VERSION ""

NS_ :

BS_:

BU_: TestTool_HS BCP_HS ECM_HS TCM_HS CGM_HS BCM_HS EBCM_OBD_HS ACCM_HS EBCM_HS TCCM_HS SAS_HS ICCM_OBD_HS ICCM_HS EPS_HS EPB_HS HMIM_HS ONSTAR_HS

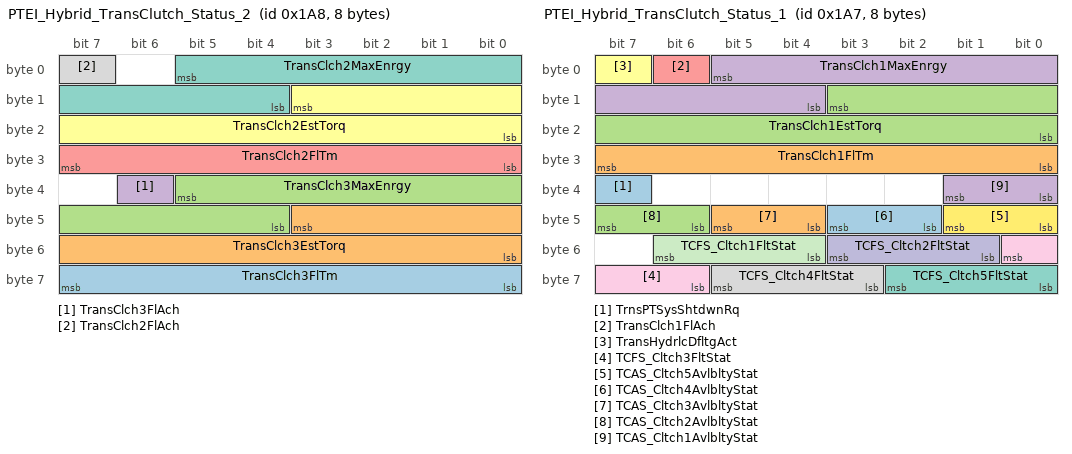
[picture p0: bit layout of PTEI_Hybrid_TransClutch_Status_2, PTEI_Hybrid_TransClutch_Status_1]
BO_ 424 PTEI_Hybrid_TransClutch_Status_2: 8 TCM_HS
 SG_ TransClch3FlTm : 63|8@0+ (0.0125,0) [0|3.1875] "s" Vector__XXX
 SG_ TransClch3EstTorq : 43|12@0+ (0.5,-5) [-5|2042.5] "Nm" Vector__XXX
 SG_ TransClch3MaxEnrgy : 37|10@0+ (50,0) [0|51150] "J" Vector__XXX
 SG_ TransClch3FlAch : 38|1@0+ (1,0) [0|1] "" Vector__XXX
 SG_ TransClch2FlTm : 31|8@0+ (0.0125,0) [0|3.1875] "s" Vector__XXX
 SG_ TransClch2EstTorq : 11|12@0+ (0.5,-5) [-5|2042.5] "Nm" Vector__XXX
 SG_ TransClch2MaxEnrgy : 5|10@0+ (50,0) [0|51150] "J" Vector__XXX
 SG_ TransClch2FlAch : 7|1@0+ (1,0) [0|1] "" Vector__XXX

BO_ 423 PTEI_Hybrid_TransClutch_Status_1: 8 TCM_HS
 SG_ TrnsPTSysShtdwnRq : 39|1@0+ (1,0) [0|1] "" Vector__XXX
 SG_ TransClch1FlTm : 31|8@0+ (0.0125,0) [0|3.1875] "s" Vector__XXX
 SG_ TransClch1EstTorq : 11|12@0+ (0.5,-5) [-5|2042.5] "Nm" Vector__XXX
 SG_ TransClch1MaxEnrgy : 5|10@0+ (50,0) [0|51150] "J" Vector__XXX
 SG_ TransClch1FlAch : 6|1@0+ (1,0) [0|1] "" Vector__XXX
 SG_ TransHydrlcDfltgAct : 7|1@0+ (1,0) [0|1] "" Vector__XXX
 SG_ TCFS_Cltch5FltStat : 58|3@0+ (1,0) [0|7] "" Vector__XXX
 SG_ TCFS_Cltch4FltStat : 61|3@0+ (1,0) [0|7] "" Vector__XXX
 SG_ TCFS_Cltch3FltStat : 48|3@0+ (1,0) [0|7] "" Vector__XXX
 SG_ TCFS_Cltch2FltStat : 51|3@0+ (1,0) [0|7] "" Vector__XXX
 SG_ TCFS_Cltch1FltStat : 54|3@0+ (1,0) [0|7] "" Vector__XXX
 SG_ TCAS_Cltch5AvlbltyStat : 41|2@0+ (1,0) [0|3] "" Vector__XXX
 SG_ TCAS_Cltch4AvlbltyStat : 43|2@0+ (1,0) [0|3] "" Vector__XXX
 SG_ TCAS_Cltch3AvlbltyStat : 45|2@0+ (1,0) [0|3] "" Vector__XXX
 SG_ TCAS_Cltch2AvlbltyStat : 47|2@0+ (1,0) [0|3] "" Vector__XXX
 SG_ TCAS_Cltch1AvlbltyStat : 33|2@0+ (1,0) [0|3] "" Vector__XXX

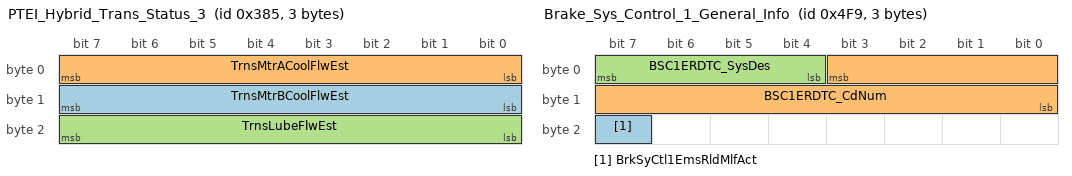
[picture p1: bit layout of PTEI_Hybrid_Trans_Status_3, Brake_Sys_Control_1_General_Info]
BO_ 901 PTEI_Hybrid_Trans_Status_3: 3 TCM_HS
 SG_ TrnsMtrBCoolFlwEst : 15|8@0+ (0.05,0) [0|12.75] "l/min" Vector__XXX
 SG_ TrnsMtrACoolFlwEst : 7|8@0+ (0.05,0) [0|12.75] "l/min" Vector__XXX
 SG_ TrnsLubeFlwEst : 23|8@0+ (0.0625,0) [0|15.9375] "l/min" Vector__XXX

BO_ 1919 DTC_Triggered_77F: 7 TCM_HS
 SG_ DTCI_DTCFaultType_77F : 55|8@0+ (1,0) [0|255] ""  CGM_HS,HMIM_HS,ONSTAR_HS
 SG_ DTCI_CodeSupported_77F : 40|1@0+ (1,0) [0|1] ""  CGM_HS,HMIM_HS,ONSTAR_HS
 SG_ DTCI_CurrentStatus_77F : 41|1@0+ (1,0) [0|1] ""  CGM_HS,HMIM_HS,ONSTAR_HS
 SG_ DTCI_TstNPsdCdClrdSt_77F : 42|1@0+ (1,0) [0|1] ""  CGM_HS,HMIM_HS,ONSTAR_HS
 SG_ DTCI_TstFldCdClrdStat_77F : 43|1@0+ (1,0) [0|1] ""  CGM_HS,HMIM_HS,ONSTAR_HS
 SG_ DTCI_HistStat_77F : 44|1@0+ (1,0) [0|1] ""  CGM_HS,HMIM_HS,ONSTAR_HS
 SG_ DTCI_TstNPsdPwrUpSt_77F : 45|1@0+ (1,0) [0|1] ""  CGM_HS,HMIM_HS,ONSTAR_HS
 SG_ DTCI_TstFldPwrUpSt_77F : 46|1@0+ (1,0) [0|1] ""  CGM_HS,HMIM_HS,ONSTAR_HS
 SG_ DTCI_WrnIndRqdSt_77F : 47|1@0+ (1,0) [0|1] ""  CGM_HS,HMIM_HS,ONSTAR_HS
 SG_ DTCI_DTCFailType_77F : 39|8@0+ (1,0) [0|255] ""  CGM_HS,HMIM_HS,ONSTAR_HS
 SG_ DTCI_DTCNumber_77F : 23|16@0+ (1,0) [0|65535] ""  CGM_HS,HMIM_HS,ONSTAR_HS
 SG_ DTCI_DTCSource_77F : 15|8@0+ (1,0) [0|255] ""  CGM_HS,HMIM_HS,ONSTAR_HS
 SG_ DTCI_DTCTriggered_77F : 0|1@0+ (1,0) [0|1] ""  CGM_HS,HMIM_HS,ONSTAR_HS
 SG_ DTCIUnused7_77F : 1|1@0+ (1,0) [0|1] ""  CGM_HS,HMIM_HS,ONSTAR_HS
 SG_ DTCIUnused6_77F : 2|1@0+ (1,0) [0|1] ""  CGM_HS,HMIM_HS,ONSTAR_HS
 SG_ DTCIUnused5_77F : 3|1@0+ (1,0) [0|1] ""  CGM_HS,HMIM_HS,ONSTAR_HS
 SG_ DTCIUnused4_77F : 4|1@0+ (1,0) [0|1] ""  CGM_HS,HMIM_HS,ONSTAR_HS
 SG_ DTCIUnused3_77F : 5|1@0+ (1,0) [0|1] ""  CGM_HS,HMIM_HS,ONSTAR_HS
 SG_ DTCIUnused2_77F : 6|1@0+ (1,0) [0|1] ""  CGM_HS,HMIM_HS,ONSTAR_HS
 SG_ DTCIUnused1_77F : 7|1@0+ (1,0) [0|1] ""  CGM_HS,HMIM_HS,ONSTAR_HS

BO_ 2026 USDT_Resp_From_TCM_MTA_MTIO_HS: 8 TCM_HS
 SG_ DgnInf : 7|64@0+ (1,0) [0|1.84467440737096E+019] ""  CGM_HS,TestTool_HS,ONSTAR_HS

BO_ 1514 UUDT_Resp_From_TCM_MTA_MTIO_HS: 8 TCM_HS
 SG_ DgnInf : 7|64@0+ (1,0) [0|1.84467440737096E+019] ""  CGM_HS,TestTool_HS,ONSTAR_HS

BO_ 1273 Brake_Sys_Control_1_General_Info: 3 EBCM_HS
 SG_ BrkSyCtl1EmsRldMlfAct : 23|1@0+ (1,0) [0|1] ""  ECM_HS
 SG_ BSC1ERDTC_CdNum : 3|12@0+ (1,0) [0|4095] ""  ECM_HS
 SG_ BSC1ERDTC_SysDes : 7|4@0+ (1,0) [0|15] ""  ECM_HS

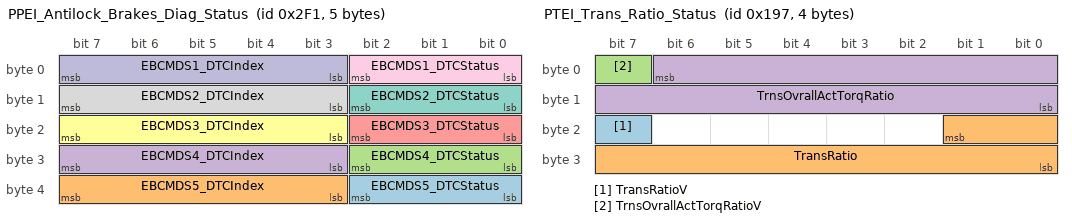
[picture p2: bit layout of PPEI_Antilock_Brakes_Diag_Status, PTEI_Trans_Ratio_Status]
BO_ 753 PPEI_Antilock_Brakes_Diag_Status: 5 EBCM_HS
 SG_ EBCMDS5_DTCStatus : 34|3@0+ (1,0) [0|7] ""  ECM_HS
 SG_ EBCMDS5_DTCIndex : 39|5@0+ (1,0) [0|31] ""  ECM_HS
 SG_ EBCMDS4_DTCStatus : 26|3@0+ (1,0) [0|7] ""  ECM_HS
 SG_ EBCMDS4_DTCIndex : 31|5@0+ (1,0) [0|31] ""  ECM_HS
 SG_ EBCMDS3_DTCStatus : 18|3@0+ (1,0) [0|7] ""  ECM_HS
 SG_ EBCMDS3_DTCIndex : 23|5@0+ (1,0) [0|31] ""  ECM_HS
 SG_ EBCMDS2_DTCStatus : 10|3@0+ (1,0) [0|7] ""  ECM_HS
 SG_ EBCMDS2_DTCIndex : 15|5@0+ (1,0) [0|31] ""  ECM_HS
 SG_ EBCMDS1_DTCStatus : 2|3@0+ (1,0) [0|7] ""  ECM_HS
 SG_ EBCMDS1_DTCIndex : 7|5@0+ (1,0) [0|31] ""  ECM_HS

BO_ 407 PTEI_Trans_Ratio_Status: 4 TCM_HS
 SG_ TransRatioV : 23|1@0+ (1,0) [0|1] ""  ECM_HS
 SG_ TransRatio : 17|10@0+ (0.03125,0) [0|31.96875] ""  ECM_HS
 SG_ TrnsOvrallActTorqRatioV : 7|1@0+ (1,0) [0|1] ""  ECM_HS
 SG_ TrnsOvrallActTorqRatio : 6|15@0- (0.00390625,0) [-64|63.99609375] ""  ECM_HS

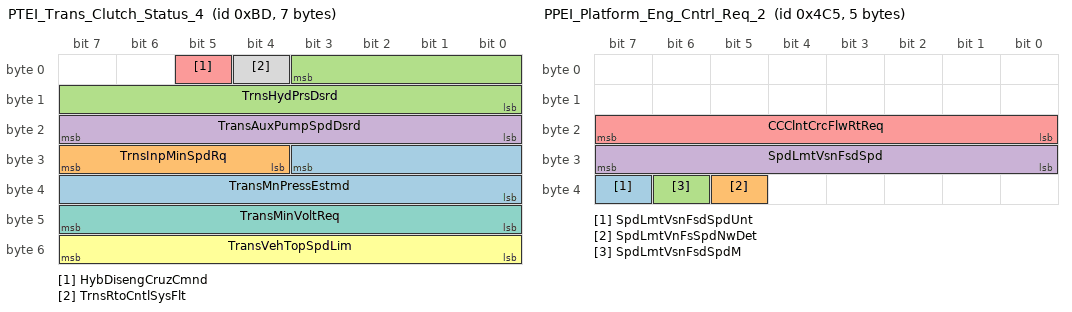
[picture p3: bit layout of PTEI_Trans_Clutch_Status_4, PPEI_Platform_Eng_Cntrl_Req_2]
BO_ 189 PTEI_Trans_Clutch_Status_4: 7 TCM_HS
 SG_ TransMnPressEstmd : 27|12@0+ (0.5,0) [0|2047.5] "kPa"  CGM_HS
 SG_ TrnsInpMinSpdRq : 31|4@0+ (1,0) [0|15] ""  CGM_HS
 SG_ TrnsHydPrsDsrd : 3|12@0+ (0.5,0) [0|2047.5] "kPa"  CGM_HS
 SG_ TransAuxPumpSpdDsrd : 23|8@0+ (0.392157,0) [0|100.000035] "%"  CGM_HS
 SG_ HybDisengCruzCmnd : 5|1@0+ (1,0) [0|1] ""  CGM_HS,ECM_HS
 SG_ TransVehTopSpdLim : 55|8@0+ (2,0) [0|510] "km / h"  CGM_HS,ECM_HS
 SG_ TransMinVoltReq : 47|8@0+ (0.07843,0) [0|19.99965] "volts"  CGM_HS,ECM_HS
 SG_ TrnsRtoCntlSysFlt : 4|1@0+ (1,0) [0|1] ""  CGM_HS,ECM_HS

BO_ 1221 PPEI_Platform_Eng_Cntrl_Req_2: 5 BCM_HS
 SG_ SpdLmtVsnFsdSpdUnt : 39|1@0+ (1,0) [0|1] ""  CGM_HS,ECM_HS
 SG_ SpdLmtVnFsSpdNwDet : 37|1@0+ (1,0) [0|1] ""  CGM_HS,ECM_HS
 SG_ SpdLmtVsnFsdSpdM : 38|1@0+ (1,0) [0|1] ""  CGM_HS,ECM_HS
 SG_ SpdLmtVsnFsdSpd : 31|8@0+ (1,0) [0|255] ""  CGM_HS,ECM_HS
 SG_ CCClntCrcFlwRtReq : 23|8@0+ (0.392157,0) [0|100.000035] "%"  CGM_HS,ECM_HS

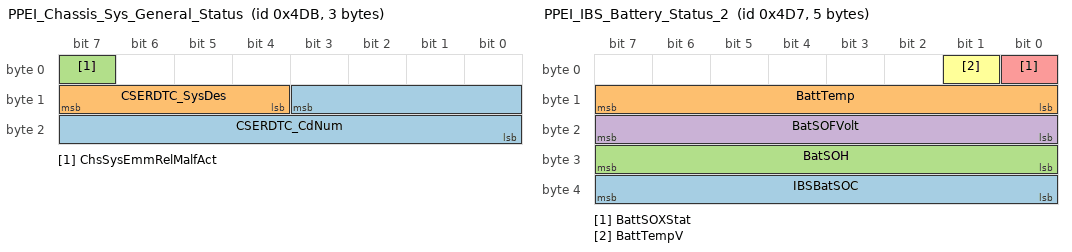
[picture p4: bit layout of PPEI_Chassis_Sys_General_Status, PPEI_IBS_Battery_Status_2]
BO_ 1243 PPEI_Chassis_Sys_General_Status: 3 ICCM_HS
 SG_ CSERDTC_CdNum : 11|12@0+ (1,0) [0|4095] ""  ECM_HS
 SG_ CSERDTC_SysDes : 15|4@0+ (1,0) [0|15] ""  ECM_HS
 SG_ ChsSysEmmRelMalfAct : 7|1@0+ (1,0) [0|1] ""  ECM_HS

BO_ 1239 PPEI_IBS_Battery_Status_2: 5 BCM_HS
 SG_ IBSBatSOC : 39|8@0+ (0.392157,0) [0|100.000035] "%"  ECM_HS
 SG_ BattTemp : 15|8@0+ (1,-40) [-40|215] "deg C"  ECM_HS
 SG_ BatSOH : 31|8@0+ (0.392157,0) [0|100.000035] "%"  ECM_HS
 SG_ BatSOFVolt : 23|8@0+ (0.05,0) [0|12.75] "volts"  ECM_HS
 SG_ BattSOXStat : 0|1@0+ (1,0) [0|1] ""  ECM_HS
 SG_ BattTempV : 1|1@0+ (1,0) [0|1] ""  ECM_HS

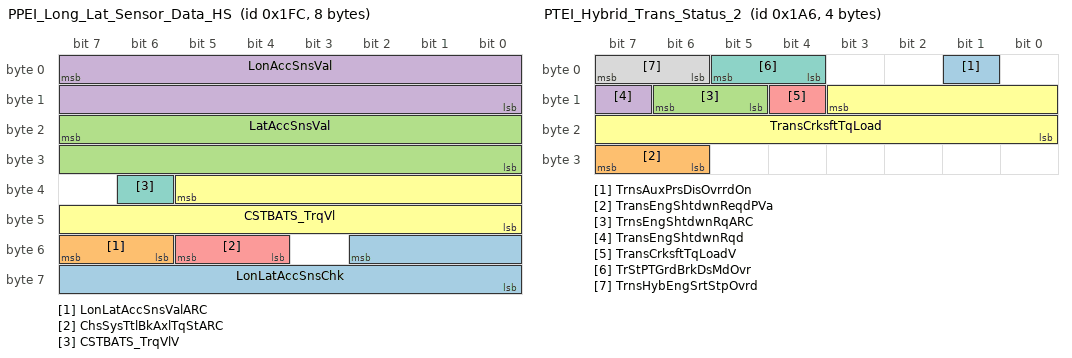
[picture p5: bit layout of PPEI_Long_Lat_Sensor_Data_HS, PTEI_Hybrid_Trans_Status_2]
BO_ 508 PPEI_Long_Lat_Sensor_Data_HS: 8 EBCM_HS
 SG_ LonLatAccSnsChk : 50|11@0+ (1,0) [0|2047] ""  ICCM_OBD_HS,ICCM_HS,TCM_HS,ECM_HS
 SG_ LonLatAccSnsValARC : 55|2@0+ (1,0) [0|3] ""  ICCM_OBD_HS,ICCM_HS,TCM_HS,ECM_HS
 SG_ LatAccSnsVal : 23|16@0- (0.00012207,0) [-3.99998976|3.99986769] "g's"  ICCM_OBD_HS,ICCM_HS,TCM_HS,ECM_HS
 SG_ LonAccSnsVal : 7|16@0- (0.00012207,0) [-3.99998976|3.99986769] "g's"  ICCM_OBD_HS,ICCM_HS,TCM_HS,ECM_HS
 SG_ ChsSysTtlBkAxlTqStARC : 53|2@0+ (1,0) [0|3] ""  ECM_HS
 SG_ CSTBATS_TrqVl : 37|14@0+ (2,0) [0|32766] "Nm"  ICCM_OBD_HS,ICCM_HS,TCM_HS,ECM_HS
 SG_ CSTBATS_TrqVlV : 38|1@0+ (1,0) [0|1] ""  ICCM_OBD_HS,ICCM_HS,TCM_HS,ECM_HS

BO_ 422 PTEI_Hybrid_Trans_Status_2: 4 TCM_HS
 SG_ TrnsAuxPrsDisOvrrdOn : 1|1@0+ (1,0) [0|1] ""  ECM_HS
 SG_ TransEngShtdwnReqdPVa : 31|2@0+ (1,0) [0|3] ""  ECM_HS
 SG_ TrnsEngShtdwnRqARC : 14|2@0+ (1,0) [0|3] ""  ECM_HS
 SG_ TransEngShtdwnRqd : 15|1@0+ (1,0) [0|1] ""  ECM_HS
 SG_ TransCrksftTqLoadV : 12|1@0+ (1,0) [0|1] ""  ECM_HS
 SG_ TransCrksftTqLoad : 11|12@0+ (0.5,-848) [-848|1199.5] "Nm"  ECM_HS
 SG_ TrStPTGrdBrkDsMdOvr : 5|2@0+ (1,0) [0|3] ""  ECM_HS
 SG_ TrnsHybEngSrtStpOvrd : 7|2@0+ (1,0) [0|3] ""  BCP_HS,ECM_HS

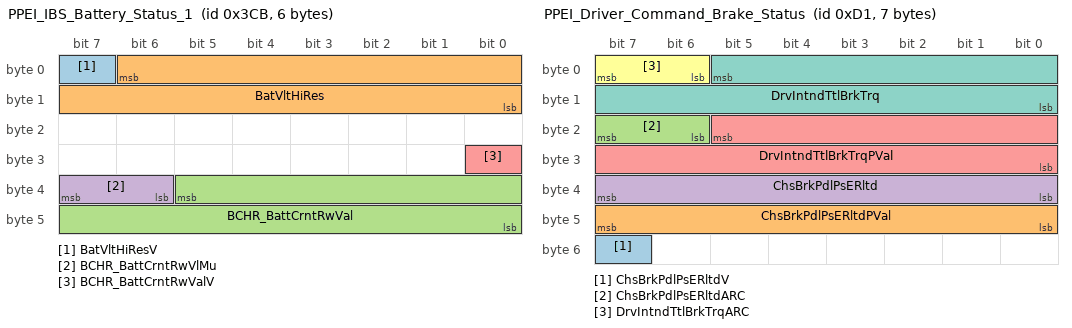
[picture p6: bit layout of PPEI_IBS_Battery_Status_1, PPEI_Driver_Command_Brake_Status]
BO_ 971 PPEI_IBS_Battery_Status_1: 6 BCM_HS
 SG_ BatVltHiResV : 7|1@0+ (1,0) [0|1] ""  ECM_HS
 SG_ BatVltHiRes : 6|15@0+ (0.001,0) [0|32.767] "volts"  ECM_HS
 SG_ BCHR_BattCrntRwVal : 37|14@0+ (0.001,-8.192) [-8.192|8.191] ""  ECM_HS
 SG_ BCHR_BattCrntRwVlMu : 39|2@0+ (1,0) [0|3] ""  ECM_HS
 SG_ BCHR_BattCrntRwValV : 24|1@0+ (1,0) [0|1] ""  ECM_HS

BO_ 209 PPEI_Driver_Command_Brake_Status: 7 EBCM_HS
 SG_ ChsBrkPdlPsERltdV : 55|1@0+ (1,0) [0|1] ""  ECM_HS
 SG_ ChsBrkPdlPsERltdPVal : 47|8@0+ (1,0) [0|255] ""  ECM_HS
 SG_ ChsBrkPdlPsERltdARC : 23|2@0+ (1,0) [0|3] ""  ECM_HS
 SG_ ChsBrkPdlPsERltd : 39|8@0+ (0.392157,0) [0|100.000035] "%"  ECM_HS
 SG_ DrvIntndTtlBrkTrqPVal : 21|14@0+ (1,0) [0|16383] ""  ECM_HS
 SG_ DrvIntndTtlBrkTrqARC : 7|2@0+ (1,0) [0|3] ""  ECM_HS
 SG_ DrvIntndTtlBrkTrq : 5|14@0+ (2,0) [0|32766] "Nm"  ECM_HS

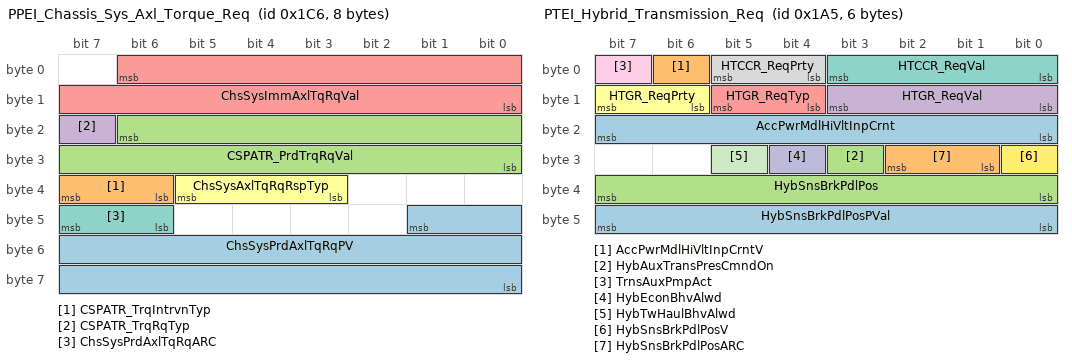
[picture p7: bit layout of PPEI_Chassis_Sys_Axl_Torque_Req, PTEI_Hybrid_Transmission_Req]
BO_ 454 PPEI_Chassis_Sys_Axl_Torque_Req: 8 EBCM_HS
 SG_ ChsSysPrdAxlTqRqPV : 41|18@0+ (1,0) [0|262143] ""  ECM_HS
 SG_ CSPATR_TrqIntrvnTyp : 39|2@0+ (1,0) [0|3] ""  ECM_HS
 SG_ CSPATR_PrdTrqRqVal : 22|15@0+ (2,-22534) [-22534|43000] "Nm"  ECM_HS
 SG_ CSPATR_TrqRqTyp : 23|1@0+ (1,0) [0|1] ""  ECM_HS
 SG_ ChsSysImmAxlTqRqVal : 6|15@0+ (2,-22534) [-22534|43000] "Nm"  ECM_HS
 SG_ ChsSysAxlTqRqRspTyp : 37|3@0+ (1,0) [0|7] ""  ECM_HS
 SG_ ChsSysPrdAxlTqRqARC : 47|2@0+ (1,0) [0|3] ""  ECM_HS

BO_ 1189 PTEI_Trans_General_Status_3_HS: 1 TCM_HS
 SG_ TAFR_AirFlwReqTyp : 1|2@0+ (1,0) [0|3] ""  ECM_HS
 SG_ TAFR_AirFlwReqPrcnt : 7|6@0+ (1.5873,0) [0|99.9999] "%"  ECM_HS

BO_ 421 PTEI_Hybrid_Transmission_Req: 6 BCP_HS
 SG_ AccPwrMdlHiVltInpCrnt : 23|8@0+ (0.125,-5) [-5|26.875] "A" Vector__XXX
 SG_ AccPwrMdlHiVltInpCrntV : 6|1@0+ (1,0) [0|1] "" Vector__XXX
 SG_ HybAuxTransPresCmndOn : 27|1@0+ (1,0) [0|1] ""  TCM_HS
 SG_ HTGR_ReqVal : 11|4@0+ (1,0) [0|15] ""  TCM_HS
 SG_ HTGR_ReqTyp : 13|2@0+ (1,0) [0|3] ""  TCM_HS
 SG_ HTGR_ReqPrty : 15|2@0+ (1,0) [0|3] ""  TCM_HS
 SG_ HTCCR_ReqVal : 3|4@0+ (1,0) [0|15] ""  TCM_HS
 SG_ HTCCR_ReqPrty : 5|2@0+ (1,0) [0|3] ""  TCM_HS
 SG_ TrnsAuxPmpAct : 7|1@0+ (1,0) [0|1] ""  TCM_HS
 SG_ HybEconBhvAlwd : 28|1@0+ (1,0) [0|1] ""  TCM_HS
 SG_ HybTwHaulBhvAlwd : 29|1@0+ (1,0) [0|1] ""  TCM_HS
 SG_ HybSnsBrkPdlPosV : 24|1@0+ (1,0) [0|1] ""  ICCM_OBD_HS,ICCM_HS,TCM_HS,ECM_HS
 SG_ HybSnsBrkPdlPosPVal : 47|8@0+ (1,0) [0|255] ""  ICCM_OBD_HS,ICCM_HS,TCM_HS,ECM_HS
 SG_ HybSnsBrkPdlPosARC : 26|2@0+ (1,0) [0|3] ""  ICCM_OBD_HS,ICCM_HS,TCM_HS,ECM_HS
 SG_ HybSnsBrkPdlPos : 39|8@0+ (0.392157,0) [0|100.000035] "%"  ICCM_OBD_HS,ICCM_HS,TCM_HS,ECM_HS

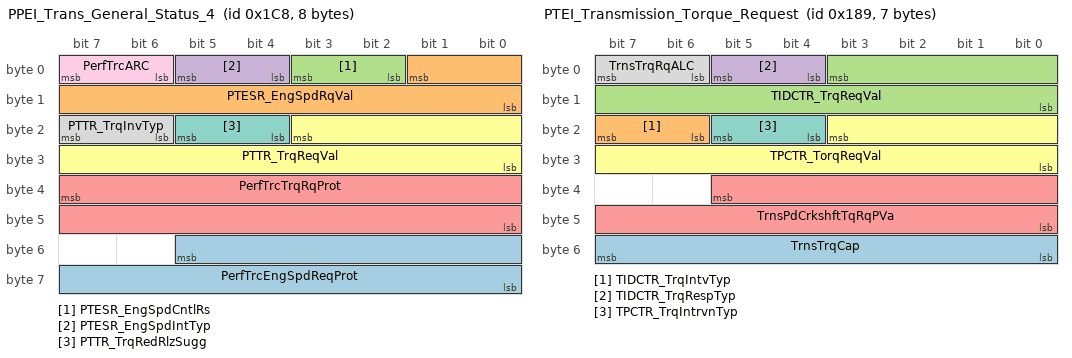
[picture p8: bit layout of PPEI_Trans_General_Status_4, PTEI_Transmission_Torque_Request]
BO_ 456 PPEI_Trans_General_Status_4: 8 EBCM_HS
 SG_ PerfTrcEngSpdReqProt : 53|14@0+ (1,0) [0|16383] ""  CGM_HS,ECM_HS
 SG_ PTESR_EngSpdRqVal : 1|10@0+ (8,0) [0|8184] "rpm"  CGM_HS,ECM_HS
 SG_ PTESR_EngSpdCntlRs : 3|2@0+ (1,0) [0|3] ""  CGM_HS,ECM_HS
 SG_ PTESR_EngSpdIntTyp : 5|2@0+ (1,0) [0|3] ""  CGM_HS,ECM_HS
 SG_ PerfTrcTrqRqProt : 39|16@0+ (1,0) [0|65535] ""  CGM_HS,ECM_HS
 SG_ PTTR_TrqReqVal : 19|12@0+ (0.5,-848) [-848|1199.5] "Nm"  CGM_HS,ICCM_OBD_HS,ICCM_HS,ECM_HS
 SG_ PTTR_TrqRedRlzSugg : 21|2@0+ (1,0) [0|3] ""  CGM_HS,ICCM_OBD_HS,ICCM_HS,ECM_HS
 SG_ PTTR_TrqInvTyp : 23|2@0+ (1,0) [0|3] ""  CGM_HS,ICCM_OBD_HS,ICCM_HS,ECM_HS
 SG_ PerfTrcARC : 7|2@0+ (1,0) [0|3] ""  CGM_HS,ECM_HS

BO_ 393 PTEI_Transmission_Torque_Request: 7 TCM_HS
 SG_ TrnsTrqCap : 55|8@0+ (4,0) [0|1020] "Nm"  ECM_HS
 SG_ TIDCTR_TrqIntvTyp : 23|2@0+ (1,0) [0|3] ""  ECM_HS
 SG_ TIDCTR_TrqReqVal : 3|12@0+ (0.5,-848) [-848|1199.5] "Nm"  ECM_HS
 SG_ TIDCTR_TrqRespTyp : 5|2@0+ (1,0) [0|3] ""  ECM_HS
 SG_ TrnsPdCrkshftTqRqPVa : 37|14@0+ (1,0) [0|16383] ""  ECM_HS
 SG_ TPCTR_TorqReqVal : 19|12@0+ (0.5,-848) [-848|1199.5] "Nm"  ECM_HS
 SG_ TPCTR_TrqIntrvnTyp : 21|2@0+ (1,0) [0|3] ""  ECM_HS
 SG_ TrnsTrqRqALC : 7|2@0+ (1,0) [0|3] ""  ECM_HS

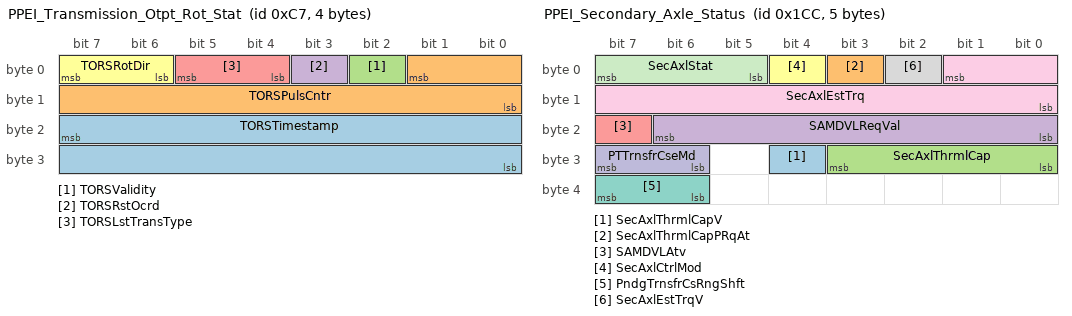
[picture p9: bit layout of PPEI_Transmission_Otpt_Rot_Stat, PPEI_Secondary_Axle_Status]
BO_ 199 PPEI_Transmission_Otpt_Rot_Stat: 4 TCM_HS
 SG_ TORSTimestamp : 23|16@0+ (1,0) [0|65535] "counts"  ICCM_OBD_HS,EBCM_OBD_HS,BCP_HS,ICCM_HS,TCCM_HS,EBCM_HS,ECM_HS
 SG_ TORSPulsCntr : 1|10@0+ (1,0) [0|1023] "counts"  ICCM_OBD_HS,EBCM_OBD_HS,BCP_HS,ICCM_HS,TCCM_HS,EBCM_HS,ECM_HS
 SG_ TORSValidity : 2|1@0+ (1,0) [0|1] ""  ICCM_OBD_HS,EBCM_OBD_HS,BCP_HS,ICCM_HS,TCCM_HS,EBCM_HS,ECM_HS
 SG_ TORSRstOcrd : 3|1@0+ (1,0) [0|1] ""  ICCM_OBD_HS,EBCM_OBD_HS,BCP_HS,ICCM_HS,TCCM_HS,EBCM_HS,ECM_HS
 SG_ TORSLstTransType : 5|2@0+ (1,0) [0|3] ""  ICCM_OBD_HS,EBCM_OBD_HS,BCP_HS,ICCM_HS,TCCM_HS,EBCM_HS,ECM_HS
 SG_ TORSRotDir : 7|2@0+ (1,0) [0|3] ""  ICCM_OBD_HS,EBCM_OBD_HS,BCP_HS,ICCM_HS,TCCM_HS,EBCM_HS,ECM_HS

BO_ 390 PTEI_Hybrid_Status_1: 7 BCP_HS
 SG_ RdHVInvRatVltV : 7|1@0+ (1,0) [0|1] "" Vector__XXX
 SG_ RdHVInvRatVlt : 40|9@0+ (1,0) [0|511] "volts" Vector__XXX
 SG_ RdPTHVCntrReq : 3|2@0+ (1,0) [0|3] "" Vector__XXX
 SG_ TransFldPmpMtrDrtd : 26|1@0+ (1,0) [0|1] ""  TCM_HS
 SG_ EstMtrPwrLossV : 30|1@0+ (1,0) [0|1] ""  TCM_HS
 SG_ EstMtrPwrLoss : 39|8@0+ (0.25,0) [0|63.75] "kW"  TCM_HS
 SG_ HybGrdBrkgAct : 25|1@0+ (1,0) [0|1] ""  TCM_HS
 SG_ HybCrpCstCrvRq : 43|3@0+ (1,0) [0|7] ""  ECM_HS
 SG_ EngActDmpgDsblReq : 27|1@0+ (1,0) [0|1] ""  ECM_HS
 SG_ HybRdcdTrqCapMd1Cmnd : 5|1@0+ (1,0) [0|1] ""  ECM_HS
 SG_ HybExtndDcFuelCORq : 31|1@0+ (1,0) [0|1] ""  ECM_HS
 SG_ HybCmmFailRdPwrCmd : 4|1@0+ (1,0) [0|1] ""  ECM_HS
 SG_ HybCmmdEngTrqLmtd : 23|8@0+ (0.75,-90) [-90|101.25] "Nm"  ECM_HS
 SG_ HybACCompRq : 29|2@0+ (1,0) [0|3] ""  ECM_HS
 SG_ HESSI_EngStrtTyp : 11|4@0+ (1,0) [0|15] ""  ECM_HS
 SG_ HESSI_EngStrtStpMd : 15|4@0+ (1,0) [0|15] ""  ECM_HS
 SG_ HybCrnkAbrtd : 0|1@0+ (1,0) [0|1] ""  ECM_HS
 SG_ CnvntlEngStrtEnbld : 1|1@0+ (1,0) [0|1] ""  ECM_HS
 SG_ HybDFCOReq : 6|1@0+ (1,0) [0|1] ""  ECM_HS

BO_ 460 PPEI_Secondary_Axle_Status: 5 TCCM_HS
 SG_ SecAxlThrmlCapV : 28|1@0+ (1,0) [0|1] ""  CGM_HS,EBCM_OBD_HS,EBCM_HS
 SG_ SecAxlThrmlCapPRqAt : 3|1@0+ (1,0) [0|1] ""  CGM_HS,EBCM_OBD_HS,EBCM_HS
 SG_ SecAxlThrmlCap : 27|4@0+ (6.7,0) [0|100.5] "%"  CGM_HS,EBCM_OBD_HS,EBCM_HS
 SG_ SAMDVLReqVal : 22|7@0+ (2,0) [0|254] ""  CGM_HS,EBCM_OBD_HS,EBCM_HS
 SG_ SAMDVLAtv : 23|1@0+ (1,0) [0|1] ""  CGM_HS,EBCM_OBD_HS,EBCM_HS
 SG_ SecAxlCtrlMod : 4|1@0+ (1,0) [0|1] ""  CGM_HS,EBCM_OBD_HS,EBCM_HS
 SG_ PndgTrnsfrCsRngShft : 39|2@0+ (1,0) [0|3] ""  CGM_HS,ECM_HS
 SG_ SecAxlEstTrqV : 2|1@0+ (1,0) [0|1] ""  CGM_HS,EBCM_OBD_HS,EBCM_HS,ECM_HS
 SG_ SecAxlEstTrq : 1|10@0+ (10,0) [0|10230] "Nm"  CGM_HS,EBCM_OBD_HS,EBCM_HS,ECM_HS
 SG_ PTTrnsfrCseMd : 31|2@0+ (1,0) [0|3] ""  CGM_HS,TCM_HS,ECM_HS
 SG_ SecAxlStat : 7|3@0+ (1,0) [0|7] ""  CGM_HS,EBCM_OBD_HS,EBCM_HS

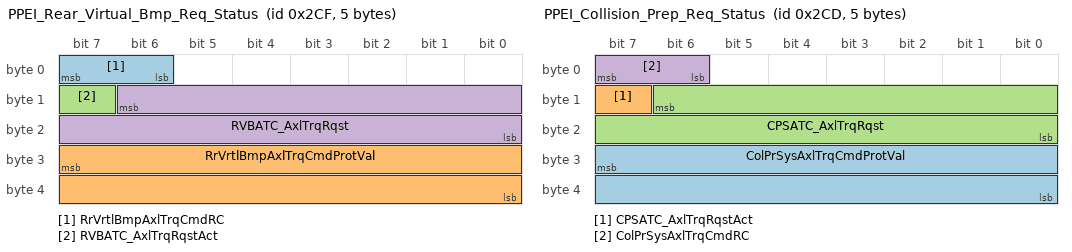
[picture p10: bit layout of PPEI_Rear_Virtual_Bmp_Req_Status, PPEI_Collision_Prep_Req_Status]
BO_ 719 PPEI_Rear_Virtual_Bmp_Req_Status: 5 CGM_HS
 SG_ RrVrtlBmpAxlTrqCmdRC : 7|2@0+ (1,0) [0|3] ""  ECM_HS
 SG_ RrVrtlBmpAxlTrqCmdProtVal : 31|16@0+ (1,0) [0|65535] ""  ECM_HS
 SG_ RVBATC_AxlTrqRqstAct : 15|1@0+ (1,0) [0|1] ""  ECM_HS
 SG_ RVBATC_AxlTrqRqst : 14|15@0+ (2,-22534) [-22534|43000] "NM"  ECM_HS

BO_ 717 PPEI_Collision_Prep_Req_Status: 5 CGM_HS
 SG_ ColPrSysAxlTrqCmdProtVal : 31|16@0+ (1,0) [0|65535] ""  ECM_HS
 SG_ CPSATC_AxlTrqRqstAct : 15|1@0+ (1,0) [0|1] ""  ECM_HS
 SG_ CPSATC_AxlTrqRqst : 14|15@0+ (2,-22534) [-22534|43000] "NM"  ECM_HS
 SG_ ColPrSysAxlTrqCmdRC : 7|2@0+ (1,0) [0|3] ""  ECM_HS

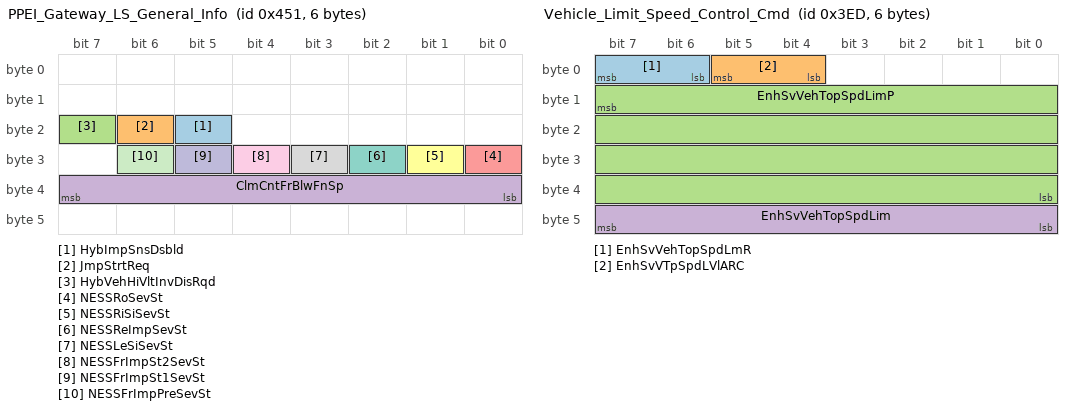
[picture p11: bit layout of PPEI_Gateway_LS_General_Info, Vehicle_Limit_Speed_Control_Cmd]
BO_ 1105 PPEI_Gateway_LS_General_Info: 6 BCM_HS
 SG_ HybImpSnsDsbld : 21|1@0+ (1,0) [0|1] ""  BCP_HS
 SG_ JmpStrtReq : 22|1@0+ (1,0) [0|1] ""  BCP_HS
 SG_ HybVehHiVltInvDisRqd : 23|1@0+ (1,0) [0|1] ""  BCP_HS
 SG_ ClmCntFrBlwFnSp : 39|8@0+ (0.392157,0) [0|100.000035] "%"  EBCM_OBD_HS,BCP_HS,EBCM_HS
 SG_ NESSRoSevSt : 24|1@0+ (1,0) [0|1] ""  BCP_HS,ECM_HS
 SG_ NESSRiSiSevSt : 25|1@0+ (1,0) [0|1] ""  BCP_HS,ECM_HS
 SG_ NESSReImpSevSt : 26|1@0+ (1,0) [0|1] ""  BCP_HS,ECM_HS
 SG_ NESSLeSiSevSt : 27|1@0+ (1,0) [0|1] ""  BCP_HS,ECM_HS
 SG_ NESSFrImpSt2SevSt : 28|1@0+ (1,0) [0|1] ""  BCP_HS,ECM_HS
 SG_ NESSFrImpSt1SevSt : 29|1@0+ (1,0) [0|1] ""  BCP_HS,ECM_HS
 SG_ NESSFrImpPreSevSt : 30|1@0+ (1,0) [0|1] ""  BCP_HS,ECM_HS

BO_ 1005 Vehicle_Limit_Speed_Control_Cmd: 6 ONSTAR_HS
 SG_ EnhSvVehTopSpdLmR : 7|2@0+ (1,0) [0|3] ""  ECM_HS
 SG_ EnhSvVTpSpdLVlARC : 5|2@0+ (1,0) [0|3] ""  ECM_HS
 SG_ EnhSvVehTopSpdLimP : 15|32@0+ (1,0) [0|4294967295] ""  ECM_HS
 SG_ EnhSvVehTopSpdLim : 47|8@0+ (2,0) [0|510] "km / h"  ECM_HS

BO_ 688 Starter_Generator_Status_3: 5 BCP_HS
 SG_ StrtrGenSpdV : 39|1@0+ (1,0) [0|1] ""  EBCM_OBD_HS,EBCM_HS,ECM_HS
 SG_ StrtrGenSpd : 21|14@0+ (1,0) [0|16383] "rpm"  EBCM_OBD_HS,EBCM_HS,ECM_HS

BO_ 431 PTEI_Trans_General_Status_2: 8 TCM_HS
 SG_ TrnsInpCltchStatV : 39|1@0+ (1,0) [0|1] ""  ECM_HS
 SG_ TransCrnkPermsnStatV : 23|1@0+ (1,0) [0|1] ""  ECM_HS
 SG_ TransVehTopSpdLim : 63|8@0+ (2,0) [0|510] "km / h"  ECM_HS
 SG_ TransMinVoltReq : 55|8@0+ (0.07843,0) [0|19.99965] "volts"  ECM_HS
 SG_ TDslPrtFltrIdlRgtnMdAtv : 6|1@0+ (1,0) [0|1] ""  ECM_HS
 SG_ DrvlneTrqStabStat : 38|3@0+ (1,0) [0|7] ""  ECM_HS
 SG_ TrnsTrqCnvCltCmdMdF : 19|1@0+ (1,0) [0|1] ""  ECM_HS
 SG_ AutoTransGrSftDirectFl : 16|1@0+ (1,0) [0|1] ""  ECM_HS
 SG_ AutoTransGrSftDirect : 18|2@0+ (1,0) [0|3] ""  ECM_HS
 SG_ TrnsTrqCnvCltCmndMd : 22|3@0+ (1,0) [0|7] ""  ECM_HS
 SG_ TrnsTrqCnvCltDsrSlp : 35|12@0- (1,0) [-2048|2047] "rpm"  ECM_HS
 SG_ TrnsStWntrMdOvrd : 25|2@0+ (1,0) [0|3] ""  ECM_HS
 SG_ TrnsStTwHaulMdOvrd : 27|2@0+ (1,0) [0|3] ""  ECM_HS
 SG_ TrnsStSprtMdOvrd : 29|2@0+ (1,0) [0|3] ""  ECM_HS
 SG_ TrnsStEconMdOvrd : 31|2@0+ (1,0) [0|3] ""  ECM_HS
 SG_ TrnsInpCltchStat : 2|3@0+ (1,0) [0|7] ""  ECM_HS
 SG_ TrnsAntcptdCrpTrqRRnV : 7|1@0+ (1,0) [0|1] ""  ECM_HS
 SG_ TrnsAntcptdCrpTrqRRn : 15|8@0+ (0.5,0) [0|127.5] "Nm"  ECM_HS
 SG_ TrnCltAdpAtv : 3|1@0+ (1,0) [0|1] ""  ECM_HS
 SG_ TransCrnkPermsnStat : 5|1@0+ (1,0) [0|1] ""  ECM_HS
 SG_ WrmUpShftPtrn : 4|1@0+ (1,0) [0|1] ""  ECM_HS

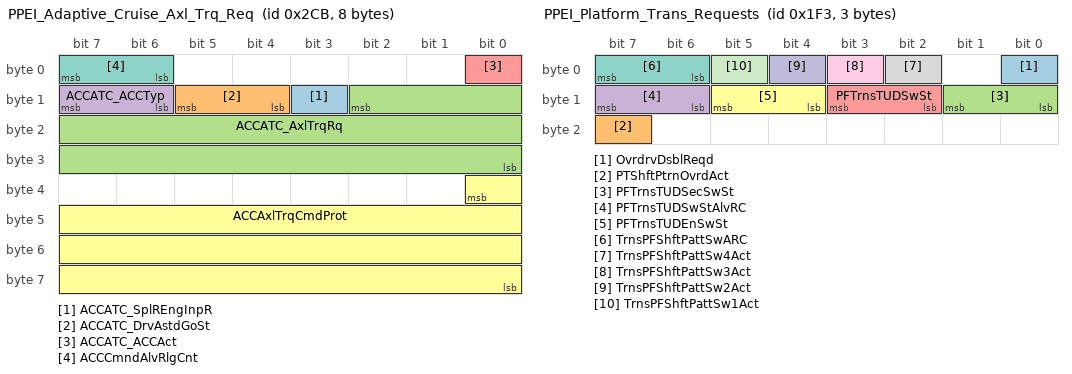
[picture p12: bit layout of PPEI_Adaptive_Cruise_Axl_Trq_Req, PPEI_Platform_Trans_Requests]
BO_ 715 PPEI_Adaptive_Cruise_Axl_Trq_Req: 8 CGM_HS
 SG_ ACCATC_SplREngInpR : 11|1@0+ (1,0) [0|1] ""  ECM_HS
 SG_ ACCATC_DrvAstdGoSt : 13|2@0+ (1,0) [0|3] ""  ECM_HS
 SG_ ACCATC_AxlTrqRq : 10|19@0+ (0.125,-22534) [-22534|43001.875] "Nm"  ECM_HS
 SG_ ACCATC_ACCTyp : 15|2@0+ (1,0) [0|3] ""  ECM_HS
 SG_ ACCATC_ACCAct : 0|1@0+ (1,0) [0|1] ""  ECM_HS
 SG_ ACCAxlTrqCmdProt : 32|25@0+ (1,0) [0|33554431] ""  ECM_HS
 SG_ ACCCmndAlvRlgCnt : 7|2@0+ (1,0) [0|3] ""  ECM_HS

BO_ 320 Exterior_Lighting_HS: 3 BCM_HS
 SG_ Ky_IdDevPrgmAuthReq : 14|1@0+ (1,0) [0|1] ""  CGM_HS,EPS_HS
 SG_ ClmnLckStatV : 15|1@0+ (1,0) [0|1] ""  CGM_HS,EPS_HS
 SG_ ClmnLckStat : 21|2@0+ (1,0) [0|3] ""  CGM_HS,EPS_HS
 SG_ AutoBmSlctAllwd : 13|1@0+ (1,0) [0|1] ""  CGM_HS
 SG_ BrkLtsAtv : 6|1@0+ (1,0) [0|1] ""  CGM_HS
 SG_ RrFogLmpsAct : 8|1@0+ (1,0) [0|1] ""  CGM_HS
 SG_ OtsdAmbtLtLvlStatV : 2|1@0+ (1,0) [0|1] ""  CGM_HS
 SG_ OtsdAmbtLtLvlStat : 17|2@0+ (1,0) [0|3] ""  CGM_HS
 SG_ MainLghtSw : 12|2@0+ (1,0) [0|3] "N/A"  CGM_HS
 SG_ LowBmAct : 1|1@0+ (1,0) [0|1] ""  CGM_HS
 SG_ HighBmAct : 7|1@0+ (1,0) [0|1] ""  CGM_HS
 SG_ HdlmpBmSelectStat : 10|2@0+ (1,0) [0|3] ""  CGM_HS
 SG_ FlToPsSwAtv : 5|1@0+ (1,0) [0|1] ""  CGM_HS
 SG_ AdvFrntLghtSysEnbld : 3|1@0+ (1,0) [0|1] ""  CGM_HS
 SG_ FrFogLmpsAct : 0|1@0+ (1,0) [0|1] ""  CGM_HS
 SG_ AutLghtCtrl : 4|1@0+ (1,0) [0|1] "N/A"  CGM_HS
 SG_ TrnSwAct : 19|2@0+ (1,0) [0|3] ""  CGM_HS,EBCM_OBD_HS,EBCM_HS,ECM_HS

BO_ 499 PPEI_Platform_Trans_Requests: 3 BCM_HS
 SG_ OvrdrvDsblReqd : 0|1@0+ (1,0) [0|1] "" Vector__XXX
 SG_ PTShftPtrnOvrdAct : 23|1@0+ (1,0) [0|1] ""  TCM_HS
 SG_ PFTrnsTUDSecSwSt : 9|2@0+ (1,0) [0|3] ""  TCM_HS
 SG_ PFTrnsTUDSwStAlvRC : 15|2@0+ (1,0) [0|3] ""  TCM_HS
 SG_ PFTrnsTUDSwSt : 11|2@0+ (1,0) [0|3] ""  TCM_HS
 SG_ PFTrnsTUDEnSwSt : 13|2@0+ (1,0) [0|3] ""  TCM_HS
 SG_ TrnsPFShftPattSwARC : 7|2@0+ (1,0) [0|3] ""  TCM_HS,ECM_HS
 SG_ TrnsPFShftPattSw4Act : 2|1@0+ (1,0) [0|1] ""  TCM_HS,ECM_HS
 SG_ TrnsPFShftPattSw3Act : 3|1@0+ (1,0) [0|1] ""  TCM_HS,ECM_HS
 SG_ TrnsPFShftPattSw2Act : 4|1@0+ (1,0) [0|1] ""  TCM_HS,ECM_HS
 SG_ TrnsPFShftPattSw1Act : 5|1@0+ (1,0) [0|1] ""  TCM_HS,ECM_HS

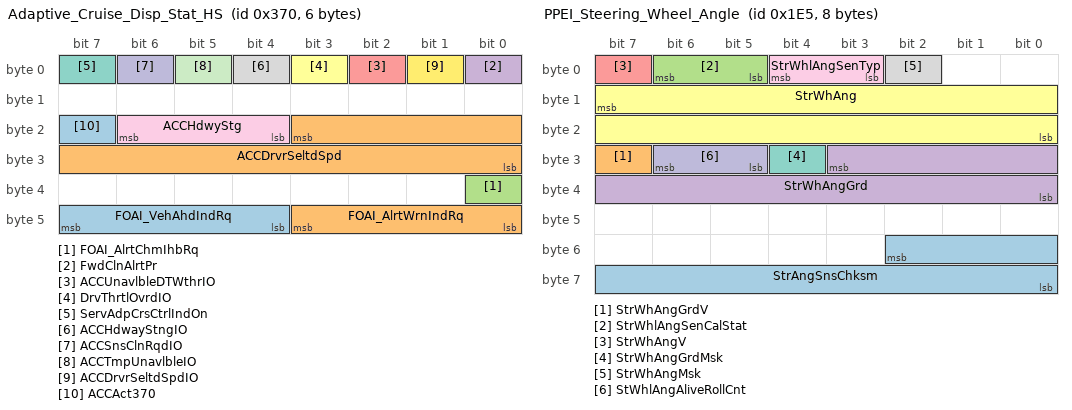
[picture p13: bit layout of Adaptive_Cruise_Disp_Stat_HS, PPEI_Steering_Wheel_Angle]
BO_ 880 Adaptive_Cruise_Disp_Stat_HS: 6 CGM_HS
 SG_ FOAI_VehAhdIndRq : 47|4@0+ (1,0) [0|15] ""  BCM_HS
 SG_ FOAI_AlrtWrnIndRq : 43|4@0+ (1,0) [0|15] ""  BCM_HS
 SG_ FOAI_AlrtChmIhbRq : 32|1@0+ (1,0) [0|1] ""  BCM_HS
 SG_ FwdClnAlrtPr : 0|1@0+ (1,0) [0|1] ""  BCM_HS
 SG_ ACCUnavlbleDTWthrIO : 2|1@0+ (1,0) [0|1] ""  BCM_HS
 SG_ DrvThrtlOvrdIO : 3|1@0+ (1,0) [0|1] ""  BCM_HS
 SG_ ServAdpCrsCtrlIndOn : 7|1@0+ (1,0) [0|1] ""  BCM_HS
 SG_ ACCHdwayStngIO : 4|1@0+ (1,0) [0|1] ""  BCM_HS
 SG_ ACCHdwyStg : 22|3@0+ (1,0) [0|7] ""  BCM_HS
 SG_ ACCSnsClnRqdIO : 6|1@0+ (1,0) [0|1] ""  BCM_HS
 SG_ ACCTmpUnavlbleIO : 5|1@0+ (1,0) [0|1] ""  BCM_HS
 SG_ ACCDrvrSeltdSpdIO : 1|1@0+ (1,0) [0|1] ""  BCM_HS
 SG_ ACCAct370 : 23|1@0+ (1,0) [0|1] ""  EBCM_OBD_HS,EBCM_HS,BCM_HS,TCM_HS
 SG_ ACCDrvrSeltdSpd : 19|12@0+ (0.0625,0) [0|255.9375] "km / h"  BCM_HS,ECM_HS

BO_ 298 Body_Information_HS: 8 BCM_HS
 SG_ ChmAct : 55|1@0+ (1,0) [0|1] ""  CGM_HS
 SG_ Ky_IdDevPr : 56|1@0+ (1,0) [0|1] ""  CGM_HS,EBCM_OBD_HS,EPB_HS,EBCM_HS
 SG_ CrshAlrtDrvrSlctdType : 5|1@0+ (1,0) [0|1] ""  CGM_HS,EBCM_OBD_HS,EBCM_HS
 SG_ PsSbltAtcV : 54|1@0+ (1,0) [0|1] ""  CGM_HS,EBCM_OBD_HS,EBCM_HS
 SG_ PsSbltAtc : 53|1@0+ (1,0) [0|1] ""  CGM_HS,EBCM_OBD_HS,EBCM_HS
 SG_ TrlrBrkDsplyAct : 51|1@0+ (1,0) [0|1] ""  CGM_HS,ICCM_OBD_HS,ICCM_HS
 SG_ RdSpdCatType : 45|2@0+ (1,0) [0|3] ""  CGM_HS
 SG_ LnCat : 47|2@0+ (1,0) [0|3] ""  CGM_HS
 SG_ FncRdClass : 50|3@0+ (1,0) [0|7] ""  CGM_HS
 SG_ SprtLnRd : 43|1@0+ (1,0) [0|1] ""  CGM_HS
 SG_ CntrldAccRd : 39|1@0+ (1,0) [0|1] ""  CGM_HS
 SG_ BldUpArDet : 11|1@0+ (1,0) [0|1] ""  CGM_HS
 SG_ MpDataAvlbl : 3|1@0+ (1,0) [0|1] ""  CGM_HS
 SG_ SusCustStngReq : 42|3@0+ (1,0) [0|7] ""  CGM_HS,EBCM_OBD_HS,EBCM_HS
 SG_ StrCustStngReq : 38|3@0+ (1,0) [0|7] ""  CGM_HS,EBCM_OBD_HS,EBCM_HS
 SG_ RstrCustFctrDef : 35|1@0+ (1,0) [0|1] ""  CGM_HS,EBCM_OBD_HS,EBCM_HS
 SG_ DrvlnCustStngReq : 34|3@0+ (1,0) [0|7] ""  CGM_HS,EBCM_OBD_HS,EBCM_HS
 SG_ ChmMstrVDA : 22|1@0+ (1,0) [0|1] ""  CGM_HS
 SG_ IPCVDA : 21|1@0+ (1,0) [0|1] ""  CGM_HS,EBCM_OBD_HS,EBCM_HS
 SG_ HeadUpDispVDA : 20|1@0+ (1,0) [0|1] ""  CGM_HS
 SG_ HapticSeatVDA : 52|1@0+ (1,0) [0|1] ""  CGM_HS
 SG_ RRDoorAjarSwAct : 23|1@0+ (1,0) [0|1] ""  CGM_HS,ICCM_OBD_HS,ICCM_HS,EPB_HS
 SG_ PDAjrSwAtv : 10|1@0+ (1,0) [0|1] ""  CGM_HS,ICCM_OBD_HS,ICCM_HS,EPB_HS
 SG_ TrlrHWIntrfcVDA : 4|1@0+ (1,0) [0|1] ""  CGM_HS,EBCM_OBD_HS,EBCM_HS
 SG_ DrId : 15|3@0+ (1,0) [0|7] ""  CGM_HS,EBCM_OBD_HS,EBCM_HS
 SG_ EnrgMgtLdShdRq : 19|4@0+ (1,0) [0|15] ""  CGM_HS,ICCM_OBD_HS,ICCM_HS
 SG_ TreInfMonSysRstReq : 7|1@0+ (1,0) [0|1] ""  CGM_HS,EBCM_OBD_HS,EBCM_HS
 SG_ HUDActv : 6|1@0+ (1,0) [0|1] ""  CGM_HS
 SG_ RLDoorAjarSwAct : 8|1@0+ (1,0) [0|1] ""  CGM_HS,ICCM_OBD_HS,ICCM_HS,EPB_HS
 SG_ AutoMdSpdLmtCnfrmd : 57|1@0+ (1,0) [0|1] ""  CGM_HS,ECM_HS
 SG_ TCSysDisSwAtvARC : 61|2@0+ (1,0) [0|3] ""  CGM_HS,EBCM_OBD_HS,EBCM_HS,ECM_HS
 SG_ TCSysDisSwAtv_12A : 62|1@0+ (1,0) [0|1] ""  CGM_HS,ECM_HS
 SG_ DDAjrSwAtvM : 63|1@0+ (1,0) [0|1] ""  CGM_HS,EBCM_OBD_HS,EBCM_HS,ECM_HS
 SG_ DDAjrSwAtv : 9|1@0+ (1,0) [0|1] ""  CGM_HS,ICCM_OBD_HS,EBCM_OBD_HS,ICCM_HS,EPB_HS,EBCM_HS,ECM_HS
 SG_ DrSbltAtcV : 2|1@0+ (1,0) [0|1] ""  CGM_HS,EBCM_OBD_HS,EPB_HS,EBCM_HS,ECM_HS
 SG_ TrlrHtchSwAtv : 0|1@0+ (1,0) [0|1] ""  CGM_HS,EBCM_OBD_HS,EBCM_HS,ECM_HS
 SG_ BatVltV : 1|1@0+ (1,0) [0|1] ""  CGM_HS,ICCM_OBD_HS,ICCM_HS,BCP_HS,EPB_HS,TCM_HS,ECM_HS
 SG_ BatVlt : 31|8@0+ (0.1,3) [3|28.5] "volts"  CGM_HS,ICCM_OBD_HS,ICCM_HS,BCP_HS,EPB_HS,TCM_HS,ECM_HS
 SG_ DrSbltAtc : 12|1@0+ (1,0) [0|1] ""  CGM_HS,EBCM_OBD_HS,EPB_HS,EBCM_HS,ECM_HS

BO_ 485 PPEI_Steering_Wheel_Angle: 8 EBCM_HS
 SG_ StrAngSnsChksm : 50|11@0+ (1,0) [0|2047] ""  CGM_HS,EBCM_OBD_HS,HMIM_HS,EPS_HS,EPB_HS,EBCM_HS
 SG_ StrWhAngGrdV : 31|1@0+ (1,0) [0|1] ""  CGM_HS,ICCM_OBD_HS,EBCM_OBD_HS,ICCM_HS,HMIM_HS,EPS_HS,ONSTAR_HS,EPB_HS,TCCM_HS,EBCM_HS,ECM_HS
 SG_ StrWhlAngSenCalStat : 6|2@0+ (1,0) [0|3] ""  CGM_HS,ICCM_OBD_HS,EBCM_OBD_HS,ICCM_HS,HMIM_HS,EPS_HS,EPB_HS,TCCM_HS,EBCM_HS,BCM_HS,ECM_HS
 SG_ StrWhAngGrd : 27|12@0- (1,0) [-2048|2047] "deg/sec"  CGM_HS,ICCM_OBD_HS,EBCM_OBD_HS,ICCM_HS,HMIM_HS,EPS_HS,ONSTAR_HS,EPB_HS,TCCM_HS,EBCM_HS,ECM_HS
 SG_ StrWhAngV : 7|1@0+ (1,0) [0|1] ""  CGM_HS,ICCM_OBD_HS,EBCM_OBD_HS,ICCM_HS,HMIM_HS,EPS_HS,ONSTAR_HS,EPB_HS,TCCM_HS,EBCM_HS,BCM_HS,ECM_HS
 SG_ StrWhAng : 15|16@0- (0.0625,0) [-2048|2047.9375] "deg"  CGM_HS,ICCM_OBD_HS,EBCM_OBD_HS,ICCM_HS,HMIM_HS,EPS_HS,ONSTAR_HS,EPB_HS,TCCM_HS,EBCM_HS,BCM_HS,ECM_HS
 SG_ StrWhAngGrdMsk : 28|1@0+ (1,0) [0|1] ""  CGM_HS,EBCM_OBD_HS,HMIM_HS,EPS_HS,EPB_HS,EBCM_HS
 SG_ StrWhAngMsk : 2|1@0+ (1,0) [0|1] ""  CGM_HS,ICCM_OBD_HS,EBCM_OBD_HS,ICCM_HS,HMIM_HS,EPS_HS,EPB_HS,EBCM_HS
 SG_ StrWhlAngSenTyp : 4|2@0+ (1,0) [0|3] ""  CGM_HS,EBCM_OBD_HS,HMIM_HS,EPS_HS,EPB_HS,EBCM_HS
 SG_ StWhlAngAliveRollCnt : 30|2@0+ (1,0) [0|3] ""  CGM_HS,ICCM_OBD_HS,EBCM_OBD_HS,ICCM_HS,HMIM_HS,EPS_HS,EPB_HS,EBCM_HS

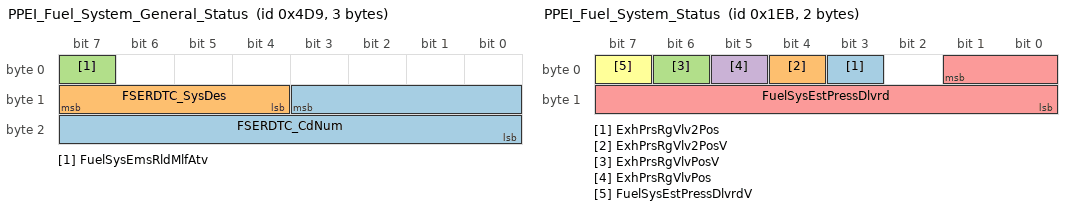
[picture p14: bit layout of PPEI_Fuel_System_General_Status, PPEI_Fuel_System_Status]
BO_ 1241 PPEI_Fuel_System_General_Status: 3 ICCM_HS
 SG_ FSERDTC_CdNum : 11|12@0+ (1,0) [0|4095] ""  ECM_HS
 SG_ FSERDTC_SysDes : 15|4@0+ (1,0) [0|15] ""  ECM_HS
 SG_ FuelSysEmsRldMlfAtv : 7|1@0+ (1,0) [0|1] ""  ECM_HS

BO_ 491 PPEI_Fuel_System_Status: 2 ICCM_HS
 SG_ ExhPrsRgVlv2Pos : 3|1@0+ (1,0) [0|1] ""  ECM_HS
 SG_ ExhPrsRgVlv2PosV : 4|1@0+ (1,0) [0|1] ""  ECM_HS
 SG_ ExhPrsRgVlvPosV : 6|1@0+ (1,0) [0|1] ""  ECM_HS
 SG_ ExhPrsRgVlvPos : 5|1@0+ (1,0) [0|1] ""  ECM_HS
 SG_ FuelSysEstPressDlvrd : 1|10@0+ (1,0) [0|1023] "kPa"  ECM_HS
 SG_ FuelSysEstPressDlvrdV : 7|1@0+ (1,0) [0|1] ""  ECM_HS

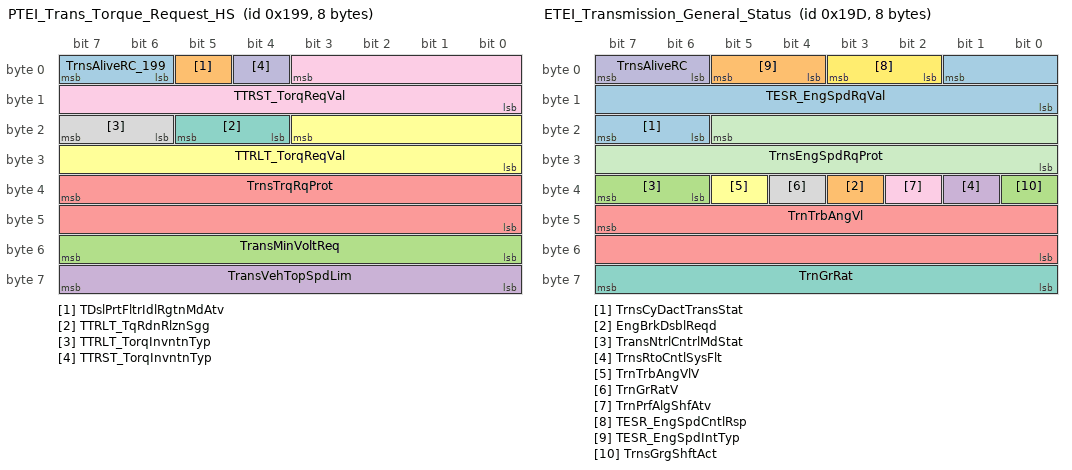
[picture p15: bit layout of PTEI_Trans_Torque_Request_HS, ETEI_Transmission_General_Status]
BO_ 409 PTEI_Trans_Torque_Request_HS: 8 TCM_HS
 SG_ TrnsAliveRC_199 : 7|2@0+ (1,0) [0|3] ""  ECM_HS
 SG_ TDslPrtFltrIdlRgtnMdAtv : 5|1@0+ (1,0) [0|1] ""  ECM_HS
 SG_ TransMinVoltReq : 55|8@0+ (0.07843,0) [0|19.99965] "volts"  ECM_HS
 SG_ TransVehTopSpdLim : 63|8@0+ (2,0) [0|510] "km / h"  ECM_HS
 SG_ TrnsTrqRqProt : 39|16@0+ (1,0) [0|65535] ""  ECM_HS
 SG_ TTRLT_TorqReqVal : 19|12@0+ (0.5,-848) [-848|1199.5] "Nm"  ECM_HS
 SG_ TTRLT_TqRdnRlznSgg : 21|2@0+ (1,0) [0|3] ""  ECM_HS
 SG_ TTRLT_TorqInvntnTyp : 23|2@0+ (1,0) [0|3] ""  ECM_HS
 SG_ TTRST_TorqReqVal : 3|12@0+ (0.5,-848) [-848|1199.5] "Nm"  ECM_HS
 SG_ TTRST_TorqInvntnTyp : 4|1@0+ (1,0) [0|1] ""  ECM_HS

BO_ 413 ETEI_Transmission_General_Status: 8 TCM_HS
 SG_ TrnsCyDactTransStat : 23|2@0+ (1,0) [0|3] ""  CGM_HS,ECM_HS
 SG_ EngBrkDsblReqd : 35|1@0+ (1,0) [0|1] ""  CGM_HS,ECM_HS
 SG_ TransNtrlCntrlMdStat : 39|2@0+ (1,0) [0|3] ""  CGM_HS,EBCM_OBD_HS,BCM_HS,EBCM_HS,ECM_HS
 SG_ TrnsRtoCntlSysFlt : 33|1@0+ (1,0) [0|1] ""  CGM_HS,ECM_HS
 SG_ TrnTrbAngVl : 47|16@0+ (0.25,0) [0|16383.75] "rpm"  CGM_HS,BCP_HS,ECM_HS
 SG_ TrnTrbAngVlV : 37|1@0+ (1,0) [0|1] ""  CGM_HS,BCP_HS,ECM_HS
 SG_ TrnGrRat : 63|8@0+ (0.03125,0) [0|7.96875] ""  CGM_HS,BCP_HS,ECM_HS
 SG_ TrnGrRatV : 36|1@0+ (1,0) [0|1] ""  CGM_HS,BCP_HS,ECM_HS
 SG_ TrnPrfAlgShfAtv : 34|1@0+ (1,0) [0|1] ""  CGM_HS,ECM_HS
 SG_ TrnsAliveRC : 7|2@0+ (1,0) [0|3] ""  CGM_HS,ECM_HS
 SG_ TrnsEngSpdRqProt : 21|14@0+ (1,0) [0|16383] ""  CGM_HS,ECM_HS
 SG_ TESR_EngSpdCntlRsp : 3|2@0+ (1,0) [0|3] ""  CGM_HS,ECM_HS
 SG_ TESR_EngSpdRqVal : 1|10@0+ (8,0) [0|8184] "rpm"  CGM_HS,ECM_HS
 SG_ TESR_EngSpdIntTyp : 5|2@0+ (1,0) [0|3] ""  CGM_HS,ECM_HS
 SG_ TrnsGrgShftAct : 32|1@0+ (1,0) [0|1] ""  CGM_HS,ECM_HS

BO_ 257 USDT_Req_to_All_HS_ECUs: 8 TestTool_HS
 SG_ DgnInf : 7|64@0+ (1,0) [0|1.84467440737096E+019] ""  CGM_HS,ICCM_OBD_HS,SAS_HS,ACCM_HS,ICCM_HS,HMIM_HS,EPS_HS,BCP_HS,EBCM_OBD_HS,ONSTAR_HS,EPB_HS,TCCM_HS,BCM_HS,TCM_HS,EBCM_HS,ECM_HS

BO_ 2015 USDT_OBD_Functional_Request: 8 TestTool_HS
 SG_ DgnInf : 7|64@0+ (1,0) [0|1.84467440737096E+019] ""  ICCM_OBD_HS,ICCM_HS,BCP_HS,EBCM_OBD_HS,TCM_HS,ECM_HS

BO_ 2016 USDT_Req_to_ECM_HS: 8 TestTool_HS
 SG_ DgnInf : 7|64@0+ (1,0) [0|1.84467440737096E+019] ""  ECM_HS

BO_TX_BU_ 1273 : EBCM_OBD_HS,EBCM_HS;
BO_TX_BU_ 753 : EBCM_OBD_HS,EBCM_HS;
BO_TX_BU_ 1243 : ICCM_OBD_HS,ICCM_HS;
BO_TX_BU_ 508 : EBCM_OBD_HS,EBCM_HS;
BO_TX_BU_ 209 : EBCM_OBD_HS,EBCM_HS;
BO_TX_BU_ 454 : EBCM_OBD_HS,EBCM_HS;
BO_TX_BU_ 456 : EBCM_OBD_HS,EBCM_HS;
BO_TX_BU_ 1005 : CGM_HS,ONSTAR_HS;
BO_TX_BU_ 485 : SAS_HS,EBCM_OBD_HS,EPS_HS,EBCM_HS;
BO_TX_BU_ 1241 : ICCM_OBD_HS,ICCM_HS;
BO_TX_BU_ 491 : ICCM_OBD_HS,ICCM_HS;
BO_TX_BU_ 257 : CGM_HS,ONSTAR_HS,TestTool_HS;
BO_TX_BU_ 2015 : CGM_HS,ONSTAR_HS,TestTool_HS;
BO_TX_BU_ 2016 : CGM_HS,ONSTAR_HS,TestTool_HS;
CM_ SG_ 1919 DTCI_DTCFaultType_77F "Based on Powertrain definition.  Not expected to be supported by all devices.";
CM_ SG_ 1919 DTCI_DTCFailType_77F "Assigned per GMW3110, Appendix E";
CM_ SG_ 1919 DTCI_DTCSource_77F "This shall be equal to the Diagnostic Address of the transmittting device.";
CM_ SG_ 1239 BatSOH "State of Health = the aging state of the Battery";
CM_ SG_ 390 HybDFCOReq "DFCO = Deceleration Fuel Cut Off";
CM_ BO_ 719 "Application Is Tx ing this frame at the rate of 40 ms";
CM_ BO_ 717 "Note that the ACC algorithm will transmit this message at a 50 ms periodic rate and the ECU033 algorithm will transmit this message at a 40 ms periodic rate";
CM_ SG_ 1005 EnhSvVehTopSpdLimP "4 ASCII characters";
CM_ BO_ 715 "Note that the ACC algorithm will transmit this message at a 50 ms periodic rate and the ECU033 algorithm will transmit this message at a 40 ms periodic rate";
CM_ SG_ 320 MainLghtSw "Operator selection for the main lighting switch";
CM_ SG_ 320 AutLghtCtrl "This signal represents if Automatic Lights Control feature is active/inactive";
CM_ SG_ 499 PFTrnsTUDSecSwSt "Added 2006 Nov 10 according to CR1112";
CM_ BO_ 880 "Note that the ACC and EBCM algorithm will transmit this message at a 50 ms periodic rate and the ECU033 algorithm will transmit this message at a 40 ms periodic rate";
CM_ SG_ 880 ACCHdwyStg "Headway is the  time which results from dividing the following distance (or gap) between vehicles by the vehicle speed.  This setting allows the driver to choose a Headway Setting without actually knowing the value of this time.";
CM_ SG_ 298 DrId "Driver 8 changed to Unknown on 3/30/99";
CM_ BO_ 485 "6443-Power Steering Indication On in this frame not used by GlobalA /JD";
CM_ BO_ 491 "Changed for PPEI 3.6 - Should be gated from FSCM
";
BA_DEF_ SG_  "VNSigSLHSSharedDiagnostic" ENUM  "No","Yes";
BA_DEF_ SG_  "VNSigSLHS_VNReq" ENUM  "No","Yes";
BA_DEF_ SG_  "GenSigSendOnInit" ENUM  "Not Initialized","Application","Handler";
BA_DEF_ SG_  "GenSigSendType" ENUM  "not used","not used","not used","not used","not used","not used","not used","NoSigSendType","not used","not used","OnAnyChange","OnChangeIfActive","OnDelta";
BA_DEF_ SG_  "GenSigDeltaValue" INT 0 0;
BA_DEF_ SG_  "VNSigAllNodes" ENUM  "No","Yes";
BA_DEF_ SG_  "SignalType" STRING ;
BA_DEF_ SG_  "PacketOrder" INT 0 65535;
BA_DEF_ SG_  "SignalLongName" STRING ;
BA_DEF_ SG_  "GenSigStartValue" INT 0 65535;
BA_DEF_ SG_  "TxSignalSendOnInit" ENUM  "Not Initialized","Application","Handler";
BA_DEF_ BO_  "GenMsgILSupport" ENUM  "No","Yes";
BA_DEF_ BO_  "AppGenMsgCycleTime" INT 0 0;
BA_DEF_ BO_  "TpApplType" STRING ;
BA_DEF_ BO_  "Prio" INT 0 7;
BA_DEF_ BO_  "MessageSubnet" ENUM  "LS","MS","HS","CE","PE","HV","FO","S1","HE","LE","HE2","vector_leerstring";
BA_DEF_ BO_  "DiagState" ENUM  "No","Yes";
BA_DEF_ BO_  "GenMsgIlSupport" ENUM  "No","Yes";
BA_DEF_ BO_  "GenMsgStartDelayTime" INT 0 100000;
BA_DEF_ BO_  "GenMsgDelayTime" INT 0 100000;
BA_DEF_ BO_  "GenMsgCycleTime" INT 0 100000;
BA_DEF_ BO_  "GenMsgSendType" ENUM  "cyclicX","spontanX","cyclicIfActiveX","spontanWithDelay","cyclicAndSpontanX","cyclicAndSpontanWithDelay","spontanWithRepitition","cyclicIfActiveAndSpontanWD";
BA_DEF_ BO_  "DiagResponse" ENUM  "No","Yes";
BA_DEF_ BO_  "DiagRequest" ENUM  "No","Yes";
BA_DEF_ BO_  "NmMessage" ENUM  "No","Yes";
BA_DEF_REL_ BU_SG_REL_  "GenSigSuprvResp" ENUM  "None","Notify App","Substitute Default";
BA_DEF_REL_ BU_SG_REL_  "GenSigSuprvRespSubValue" INT 0 65535;
BA_DEF_REL_ BU_SG_REL_  "GenSigRxStartValue" STRING ;
BA_DEF_REL_ BU_SG_REL_  "GenSigVDAFailResp" ENUM  "No","Yes";
BA_DEF_REL_ BU_SG_REL_  "GenSigVDAFailComment" STRING ;
BA_DEF_REL_ BU_SG_REL_  "GenSigVBitRespComment" STRING ;
BA_DEF_REL_ BU_SG_REL_  "GenSigVBitResp" ENUM  "No","Yes";
BA_DEF_REL_ BU_SG_REL_  "GenSigSuprvRespComment" STRING ;
BA_DEF_REL_ BU_SG_REL_  "GenSigTimeoutMsg" HEX 0 268435455;
BA_DEF_REL_ BU_SG_REL_  "GenSigTimeoutTime" INT 0 5000;
BA_DEF_DEF_  "VNSigSLHSSharedDiagnostic" "No";
BA_DEF_DEF_  "VNSigSLHS_VNReq" "No";
BA_DEF_DEF_  "GenSigSendOnInit" "Not Initialized";
BA_DEF_DEF_  "GenSigSendType" "NoSigSendType";
BA_DEF_DEF_  "GenSigDeltaValue" 0;
BA_DEF_DEF_  "VNSigAllNodes" "No";
BA_DEF_DEF_  "SignalType" "";
BA_DEF_DEF_  "PacketOrder" 0;
BA_DEF_DEF_  "SignalLongName" "";
BA_DEF_DEF_  "GenSigStartValue" 0;
BA_DEF_DEF_  "TxSignalSendOnInit" "Not Initialized";
BA_DEF_DEF_  "GenMsgILSupport" "Yes";
BA_DEF_DEF_  "AppGenMsgCycleTime" 0;
BA_DEF_DEF_  "TpApplType" "";
BA_DEF_DEF_  "Prio" 0;
BA_DEF_DEF_  "MessageSubnet" "LS";
BA_DEF_DEF_  "DiagState" "No";
BA_DEF_DEF_  "GenMsgIlSupport" "Yes";
BA_DEF_DEF_  "GenMsgStartDelayTime" 0;
BA_DEF_DEF_  "GenMsgDelayTime" 0;
BA_DEF_DEF_  "GenMsgCycleTime" 0;
BA_DEF_DEF_  "GenMsgSendType" "spontanX";
BA_DEF_DEF_  "DiagResponse" "No";
BA_DEF_DEF_  "DiagRequest" "No";
BA_DEF_DEF_  "NmMessage" "No";
BA_DEF_DEF_REL_ "GenSigSuprvResp" "None";
BA_DEF_DEF_REL_ "GenSigSuprvRespSubValue" 0;
BA_DEF_DEF_REL_ "GenSigRxStartValue" "";
BA_DEF_DEF_REL_ "GenSigVDAFailResp" "No";
BA_DEF_DEF_REL_ "GenSigVDAFailComment" "";
BA_DEF_DEF_REL_ "GenSigVBitRespComment" "";
BA_DEF_DEF_REL_ "GenSigVBitResp" "No";
BA_DEF_DEF_REL_ "GenSigSuprvRespComment" "";
BA_DEF_DEF_REL_ "GenSigTimeoutMsg" 0;
BA_DEF_DEF_REL_ "GenSigTimeoutTime" 0;
BA_ "GenMsgSendType" BO_ 424 0;
BA_ "GenMsgCycleTime" BO_ 424 25;
BA_ "MessageSubnet" BO_ 424 2;
BA_ "GenMsgSendType" BO_ 423 0;
BA_ "GenMsgCycleTime" BO_ 423 25;
BA_ "MessageSubnet" BO_ 423 2;
BA_ "GenMsgSendType" BO_ 901 0;
BA_ "GenMsgCycleTime" BO_ 901 100;
BA_ "MessageSubnet" BO_ 901 2;
BA_ "GenMsgSendType" BO_ 1919 0;
BA_ "GenMsgCycleTime" BO_ 1919 1000;
BA_ "MessageSubnet" BO_ 1919 2;
BA_ "Prio" BO_ 1919 6;
BA_ "DiagResponse" BO_ 2026 1;
BA_ "MessageSubnet" BO_ 2026 2;
BA_ "MessageSubnet" BO_ 1514 2;
BA_ "TpApplType" BO_ 1514 "DiagUUDTResponse";
BA_ "GenMsgILSupport" BO_ 1514 0;
BA_ "GenMsgSendType" BO_ 1273 0;
BA_ "GenMsgCycleTime" BO_ 1273 500;
BA_ "MessageSubnet" BO_ 1273 2;
BA_ "GenMsgSendType" BO_ 753 0;
BA_ "GenMsgCycleTime" BO_ 753 100;
BA_ "MessageSubnet" BO_ 753 2;
BA_ "GenMsgSendType" BO_ 407 0;
BA_ "GenMsgCycleTime" BO_ 407 25;
BA_ "MessageSubnet" BO_ 407 2;
BA_ "GenMsgSendType" BO_ 189 0;
BA_ "GenMsgCycleTime" BO_ 189 25;
BA_ "MessageSubnet" BO_ 189 2;
BA_ "GenMsgSendType" BO_ 1221 0;
BA_ "GenMsgCycleTime" BO_ 1221 500;
BA_ "GenMsgStartDelayTime" BO_ 1221 10;
BA_ "MessageSubnet" BO_ 1221 2;
BA_ "GenMsgSendType" BO_ 1243 0;
BA_ "GenMsgCycleTime" BO_ 1243 500;
BA_ "MessageSubnet" BO_ 1243 2;
BA_ "GenMsgSendType" BO_ 1239 0;
BA_ "GenMsgCycleTime" BO_ 1239 500;
BA_ "GenMsgStartDelayTime" BO_ 1239 20;
BA_ "MessageSubnet" BO_ 1239 2;
BA_ "GenMsgSendType" BO_ 508 0;
BA_ "GenMsgCycleTime" BO_ 508 50;
BA_ "MessageSubnet" BO_ 508 2;
BA_ "GenMsgSendType" BO_ 422 0;
BA_ "GenMsgCycleTime" BO_ 422 25;
BA_ "MessageSubnet" BO_ 422 2;
BA_ "GenMsgSendType" BO_ 971 0;
BA_ "GenMsgCycleTime" BO_ 971 100;
BA_ "GenMsgStartDelayTime" BO_ 971 90;
BA_ "MessageSubnet" BO_ 971 2;
BA_ "GenMsgSendType" BO_ 209 0;
BA_ "GenMsgCycleTime" BO_ 209 10;
BA_ "MessageSubnet" BO_ 209 2;
BA_ "GenMsgSendType" BO_ 454 0;
BA_ "GenMsgCycleTime" BO_ 454 25;
BA_ "MessageSubnet" BO_ 454 2;
BA_ "GenMsgSendType" BO_ 1189 0;
BA_ "GenMsgCycleTime" BO_ 1189 500;
BA_ "MessageSubnet" BO_ 1189 2;
BA_ "GenMsgSendType" BO_ 421 0;
BA_ "GenMsgCycleTime" BO_ 421 25;
BA_ "MessageSubnet" BO_ 421 2;
BA_ "GenMsgSendType" BO_ 456 0;
BA_ "GenMsgCycleTime" BO_ 456 10;
BA_ "MessageSubnet" BO_ 456 2;
BA_ "GenMsgSendType" BO_ 393 0;
BA_ "GenMsgCycleTime" BO_ 393 25;
BA_ "MessageSubnet" BO_ 393 2;
BA_ "GenMsgSendType" BO_ 199 0;
BA_ "GenMsgCycleTime" BO_ 199 12;
BA_ "MessageSubnet" BO_ 199 2;
BA_ "GenMsgSendType" BO_ 390 0;
BA_ "GenMsgCycleTime" BO_ 390 12;
BA_ "MessageSubnet" BO_ 390 2;
BA_ "GenMsgSendType" BO_ 460 0;
BA_ "GenMsgCycleTime" BO_ 460 20;
BA_ "MessageSubnet" BO_ 460 2;
BA_ "MessageSubnet" BO_ 719 2;
BA_ "AppGenMsgCycleTime" BO_ 719 40;
BA_ "MessageSubnet" BO_ 717 2;
BA_ "AppGenMsgCycleTime" BO_ 717 40;
BA_ "GenMsgSendType" BO_ 1105 0;
BA_ "GenMsgCycleTime" BO_ 1105 100;
BA_ "GenMsgStartDelayTime" BO_ 1105 10;
BA_ "MessageSubnet" BO_ 1105 2;
BA_ "GenMsgSendType" BO_ 1005 0;
BA_ "GenMsgCycleTime" BO_ 1005 250;
BA_ "MessageSubnet" BO_ 1005 2;
BA_ "GenMsgSendType" BO_ 688 0;
BA_ "GenMsgCycleTime" BO_ 688 20;
BA_ "MessageSubnet" BO_ 688 2;
BA_ "GenMsgSendType" BO_ 431 0;
BA_ "GenMsgCycleTime" BO_ 431 25;
BA_ "MessageSubnet" BO_ 431 2;
BA_ "MessageSubnet" BO_ 715 2;
BA_ "AppGenMsgCycleTime" BO_ 715 40;
BA_ "GenMsgSendType" BO_ 320 0;
BA_ "GenMsgCycleTime" BO_ 320 1000;
BA_ "GenMsgDelayTime" BO_ 320 10;
BA_ "GenMsgStartDelayTime" BO_ 320 30;
BA_ "MessageSubnet" BO_ 320 2;
BA_ "GenMsgSendType" BO_ 499 0;
BA_ "GenMsgCycleTime" BO_ 499 30;
BA_ "GenMsgStartDelayTime" BO_ 499 20;
BA_ "MessageSubnet" BO_ 499 2;
BA_ "MessageSubnet" BO_ 880 2;
BA_ "AppGenMsgCycleTime" BO_ 880 40;
BA_ "GenMsgSendType" BO_ 298 0;
BA_ "GenMsgCycleTime" BO_ 298 100;
BA_ "GenMsgStartDelayTime" BO_ 298 40;
BA_ "MessageSubnet" BO_ 298 2;
BA_ "GenMsgSendType" BO_ 485 0;
BA_ "GenMsgCycleTime" BO_ 485 10;
BA_ "MessageSubnet" BO_ 485 2;
BA_ "GenMsgSendType" BO_ 1241 0;
BA_ "GenMsgCycleTime" BO_ 1241 500;
BA_ "MessageSubnet" BO_ 1241 2;
BA_ "GenMsgSendType" BO_ 491 0;
BA_ "GenMsgCycleTime" BO_ 491 12;
BA_ "MessageSubnet" BO_ 491 2;
BA_ "GenMsgSendType" BO_ 409 0;
BA_ "GenMsgCycleTime" BO_ 409 25;
BA_ "MessageSubnet" BO_ 409 2;
BA_ "GenMsgSendType" BO_ 413 0;
BA_ "GenMsgCycleTime" BO_ 413 25;
BA_ "MessageSubnet" BO_ 413 2;
BA_ "DiagState" BO_ 257 1;
BA_ "MessageSubnet" BO_ 257 2;
BA_ "GenMsgILSupport" BO_ 257 0;
BA_ "MessageSubnet" BO_ 2015 2;
BA_ "GenMsgILSupport" BO_ 2015 0;
BA_ "DiagRequest" BO_ 2016 1;
BA_ "MessageSubnet" BO_ 2016 2;
BA_ "SignalLongName" SG_ 424 TransClch3FlTm "Transmission Clutch 3 Fill Time";
BA_ "SignalType" SG_ 424 TransClch3FlTm "UNM";
BA_ "VNSigAllNodes" SG_ 424 TransClch3FlTm 1;
BA_ "SignalLongName" SG_ 424 TransClch3EstTorq "Transmission Clutch 3 Estimated Torque";
BA_ "SignalType" SG_ 424 TransClch3EstTorq "UNM";
BA_ "VNSigAllNodes" SG_ 424 TransClch3EstTorq 1;
BA_ "SignalLongName" SG_ 424 TransClch3MaxEnrgy "Transmission Clutch 3 Maximum Energy";
BA_ "SignalType" SG_ 424 TransClch3MaxEnrgy "UNM";
BA_ "VNSigAllNodes" SG_ 424 TransClch3MaxEnrgy 1;
BA_ "SignalLongName" SG_ 424 TransClch3FlAch "Transmission Clutch 3 Fill Achieved";
BA_ "SignalType" SG_ 424 TransClch3FlAch "BLN";
BA_ "VNSigAllNodes" SG_ 424 TransClch3FlAch 1;
BA_ "SignalLongName" SG_ 424 TransClch2FlTm "Transmission Clutch 2 Fill Time";
BA_ "SignalType" SG_ 424 TransClch2FlTm "UNM";
BA_ "VNSigAllNodes" SG_ 424 TransClch2FlTm 1;
BA_ "SignalLongName" SG_ 424 TransClch2EstTorq "Transmission Clutch 2 Estimated Torque";
BA_ "SignalType" SG_ 424 TransClch2EstTorq "UNM";
BA_ "VNSigAllNodes" SG_ 424 TransClch2EstTorq 1;
BA_ "SignalLongName" SG_ 424 TransClch2MaxEnrgy "Transmission Clutch 2 Maximum Energy";
BA_ "SignalType" SG_ 424 TransClch2MaxEnrgy "UNM";
BA_ "VNSigAllNodes" SG_ 424 TransClch2MaxEnrgy 1;
BA_ "SignalLongName" SG_ 424 TransClch2FlAch "Transmission Clutch 2 Fill Achieved";
BA_ "SignalType" SG_ 424 TransClch2FlAch "BLN";
BA_ "VNSigAllNodes" SG_ 424 TransClch2FlAch 1;
BA_ "SignalLongName" SG_ 423 TrnsPTSysShtdwnRq "Transmission Powertrain System Shutdown Requested";
BA_ "SignalType" SG_ 423 TrnsPTSysShtdwnRq "BLN";
BA_ "VNSigAllNodes" SG_ 423 TrnsPTSysShtdwnRq 1;
BA_ "SignalLongName" SG_ 423 TransClch1FlTm "Transmission Clutch 1 Fill Time";
BA_ "SignalType" SG_ 423 TransClch1FlTm "UNM";
BA_ "VNSigAllNodes" SG_ 423 TransClch1FlTm 1;
BA_ "SignalLongName" SG_ 423 TransClch1EstTorq "Transmission Clutch 1 Estimated Torque";
BA_ "SignalType" SG_ 423 TransClch1EstTorq "UNM";
BA_ "VNSigAllNodes" SG_ 423 TransClch1EstTorq 1;
BA_ "SignalLongName" SG_ 423 TransClch1MaxEnrgy "Transmission Clutch 1 Maximum Energy";
BA_ "SignalType" SG_ 423 TransClch1MaxEnrgy "UNM";
BA_ "VNSigAllNodes" SG_ 423 TransClch1MaxEnrgy 1;
BA_ "SignalLongName" SG_ 423 TransClch1FlAch "Transmission Clutch 1 Fill Achieved";
BA_ "SignalType" SG_ 423 TransClch1FlAch "BLN";
BA_ "VNSigAllNodes" SG_ 423 TransClch1FlAch 1;
BA_ "SignalLongName" SG_ 423 TransHydrlcDfltgAct "Transmission Hydraulic Defaulting Active";
BA_ "SignalType" SG_ 423 TransHydrlcDfltgAct "BLN";
BA_ "VNSigAllNodes" SG_ 423 TransHydrlcDfltgAct 1;
BA_ "SignalLongName" SG_ 423 TCFS_Cltch5FltStat "Transmission Clutch Fault Status : Clutch 5 Fault Status";
BA_ "PacketOrder" SG_ 423 TCFS_Cltch5FltStat 5;
BA_ "SignalType" SG_ 423 TCFS_Cltch5FltStat "ENM";
BA_ "VNSigAllNodes" SG_ 423 TCFS_Cltch5FltStat 1;
BA_ "SignalLongName" SG_ 423 TCFS_Cltch4FltStat "Transmission Clutch Fault Status : Clutch 4 Fault Status";
BA_ "PacketOrder" SG_ 423 TCFS_Cltch4FltStat 4;
BA_ "SignalType" SG_ 423 TCFS_Cltch4FltStat "ENM";
BA_ "VNSigAllNodes" SG_ 423 TCFS_Cltch4FltStat 1;
BA_ "SignalLongName" SG_ 423 TCFS_Cltch3FltStat "Transmission Clutch Fault Status : Clutch 3 Fault Status";
BA_ "PacketOrder" SG_ 423 TCFS_Cltch3FltStat 3;
BA_ "SignalType" SG_ 423 TCFS_Cltch3FltStat "ENM";
BA_ "VNSigAllNodes" SG_ 423 TCFS_Cltch3FltStat 1;
BA_ "SignalLongName" SG_ 423 TCFS_Cltch2FltStat "Transmission Clutch Fault Status : Clutch 2 Fault Status";
BA_ "PacketOrder" SG_ 423 TCFS_Cltch2FltStat 2;
BA_ "SignalType" SG_ 423 TCFS_Cltch2FltStat "ENM";
BA_ "VNSigAllNodes" SG_ 423 TCFS_Cltch2FltStat 1;
BA_ "SignalLongName" SG_ 423 TCFS_Cltch1FltStat "Transmission Clutch Fault Status : Clutch 1 Fault Status";
BA_ "PacketOrder" SG_ 423 TCFS_Cltch1FltStat 1;
BA_ "SignalType" SG_ 423 TCFS_Cltch1FltStat "ENM";
BA_ "VNSigAllNodes" SG_ 423 TCFS_Cltch1FltStat 1;
BA_ "SignalLongName" SG_ 423 TCAS_Cltch5AvlbltyStat "Transmission Clutch Availability Status : Clutch 5 Availability Status";
BA_ "PacketOrder" SG_ 423 TCAS_Cltch5AvlbltyStat 5;
BA_ "SignalType" SG_ 423 TCAS_Cltch5AvlbltyStat "ENM";
BA_ "VNSigAllNodes" SG_ 423 TCAS_Cltch5AvlbltyStat 1;
BA_ "SignalLongName" SG_ 423 TCAS_Cltch4AvlbltyStat "Transmission Clutch Availability Status : Clutch 4 Availability Status";
BA_ "PacketOrder" SG_ 423 TCAS_Cltch4AvlbltyStat 4;
BA_ "SignalType" SG_ 423 TCAS_Cltch4AvlbltyStat "ENM";
BA_ "VNSigAllNodes" SG_ 423 TCAS_Cltch4AvlbltyStat 1;
BA_ "SignalLongName" SG_ 423 TCAS_Cltch3AvlbltyStat "Transmission Clutch Availability Status : Clutch 3 Availability Status";
BA_ "PacketOrder" SG_ 423 TCAS_Cltch3AvlbltyStat 3;
BA_ "SignalType" SG_ 423 TCAS_Cltch3AvlbltyStat "ENM";
BA_ "VNSigAllNodes" SG_ 423 TCAS_Cltch3AvlbltyStat 1;
BA_ "SignalLongName" SG_ 423 TCAS_Cltch2AvlbltyStat "Transmission Clutch Availability Status : Clutch 2 Availability Status";
BA_ "PacketOrder" SG_ 423 TCAS_Cltch2AvlbltyStat 2;
BA_ "SignalType" SG_ 423 TCAS_Cltch2AvlbltyStat "ENM";
BA_ "VNSigAllNodes" SG_ 423 TCAS_Cltch2AvlbltyStat 1;
BA_ "SignalLongName" SG_ 423 TCAS_Cltch1AvlbltyStat "Transmission Clutch Availability Status : Clutch 1 Availability Status";
BA_ "PacketOrder" SG_ 423 TCAS_Cltch1AvlbltyStat 1;
BA_ "SignalType" SG_ 423 TCAS_Cltch1AvlbltyStat "ENM";
BA_ "VNSigAllNodes" SG_ 423 TCAS_Cltch1AvlbltyStat 1;
BA_ "SignalLongName" SG_ 901 TrnsMtrBCoolFlwEst "Transmission Motor B Cooling Flow Estimated";
BA_ "SignalType" SG_ 901 TrnsMtrBCoolFlwEst "UNM";
BA_ "VNSigAllNodes" SG_ 901 TrnsMtrBCoolFlwEst 1;
BA_ "SignalLongName" SG_ 901 TrnsMtrACoolFlwEst "Transmission Motor A Cooling Flow Estimated";
BA_ "SignalType" SG_ 901 TrnsMtrACoolFlwEst "UNM";
BA_ "VNSigAllNodes" SG_ 901 TrnsMtrACoolFlwEst 1;
BA_ "SignalLongName" SG_ 901 TrnsLubeFlwEst "Transmission Lube Flow Estimated";
BA_ "SignalType" SG_ 901 TrnsLubeFlwEst "UNM";
BA_ "VNSigAllNodes" SG_ 901 TrnsLubeFlwEst 1;
BA_ "SignalLongName" SG_ 1919 DTCI_DTCFaultType_77F "Diagnostic Trouble Code Information Extended 77F : Diagnostic Trouble Code Fault Type";
BA_ "PacketOrder" SG_ 1919 DTCI_DTCFaultType_77F 20;
BA_ "SignalType" SG_ 1919 DTCI_DTCFaultType_77F "ENM";
BA_ "VNSigAllNodes" SG_ 1919 DTCI_DTCFaultType_77F 1;
BA_ "SignalLongName" SG_ 1919 DTCI_CodeSupported_77F "Diagnostic Trouble Code Information Extended 77F : Code Supported";
BA_ "PacketOrder" SG_ 1919 DTCI_CodeSupported_77F 19;
BA_ "SignalType" SG_ 1919 DTCI_CodeSupported_77F "BLN";
BA_ "VNSigAllNodes" SG_ 1919 DTCI_CodeSupported_77F 1;
BA_ "SignalLongName" SG_ 1919 DTCI_CurrentStatus_77F "Diagnostic Trouble Code Information Extended 77F : Current Status";
BA_ "PacketOrder" SG_ 1919 DTCI_CurrentStatus_77F 18;
BA_ "SignalType" SG_ 1919 DTCI_CurrentStatus_77F "BLN";
BA_ "VNSigAllNodes" SG_ 1919 DTCI_CurrentStatus_77F 1;
BA_ "SignalLongName" SG_ 1919 DTCI_TstNPsdCdClrdSt_77F "Diagnostic Trouble Code Information Extended 77F : Test Not Passed Since Code Cleared Status";
BA_ "PacketOrder" SG_ 1919 DTCI_TstNPsdCdClrdSt_77F 17;
BA_ "SignalType" SG_ 1919 DTCI_TstNPsdCdClrdSt_77F "BLN";
BA_ "VNSigAllNodes" SG_ 1919 DTCI_TstNPsdCdClrdSt_77F 1;
BA_ "SignalLongName" SG_ 1919 DTCI_TstFldCdClrdStat_77F "Diagnostic Trouble Code Information Extended 77F : Test Failed Since Code Cleared Status";
BA_ "PacketOrder" SG_ 1919 DTCI_TstFldCdClrdStat_77F 16;
BA_ "SignalType" SG_ 1919 DTCI_TstFldCdClrdStat_77F "BLN";
BA_ "VNSigAllNodes" SG_ 1919 DTCI_TstFldCdClrdStat_77F 1;
BA_ "SignalLongName" SG_ 1919 DTCI_HistStat_77F "Diagnostic Trouble Code Information Extended 77F : History Status";
BA_ "PacketOrder" SG_ 1919 DTCI_HistStat_77F 15;
BA_ "SignalType" SG_ 1919 DTCI_HistStat_77F "BLN";
BA_ "VNSigAllNodes" SG_ 1919 DTCI_HistStat_77F 1;
BA_ "SignalLongName" SG_ 1919 DTCI_TstNPsdPwrUpSt_77F "Diagnostic Trouble Code Information Extended 77F : Test Not Passed Since Power Up Status";
BA_ "PacketOrder" SG_ 1919 DTCI_TstNPsdPwrUpSt_77F 14;
BA_ "SignalType" SG_ 1919 DTCI_TstNPsdPwrUpSt_77F "BLN";
BA_ "VNSigAllNodes" SG_ 1919 DTCI_TstNPsdPwrUpSt_77F 1;
BA_ "SignalLongName" SG_ 1919 DTCI_TstFldPwrUpSt_77F "Diagnostic Trouble Code Information Extended 77F : Test Failed Since Power Up Status";
BA_ "PacketOrder" SG_ 1919 DTCI_TstFldPwrUpSt_77F 13;
BA_ "SignalType" SG_ 1919 DTCI_TstFldPwrUpSt_77F "BLN";
BA_ "VNSigAllNodes" SG_ 1919 DTCI_TstFldPwrUpSt_77F 1;
BA_ "SignalLongName" SG_ 1919 DTCI_WrnIndRqdSt_77F "Diagnostic Trouble Code Information Extended 77F : Warning Indicator Requested Status";
BA_ "PacketOrder" SG_ 1919 DTCI_WrnIndRqdSt_77F 12;
BA_ "SignalType" SG_ 1919 DTCI_WrnIndRqdSt_77F "BLN";
BA_ "VNSigAllNodes" SG_ 1919 DTCI_WrnIndRqdSt_77F 1;
BA_ "SignalLongName" SG_ 1919 DTCI_DTCFailType_77F "Diagnostic Trouble Code Information Extended 77F : Diagnostic Trouble Code Failure Type";
BA_ "PacketOrder" SG_ 1919 DTCI_DTCFailType_77F 11;
BA_ "SignalType" SG_ 1919 DTCI_DTCFailType_77F "UNM";
BA_ "VNSigAllNodes" SG_ 1919 DTCI_DTCFailType_77F 1;
BA_ "SignalLongName" SG_ 1919 DTCI_DTCNumber_77F "Diagnostic Trouble Code Information Extended 77F : Diagnostic Trouble Code Number";
BA_ "PacketOrder" SG_ 1919 DTCI_DTCNumber_77F 10;
BA_ "SignalType" SG_ 1919 DTCI_DTCNumber_77F "UNM";
BA_ "VNSigAllNodes" SG_ 1919 DTCI_DTCNumber_77F 1;
BA_ "SignalLongName" SG_ 1919 DTCI_DTCSource_77F "Diagnostic Trouble Code Information Extended 77F : Diagnostic Trouble Code Source";
BA_ "PacketOrder" SG_ 1919 DTCI_DTCSource_77F 9;
BA_ "SignalType" SG_ 1919 DTCI_DTCSource_77F "UNM";
BA_ "VNSigAllNodes" SG_ 1919 DTCI_DTCSource_77F 1;
BA_ "SignalLongName" SG_ 1919 DTCI_DTCTriggered_77F "Diagnostic Trouble Code Information Extended 77F : Diagnostic Trouble Code Triggered";
BA_ "PacketOrder" SG_ 1919 DTCI_DTCTriggered_77F 8;
BA_ "SignalType" SG_ 1919 DTCI_DTCTriggered_77F "BLN";
BA_ "VNSigAllNodes" SG_ 1919 DTCI_DTCTriggered_77F 1;
BA_ "SignalLongName" SG_ 1919 DTCIUnused7_77F "Diagnostic Trouble Code Information Extended 77F : Unused 7";
BA_ "PacketOrder" SG_ 1919 DTCIUnused7_77F 7;
BA_ "SignalType" SG_ 1919 DTCIUnused7_77F "BLN";
BA_ "VNSigAllNodes" SG_ 1919 DTCIUnused7_77F 1;
BA_ "SignalLongName" SG_ 1919 DTCIUnused6_77F "Diagnostic Trouble Code Information Extended 77F : Unused 6";
BA_ "PacketOrder" SG_ 1919 DTCIUnused6_77F 6;
BA_ "SignalType" SG_ 1919 DTCIUnused6_77F "BLN";
BA_ "VNSigAllNodes" SG_ 1919 DTCIUnused6_77F 1;
BA_ "SignalLongName" SG_ 1919 DTCIUnused5_77F "Diagnostic Trouble Code Information Extended 77F : Unused 5";
BA_ "PacketOrder" SG_ 1919 DTCIUnused5_77F 5;
BA_ "SignalType" SG_ 1919 DTCIUnused5_77F "BLN";
BA_ "VNSigAllNodes" SG_ 1919 DTCIUnused5_77F 1;
BA_ "SignalLongName" SG_ 1919 DTCIUnused4_77F "Diagnostic Trouble Code Information Extended 77F : Unused 4";
BA_ "PacketOrder" SG_ 1919 DTCIUnused4_77F 4;
BA_ "SignalType" SG_ 1919 DTCIUnused4_77F "BLN";
BA_ "VNSigAllNodes" SG_ 1919 DTCIUnused4_77F 1;
BA_ "SignalLongName" SG_ 1919 DTCIUnused3_77F "Diagnostic Trouble Code Information Extended 77F : Unused 3";
BA_ "PacketOrder" SG_ 1919 DTCIUnused3_77F 3;
BA_ "SignalType" SG_ 1919 DTCIUnused3_77F "BLN";
BA_ "VNSigAllNodes" SG_ 1919 DTCIUnused3_77F 1;
BA_ "SignalLongName" SG_ 1919 DTCIUnused2_77F "Diagnostic Trouble Code Information Extended 77F : Unused 2";
BA_ "PacketOrder" SG_ 1919 DTCIUnused2_77F 2;
BA_ "SignalType" SG_ 1919 DTCIUnused2_77F "BLN";
BA_ "VNSigAllNodes" SG_ 1919 DTCIUnused2_77F 1;
BA_ "SignalLongName" SG_ 1919 DTCIUnused1_77F "Diagnostic Trouble Code Information Extended 77F : Unused 1";
BA_ "PacketOrder" SG_ 1919 DTCIUnused1_77F 1;
BA_ "SignalType" SG_ 1919 DTCIUnused1_77F "BLN";
BA_ "VNSigAllNodes" SG_ 1919 DTCIUnused1_77F 1;
BA_ "SignalLongName" SG_ 2026 DgnInf "Diagnostic Information";
BA_ "SignalType" SG_ 2026 DgnInf "UNM";
BA_ "VNSigAllNodes" SG_ 2026 DgnInf 1;
BA_ "VNSigSLHSSharedDiagnostic" SG_ 2026 DgnInf 1;
BA_ "SignalLongName" SG_ 1514 DgnInf "Diagnostic Information";
BA_ "SignalType" SG_ 1514 DgnInf "UNM";
BA_ "VNSigAllNodes" SG_ 1514 DgnInf 1;
BA_ "VNSigSLHSSharedDiagnostic" SG_ 1514 DgnInf 1;
BA_ "SignalLongName" SG_ 1273 BrkSyCtl1EmsRldMlfAct "Brake System Control 1 Emissions Related Malfunction Active";
BA_ "SignalType" SG_ 1273 BrkSyCtl1EmsRldMlfAct "BLN";
BA_ "VNSigAllNodes" SG_ 1273 BrkSyCtl1EmsRldMlfAct 1;
BA_ "SignalLongName" SG_ 1273 BSC1ERDTC_CdNum "Brake System Control 1 Emissions Related DTC : Code Number";
BA_ "PacketOrder" SG_ 1273 BSC1ERDTC_CdNum 2;
BA_ "SignalType" SG_ 1273 BSC1ERDTC_CdNum "UNM";
BA_ "VNSigAllNodes" SG_ 1273 BSC1ERDTC_CdNum 1;
BA_ "SignalLongName" SG_ 1273 BSC1ERDTC_SysDes "Brake System Control 1 Related DTC : System Designator";
BA_ "PacketOrder" SG_ 1273 BSC1ERDTC_SysDes 1;
BA_ "SignalType" SG_ 1273 BSC1ERDTC_SysDes "ENM";
BA_ "VNSigAllNodes" SG_ 1273 BSC1ERDTC_SysDes 1;
BA_ "SignalLongName" SG_ 753 EBCMDS5_DTCStatus "Electronic Brake Control Module Diagnostic Status 5 : Diagnostic Trouble Code Status";
BA_ "PacketOrder" SG_ 753 EBCMDS5_DTCStatus 2;
BA_ "SignalType" SG_ 753 EBCMDS5_DTCStatus "ENM";
BA_ "VNSigAllNodes" SG_ 753 EBCMDS5_DTCStatus 1;
BA_ "SignalLongName" SG_ 753 EBCMDS5_DTCIndex "Electronic Brake Control Module Diagnostic Status 5 : Diagnostic Trouble Code Index";
BA_ "PacketOrder" SG_ 753 EBCMDS5_DTCIndex 1;
BA_ "SignalType" SG_ 753 EBCMDS5_DTCIndex "UNM";
BA_ "VNSigAllNodes" SG_ 753 EBCMDS5_DTCIndex 1;
BA_ "SignalLongName" SG_ 753 EBCMDS4_DTCStatus "Electronic Brake Control Module Diagnostic Status 4 : Diagnostic Trouble Code Status";
BA_ "PacketOrder" SG_ 753 EBCMDS4_DTCStatus 2;
BA_ "SignalType" SG_ 753 EBCMDS4_DTCStatus "ENM";
BA_ "VNSigAllNodes" SG_ 753 EBCMDS4_DTCStatus 1;
BA_ "SignalLongName" SG_ 753 EBCMDS4_DTCIndex "Electronic Brake Control Module Diagnostic Status 4 : Diagnostic Trouble Code Index";
BA_ "PacketOrder" SG_ 753 EBCMDS4_DTCIndex 1;
BA_ "SignalType" SG_ 753 EBCMDS4_DTCIndex "UNM";
BA_ "VNSigAllNodes" SG_ 753 EBCMDS4_DTCIndex 1;
BA_ "SignalLongName" SG_ 753 EBCMDS3_DTCStatus "Electronic Brake Control Module Diagnostic Status 3 : Diagnostic Trouble Code Status";
BA_ "PacketOrder" SG_ 753 EBCMDS3_DTCStatus 2;
BA_ "SignalType" SG_ 753 EBCMDS3_DTCStatus "ENM";
BA_ "VNSigAllNodes" SG_ 753 EBCMDS3_DTCStatus 1;
BA_ "SignalLongName" SG_ 753 EBCMDS3_DTCIndex "Electronic Brake Control Module Diagnostic Status 3 : Diagnostic Trouble Code Index";
BA_ "PacketOrder" SG_ 753 EBCMDS3_DTCIndex 1;
BA_ "SignalType" SG_ 753 EBCMDS3_DTCIndex "UNM";
BA_ "VNSigAllNodes" SG_ 753 EBCMDS3_DTCIndex 1;
BA_ "SignalLongName" SG_ 753 EBCMDS2_DTCStatus "Electronic Brake Control Module Diagnostic Status 2 : Diagnostic Trouble Code Status";
BA_ "PacketOrder" SG_ 753 EBCMDS2_DTCStatus 2;
BA_ "SignalType" SG_ 753 EBCMDS2_DTCStatus "ENM";
BA_ "VNSigAllNodes" SG_ 753 EBCMDS2_DTCStatus 1;
BA_ "SignalLongName" SG_ 753 EBCMDS2_DTCIndex "Electronic Brake Control Module Diagnostic Status 2 : Diagnostic Trouble Code Index";
BA_ "PacketOrder" SG_ 753 EBCMDS2_DTCIndex 1;
BA_ "SignalType" SG_ 753 EBCMDS2_DTCIndex "UNM";
BA_ "VNSigAllNodes" SG_ 753 EBCMDS2_DTCIndex 1;
BA_ "SignalLongName" SG_ 753 EBCMDS1_DTCStatus "Electronic Brake Control Module Diagnostic Status 1 : Diagnostic Trouble Code Status";
BA_ "PacketOrder" SG_ 753 EBCMDS1_DTCStatus 2;
BA_ "SignalType" SG_ 753 EBCMDS1_DTCStatus "ENM";
BA_ "VNSigAllNodes" SG_ 753 EBCMDS1_DTCStatus 1;
BA_ "SignalLongName" SG_ 753 EBCMDS1_DTCIndex "Electronic Brake Control Module Diagnostic Status 1 : Diagnostic Trouble Code Index";
BA_ "PacketOrder" SG_ 753 EBCMDS1_DTCIndex 1;
BA_ "SignalType" SG_ 753 EBCMDS1_DTCIndex "UNM";
BA_ "VNSigAllNodes" SG_ 753 EBCMDS1_DTCIndex 1;
BA_ "SignalLongName" SG_ 407 TransRatioV "Transmission Ratio Validity";
BA_ "SignalType" SG_ 407 TransRatioV "ENM";
BA_ "VNSigAllNodes" SG_ 407 TransRatioV 1;
BA_ "SignalLongName" SG_ 407 TransRatio "Transmission Ratio";
BA_ "SignalType" SG_ 407 TransRatio "UNM";
BA_ "VNSigAllNodes" SG_ 407 TransRatio 1;
BA_ "SignalLongName" SG_ 407 TrnsOvrallActTorqRatioV "Transmission Overall Actual Torque Ratio Validity";
BA_ "SignalType" SG_ 407 TrnsOvrallActTorqRatioV "ENM";
BA_ "VNSigAllNodes" SG_ 407 TrnsOvrallActTorqRatioV 1;
BA_ "SignalLongName" SG_ 407 TrnsOvrallActTorqRatio "Transmission Overall Actual Torque Ratio";
BA_ "SignalType" SG_ 407 TrnsOvrallActTorqRatio "SNM";
BA_ "VNSigAllNodes" SG_ 407 TrnsOvrallActTorqRatio 1;
BA_ "SignalLongName" SG_ 189 TransMnPressEstmd "Transmission Main Pressure Estimated";
BA_ "SignalType" SG_ 189 TransMnPressEstmd "UNM";
BA_ "VNSigAllNodes" SG_ 189 TransMnPressEstmd 1;
BA_ "SignalLongName" SG_ 189 TrnsInpMinSpdRq "Transmission Input Minimum Speed Request";
BA_ "SignalType" SG_ 189 TrnsInpMinSpdRq "ENM";
BA_ "VNSigAllNodes" SG_ 189 TrnsInpMinSpdRq 1;
BA_ "SignalLongName" SG_ 189 TrnsHydPrsDsrd "Transmission Hydraulic Pressure Desired";
BA_ "SignalType" SG_ 189 TrnsHydPrsDsrd "UNM";
BA_ "VNSigAllNodes" SG_ 189 TrnsHydPrsDsrd 1;
BA_ "SignalLongName" SG_ 189 TransAuxPumpSpdDsrd "Transmission Auxiliary Pump Speed Desired";
BA_ "SignalType" SG_ 189 TransAuxPumpSpdDsrd "UNM";
BA_ "VNSigAllNodes" SG_ 189 TransAuxPumpSpdDsrd 1;
BA_ "SignalLongName" SG_ 189 HybDisengCruzCmnd "Hybrid Disengage Cruise Commanded";
BA_ "SignalType" SG_ 189 HybDisengCruzCmnd "BLN";
BA_ "VNSigAllNodes" SG_ 189 HybDisengCruzCmnd 1;
BA_ "GenSigStartValue" SG_ 189 TransVehTopSpdLim 255;
BA_ "SignalLongName" SG_ 189 TransVehTopSpdLim "Transmission Vehicle Top Speed Limit Value";
BA_ "SignalType" SG_ 189 TransVehTopSpdLim "UNM";
BA_ "VNSigAllNodes" SG_ 189 TransVehTopSpdLim 1;
BA_ "SignalLongName" SG_ 189 TransMinVoltReq "Transmission Minimum Voltage Request";
BA_ "SignalType" SG_ 189 TransMinVoltReq "UNM";
BA_ "VNSigAllNodes" SG_ 189 TransMinVoltReq 1;
BA_ "SignalLongName" SG_ 189 TrnsRtoCntlSysFlt "Transmission Ratio Control System Fault";
BA_ "SignalType" SG_ 189 TrnsRtoCntlSysFlt "BLN";
BA_ "VNSigAllNodes" SG_ 189 TrnsRtoCntlSysFlt 1;
BA_ "SignalLongName" SG_ 1221 SpdLmtVsnFsdSpdUnt "Speed Limit Vision Fused Speed Unit";
BA_ "SignalType" SG_ 1221 SpdLmtVsnFsdSpdUnt "ENM";
BA_ "VNSigAllNodes" SG_ 1221 SpdLmtVsnFsdSpdUnt 1;
BA_ "GenSigSendType" SG_ 1221 SpdLmtVsnFsdSpdUnt 10;
BA_ "SignalLongName" SG_ 1221 SpdLmtVnFsSpdNwDet "Speed Limit Vision Fused Speed New Detected";
BA_ "SignalType" SG_ 1221 SpdLmtVnFsSpdNwDet "BLN";
BA_ "VNSigAllNodes" SG_ 1221 SpdLmtVnFsSpdNwDet 1;
BA_ "GenSigSendType" SG_ 1221 SpdLmtVnFsSpdNwDet 10;
BA_ "SignalLongName" SG_ 1221 SpdLmtVsnFsdSpdM "Speed Limit Vision Fused Speed Mask";
BA_ "SignalType" SG_ 1221 SpdLmtVsnFsdSpdM "ENM";
BA_ "VNSigAllNodes" SG_ 1221 SpdLmtVsnFsdSpdM 1;
BA_ "GenSigSendType" SG_ 1221 SpdLmtVsnFsdSpdM 10;
BA_ "SignalLongName" SG_ 1221 SpdLmtVsnFsdSpd "Speed Limit Vision Fused Speed";
BA_ "SignalType" SG_ 1221 SpdLmtVsnFsdSpd "UNM";
BA_ "VNSigAllNodes" SG_ 1221 SpdLmtVsnFsdSpd 1;
BA_ "GenSigDeltaValue" SG_ 1221 SpdLmtVsnFsdSpd 1;
BA_ "GenSigSendType" SG_ 1221 SpdLmtVsnFsdSpd 12;
BA_ "SignalLongName" SG_ 1221 CCClntCrcFlwRtReq "Climate Control Coolant Circulation Flow Rate Request";
BA_ "SignalType" SG_ 1221 CCClntCrcFlwRtReq "UNM";
BA_ "VNSigAllNodes" SG_ 1221 CCClntCrcFlwRtReq 1;
BA_ "GenSigDeltaValue" SG_ 1221 CCClntCrcFlwRtReq 1;
BA_ "GenSigSendType" SG_ 1221 CCClntCrcFlwRtReq 12;
BA_ "GenSigSendOnInit" SG_ 1221 CCClntCrcFlwRtReq 2;
BA_ "SignalLongName" SG_ 1243 CSERDTC_CdNum "Chassis System Emissions Related DTC : Code Number";
BA_ "PacketOrder" SG_ 1243 CSERDTC_CdNum 2;
BA_ "SignalType" SG_ 1243 CSERDTC_CdNum "UNM";
BA_ "VNSigAllNodes" SG_ 1243 CSERDTC_CdNum 1;
BA_ "SignalLongName" SG_ 1243 CSERDTC_SysDes "Chassis System Emissions Related DTC : System Designator";
BA_ "PacketOrder" SG_ 1243 CSERDTC_SysDes 1;
BA_ "SignalType" SG_ 1243 CSERDTC_SysDes "ENM";
BA_ "VNSigAllNodes" SG_ 1243 CSERDTC_SysDes 1;
BA_ "SignalLongName" SG_ 1243 ChsSysEmmRelMalfAct "Chassis System Emissions Related Malfunction Active";
BA_ "SignalType" SG_ 1243 ChsSysEmmRelMalfAct "BLN";
BA_ "VNSigAllNodes" SG_ 1243 ChsSysEmmRelMalfAct 1;
BA_ "GenSigStartValue" SG_ 1239 IBSBatSOC 196;
BA_ "SignalLongName" SG_ 1239 IBSBatSOC "Intelligent Battery Sensor Battery State of Charge";
BA_ "SignalType" SG_ 1239 IBSBatSOC "UNM";
BA_ "VNSigAllNodes" SG_ 1239 IBSBatSOC 1;
BA_ "GenSigStartValue" SG_ 1239 BattTemp 65;
BA_ "SignalLongName" SG_ 1239 BattTemp "Battery Temperature";
BA_ "SignalType" SG_ 1239 BattTemp "UNM";
BA_ "VNSigAllNodes" SG_ 1239 BattTemp 1;
BA_ "GenSigStartValue" SG_ 1239 BatSOH 203.999928600025;
BA_ "SignalLongName" SG_ 1239 BatSOH "Battery State Of Health";
BA_ "SignalType" SG_ 1239 BatSOH "UNM";
BA_ "VNSigAllNodes" SG_ 1239 BatSOH 1;
BA_ "GenSigStartValue" SG_ 1239 BatSOFVolt 200;
BA_ "SignalLongName" SG_ 1239 BatSOFVolt "Battery State Of Function Voltage";
BA_ "SignalType" SG_ 1239 BatSOFVolt "UNM";
BA_ "VNSigAllNodes" SG_ 1239 BatSOFVolt 1;
BA_ "SignalLongName" SG_ 1239 BattSOXStat "Battery SOX Status";
BA_ "SignalType" SG_ 1239 BattSOXStat "ENM";
BA_ "VNSigAllNodes" SG_ 1239 BattSOXStat 1;
BA_ "SignalLongName" SG_ 1239 BattTempV "Battery Temperature Validity";
BA_ "SignalType" SG_ 1239 BattTempV "ENM";
BA_ "VNSigAllNodes" SG_ 1239 BattTempV 1;
BA_ "SignalLongName" SG_ 508 LonLatAccSnsChk "Longitudinal/Lateral Acceleration Sensor state0589";
BA_ "SignalType" SG_ 508 LonLatAccSnsChk "UNM";
BA_ "VNSigAllNodes" SG_ 508 LonLatAccSnsChk 1;
BA_ "SignalLongName" SG_ 508 LonLatAccSnsValARC "Longitudinal/Lateral Acceleration Sensor Value Alive Rolling Count";
BA_ "SignalType" SG_ 508 LonLatAccSnsValARC "UNM";
BA_ "VNSigAllNodes" SG_ 508 LonLatAccSnsValARC 1;
BA_ "SignalLongName" SG_ 508 LatAccSnsVal "Lateral Acceleration Sensor Value";
BA_ "SignalType" SG_ 508 LatAccSnsVal "SNM";
BA_ "VNSigAllNodes" SG_ 508 LatAccSnsVal 1;
BA_ "SignalLongName" SG_ 508 LonAccSnsVal "Longitudinal Acceleration Sensor Value";
BA_ "SignalType" SG_ 508 LonAccSnsVal "SNM";
BA_ "VNSigAllNodes" SG_ 508 LonAccSnsVal 1;
BA_ "SignalLongName" SG_ 508 ChsSysTtlBkAxlTqStARC "Chassis System Total Brake Axle Torque Status Alive Rolling Count";
BA_ "SignalType" SG_ 508 ChsSysTtlBkAxlTqStARC "UNM";
BA_ "VNSigAllNodes" SG_ 508 ChsSysTtlBkAxlTqStARC 1;
BA_ "SignalLongName" SG_ 508 CSTBATS_TrqVl "Chassis System Total Brake Axle Torque Status : Torque Value";
BA_ "PacketOrder" SG_ 508 CSTBATS_TrqVl 2;
BA_ "SignalType" SG_ 508 CSTBATS_TrqVl "UNM";
BA_ "VNSigAllNodes" SG_ 508 CSTBATS_TrqVl 1;
BA_ "SignalLongName" SG_ 508 CSTBATS_TrqVlV "Chassis System Total Brake Axle Torque Status : Torque Value Validity";
BA_ "PacketOrder" SG_ 508 CSTBATS_TrqVlV 1;
BA_ "SignalType" SG_ 508 CSTBATS_TrqVlV "ENM";
BA_ "VNSigAllNodes" SG_ 508 CSTBATS_TrqVlV 1;
BA_ "SignalLongName" SG_ 422 TrnsAuxPrsDisOvrrdOn "Transmission Auxiliary Pressure Discharge Override On";
BA_ "SignalType" SG_ 422 TrnsAuxPrsDisOvrrdOn "BLN";
BA_ "VNSigAllNodes" SG_ 422 TrnsAuxPrsDisOvrrdOn 1;
BA_ "SignalLongName" SG_ 422 TransEngShtdwnReqdPVa "Transmission Engine Shutdown Requested Protection Value";
BA_ "SignalType" SG_ 422 TransEngShtdwnReqdPVa "UNM";
BA_ "VNSigAllNodes" SG_ 422 TransEngShtdwnReqdPVa 1;
BA_ "SignalLongName" SG_ 422 TrnsEngShtdwnRqARC "Transmission Engine Shutdown Requested Alive Rolling Count";
BA_ "SignalType" SG_ 422 TrnsEngShtdwnRqARC "UNM";
BA_ "VNSigAllNodes" SG_ 422 TrnsEngShtdwnRqARC 1;
BA_ "SignalLongName" SG_ 422 TransEngShtdwnRqd "Transmission Engine Shutdown Requested";
BA_ "SignalType" SG_ 422 TransEngShtdwnRqd "BLN";
BA_ "VNSigAllNodes" SG_ 422 TransEngShtdwnRqd 1;
BA_ "SignalLongName" SG_ 422 TransCrksftTqLoadV "Transmission Crankshaft Torque Load Validity";
BA_ "SignalType" SG_ 422 TransCrksftTqLoadV "ENM";
BA_ "VNSigAllNodes" SG_ 422 TransCrksftTqLoadV 1;
BA_ "SignalLongName" SG_ 422 TransCrksftTqLoad "Transmission Crankshaft Torque Load";
BA_ "SignalType" SG_ 422 TransCrksftTqLoad "UNM";
BA_ "VNSigAllNodes" SG_ 422 TransCrksftTqLoad 1;
BA_ "SignalLongName" SG_ 422 TrStPTGrdBrkDsMdOvr "Transmission State Powertrain Grade Braking  Disable Mode Override";
BA_ "SignalType" SG_ 422 TrStPTGrdBrkDsMdOvr "ENM";
BA_ "VNSigAllNodes" SG_ 422 TrStPTGrdBrkDsMdOvr 1;
BA_ "SignalLongName" SG_ 422 TrnsHybEngSrtStpOvrd "Transmission Hybrid Engine Start Stop Override";
BA_ "SignalType" SG_ 422 TrnsHybEngSrtStpOvrd "ENM";
BA_ "VNSigAllNodes" SG_ 422 TrnsHybEngSrtStpOvrd 1;
BA_ "SignalLongName" SG_ 971 BatVltHiResV "Battery Voltage High Resolution Validity";
BA_ "SignalType" SG_ 971 BatVltHiResV "ENM";
BA_ "VNSigAllNodes" SG_ 971 BatVltHiResV 1;
BA_ "GenSigStartValue" SG_ 971 BatVltHiRes 12800;
BA_ "SignalLongName" SG_ 971 BatVltHiRes "Battery Voltage High Resolution";
BA_ "SignalType" SG_ 971 BatVltHiRes "UNM";
BA_ "VNSigAllNodes" SG_ 971 BatVltHiRes 1;
BA_ "SignalLongName" SG_ 971 BCHR_BattCrntRwVal "Battery Current High Resolution : Battery Current Raw Value";
BA_ "PacketOrder" SG_ 971 BCHR_BattCrntRwVal 3;
BA_ "SignalType" SG_ 971 BCHR_BattCrntRwVal "UNM";
BA_ "VNSigAllNodes" SG_ 971 BCHR_BattCrntRwVal 1;
BA_ "SignalLongName" SG_ 971 BCHR_BattCrntRwVlMu "Battery Current High Resolution : Battery Current Raw Value Multiplier";
BA_ "PacketOrder" SG_ 971 BCHR_BattCrntRwVlMu 2;
BA_ "SignalType" SG_ 971 BCHR_BattCrntRwVlMu "ENM";
BA_ "VNSigAllNodes" SG_ 971 BCHR_BattCrntRwVlMu 1;
BA_ "SignalLongName" SG_ 971 BCHR_BattCrntRwValV "Battery Current High Resolution : Battery Current Raw Value Validity";
BA_ "PacketOrder" SG_ 971 BCHR_BattCrntRwValV 1;
BA_ "SignalType" SG_ 971 BCHR_BattCrntRwValV "ENM";
BA_ "VNSigAllNodes" SG_ 971 BCHR_BattCrntRwValV 1;
BA_ "SignalLongName" SG_ 209 ChsBrkPdlPsERltdV "Chassis Brake Pedal Position Emissions Related Validity";
BA_ "SignalType" SG_ 209 ChsBrkPdlPsERltdV "ENM";
BA_ "VNSigAllNodes" SG_ 209 ChsBrkPdlPsERltdV 1;
BA_ "SignalLongName" SG_ 209 ChsBrkPdlPsERltdPVal "Chassis Brake Pedal Position Emissions Related Protection Value";
BA_ "SignalType" SG_ 209 ChsBrkPdlPsERltdPVal "UNM";
BA_ "VNSigAllNodes" SG_ 209 ChsBrkPdlPsERltdPVal 1;
BA_ "SignalLongName" SG_ 209 ChsBrkPdlPsERltdARC "Chassis Brake Pedal Position Emissions Related Alive Rolling Count";
BA_ "SignalType" SG_ 209 ChsBrkPdlPsERltdARC "UNM";
BA_ "VNSigAllNodes" SG_ 209 ChsBrkPdlPsERltdARC 1;
BA_ "SignalLongName" SG_ 209 ChsBrkPdlPsERltd "Chassis Brake Pedal Position Emissions Related";
BA_ "SignalType" SG_ 209 ChsBrkPdlPsERltd "UNM";
BA_ "VNSigAllNodes" SG_ 209 ChsBrkPdlPsERltd 1;
BA_ "SignalLongName" SG_ 209 DrvIntndTtlBrkTrqPVal "Driver Intended Total Brake Torque Protection Value";
BA_ "SignalType" SG_ 209 DrvIntndTtlBrkTrqPVal "UNM";
BA_ "VNSigAllNodes" SG_ 209 DrvIntndTtlBrkTrqPVal 1;
BA_ "SignalLongName" SG_ 209 DrvIntndTtlBrkTrqARC "Driver Intended Total Brake Torque Alive Rolling Count";
BA_ "SignalType" SG_ 209 DrvIntndTtlBrkTrqARC "UNM";
BA_ "VNSigAllNodes" SG_ 209 DrvIntndTtlBrkTrqARC 1;
BA_ "SignalLongName" SG_ 209 DrvIntndTtlBrkTrq "Driver Intended Total Brake Torque";
BA_ "SignalType" SG_ 209 DrvIntndTtlBrkTrq "UNM";
BA_ "VNSigAllNodes" SG_ 209 DrvIntndTtlBrkTrq 1;
BA_ "SignalLongName" SG_ 454 ChsSysPrdAxlTqRqPV "Chassis System Predicted Axle Torque Request Protection Value";
BA_ "SignalType" SG_ 454 ChsSysPrdAxlTqRqPV "UNM";
BA_ "VNSigAllNodes" SG_ 454 ChsSysPrdAxlTqRqPV 1;
BA_ "SignalLongName" SG_ 454 CSPATR_TrqIntrvnTyp "Chassis System Predicted Axle Torque Request : Torque Intervention Type";
BA_ "PacketOrder" SG_ 454 CSPATR_TrqIntrvnTyp 3;
BA_ "SignalType" SG_ 454 CSPATR_TrqIntrvnTyp "ENM";
BA_ "VNSigAllNodes" SG_ 454 CSPATR_TrqIntrvnTyp 1;
BA_ "SignalLongName" SG_ 454 CSPATR_PrdTrqRqVal "Chassis System Predicted Axle Torque Request : Predicted Torque Request Value";
BA_ "PacketOrder" SG_ 454 CSPATR_PrdTrqRqVal 2;
BA_ "SignalType" SG_ 454 CSPATR_PrdTrqRqVal "UNM";
BA_ "VNSigAllNodes" SG_ 454 CSPATR_PrdTrqRqVal 1;
BA_ "SignalLongName" SG_ 454 CSPATR_TrqRqTyp "Chassis System Predicted Axle Torque Request : Torque Request Type";
BA_ "PacketOrder" SG_ 454 CSPATR_TrqRqTyp 1;
BA_ "SignalType" SG_ 454 CSPATR_TrqRqTyp "ENM";
BA_ "VNSigAllNodes" SG_ 454 CSPATR_TrqRqTyp 1;
BA_ "SignalLongName" SG_ 454 ChsSysImmAxlTqRqVal "Chassis System Immediate Axle Torque Request Value";
BA_ "SignalType" SG_ 454 ChsSysImmAxlTqRqVal "UNM";
BA_ "VNSigAllNodes" SG_ 454 ChsSysImmAxlTqRqVal 1;
BA_ "SignalLongName" SG_ 454 ChsSysAxlTqRqRspTyp "Chassis System Axle Torque Request Response Type";
BA_ "SignalType" SG_ 454 ChsSysAxlTqRqRspTyp "ENM";
BA_ "VNSigAllNodes" SG_ 454 ChsSysAxlTqRqRspTyp 1;
BA_ "SignalLongName" SG_ 454 ChsSysPrdAxlTqRqARC "Chassis System Predicted Axle Torque Request Alive Rolling Count";
BA_ "SignalType" SG_ 454 ChsSysPrdAxlTqRqARC "UNM";
BA_ "VNSigAllNodes" SG_ 454 ChsSysPrdAxlTqRqARC 1;
BA_ "SignalLongName" SG_ 1189 TAFR_AirFlwReqTyp "Transmission Air Flow Request : Air Flow Request Type";
BA_ "PacketOrder" SG_ 1189 TAFR_AirFlwReqTyp 2;
BA_ "SignalType" SG_ 1189 TAFR_AirFlwReqTyp "ENM";
BA_ "VNSigAllNodes" SG_ 1189 TAFR_AirFlwReqTyp 1;
BA_ "SignalLongName" SG_ 1189 TAFR_AirFlwReqPrcnt "Transmission Air Flow Request : Air Flow Request Percent";
BA_ "PacketOrder" SG_ 1189 TAFR_AirFlwReqPrcnt 1;
BA_ "SignalType" SG_ 1189 TAFR_AirFlwReqPrcnt "UNM";
BA_ "VNSigAllNodes" SG_ 1189 TAFR_AirFlwReqPrcnt 1;
BA_ "GenSigStartValue" SG_ 421 AccPwrMdlHiVltInpCrnt 40;
BA_ "SignalLongName" SG_ 421 AccPwrMdlHiVltInpCrnt "Accessory Power Module High Voltage Input Current";
BA_ "SignalType" SG_ 421 AccPwrMdlHiVltInpCrnt "UNM";
BA_ "VNSigAllNodes" SG_ 421 AccPwrMdlHiVltInpCrnt 1;
BA_ "SignalLongName" SG_ 421 AccPwrMdlHiVltInpCrntV "Accessory Power Module High Voltage Input Current Validity";
BA_ "SignalType" SG_ 421 AccPwrMdlHiVltInpCrntV "ENM";
BA_ "VNSigAllNodes" SG_ 421 AccPwrMdlHiVltInpCrntV 1;
BA_ "SignalLongName" SG_ 421 HybAuxTransPresCmndOn "Hybrid Auxiliary Transmission Pressure Commanded On";
BA_ "SignalType" SG_ 421 HybAuxTransPresCmndOn "BLN";
BA_ "VNSigAllNodes" SG_ 421 HybAuxTransPresCmndOn 1;
BA_ "SignalLongName" SG_ 421 HTGR_ReqVal "Hybrid Transmission Gear Request : Request Value";
BA_ "PacketOrder" SG_ 421 HTGR_ReqVal 3;
BA_ "SignalType" SG_ 421 HTGR_ReqVal "ENM";
BA_ "VNSigAllNodes" SG_ 421 HTGR_ReqVal 1;
BA_ "SignalLongName" SG_ 421 HTGR_ReqTyp "Hybrid Transmission Gear Request : Request Type";
BA_ "PacketOrder" SG_ 421 HTGR_ReqTyp 2;
BA_ "SignalType" SG_ 421 HTGR_ReqTyp "ENM";
BA_ "VNSigAllNodes" SG_ 421 HTGR_ReqTyp 1;
BA_ "SignalLongName" SG_ 421 HTGR_ReqPrty "Hybrid Transmission Gear Request : Request Priority";
BA_ "PacketOrder" SG_ 421 HTGR_ReqPrty 1;
BA_ "SignalType" SG_ 421 HTGR_ReqPrty "ENM";
BA_ "VNSigAllNodes" SG_ 421 HTGR_ReqPrty 1;
BA_ "SignalLongName" SG_ 421 HTCCR_ReqVal "Hybrid Torque Converter Clutch Request : Request Value";
BA_ "PacketOrder" SG_ 421 HTCCR_ReqVal 2;
BA_ "SignalType" SG_ 421 HTCCR_ReqVal "ENM";
BA_ "VNSigAllNodes" SG_ 421 HTCCR_ReqVal 1;
BA_ "SignalLongName" SG_ 421 HTCCR_ReqPrty "Hybrid Torque Converter Clutch Request : Request Priority";
BA_ "PacketOrder" SG_ 421 HTCCR_ReqPrty 1;
BA_ "SignalType" SG_ 421 HTCCR_ReqPrty "ENM";
BA_ "VNSigAllNodes" SG_ 421 HTCCR_ReqPrty 1;
BA_ "SignalLongName" SG_ 421 TrnsAuxPmpAct "Transmission Auxiliary Pump Active";
BA_ "SignalType" SG_ 421 TrnsAuxPmpAct "BLN";
BA_ "VNSigAllNodes" SG_ 421 TrnsAuxPmpAct 1;
BA_ "SignalLongName" SG_ 421 HybEconBhvAlwd "Hybrid Economy Behavior Allowed";
BA_ "SignalType" SG_ 421 HybEconBhvAlwd "BLN";
BA_ "VNSigAllNodes" SG_ 421 HybEconBhvAlwd 1;
BA_ "SignalLongName" SG_ 421 HybTwHaulBhvAlwd "Hybrid Tow Haul Behavior Allowed";
BA_ "SignalType" SG_ 421 HybTwHaulBhvAlwd "BLN";
BA_ "VNSigAllNodes" SG_ 421 HybTwHaulBhvAlwd 1;
BA_ "SignalLongName" SG_ 421 HybSnsBrkPdlPosV "Hybrid Sensed Brake Pedal Position Validity";
BA_ "SignalType" SG_ 421 HybSnsBrkPdlPosV "ENM";
BA_ "VNSigAllNodes" SG_ 421 HybSnsBrkPdlPosV 1;
BA_ "SignalLongName" SG_ 421 HybSnsBrkPdlPosPVal "Hybrid Sensed Brake Pedal Position Protection Value";
BA_ "SignalType" SG_ 421 HybSnsBrkPdlPosPVal "UNM";
BA_ "VNSigAllNodes" SG_ 421 HybSnsBrkPdlPosPVal 1;
BA_ "SignalLongName" SG_ 421 HybSnsBrkPdlPosARC "Hybrid Sensed Brake Pedal Position Alive Rolling Count";
BA_ "SignalType" SG_ 421 HybSnsBrkPdlPosARC "UNM";
BA_ "VNSigAllNodes" SG_ 421 HybSnsBrkPdlPosARC 1;
BA_ "SignalLongName" SG_ 421 HybSnsBrkPdlPos "Hybrid Sensed Brake Pedal Position";
BA_ "SignalType" SG_ 421 HybSnsBrkPdlPos "UNM";
BA_ "VNSigAllNodes" SG_ 421 HybSnsBrkPdlPos 1;
BA_ "SignalLongName" SG_ 456 PerfTrcEngSpdReqProt "Performance Traction Engine Speed Request Protection";
BA_ "SignalType" SG_ 456 PerfTrcEngSpdReqProt "UNM";
BA_ "VNSigAllNodes" SG_ 456 PerfTrcEngSpdReqProt 1;
BA_ "SignalLongName" SG_ 456 PTESR_EngSpdRqVal "Performance Traction Engine Speed Request : Engine Speed Request Value";
BA_ "PacketOrder" SG_ 456 PTESR_EngSpdRqVal 3;
BA_ "SignalType" SG_ 456 PTESR_EngSpdRqVal "UNM";
BA_ "VNSigAllNodes" SG_ 456 PTESR_EngSpdRqVal 1;
BA_ "SignalLongName" SG_ 456 PTESR_EngSpdCntlRs "Performance Traction Engine Speed Request : Engine Speed Control Response";
BA_ "PacketOrder" SG_ 456 PTESR_EngSpdCntlRs 2;
BA_ "SignalType" SG_ 456 PTESR_EngSpdCntlRs "ENM";
BA_ "VNSigAllNodes" SG_ 456 PTESR_EngSpdCntlRs 1;
BA_ "SignalLongName" SG_ 456 PTESR_EngSpdIntTyp "Performance Traction Engine Speed Request : Engine Speed Intervention Type";
BA_ "PacketOrder" SG_ 456 PTESR_EngSpdIntTyp 1;
BA_ "SignalType" SG_ 456 PTESR_EngSpdIntTyp "ENM";
BA_ "VNSigAllNodes" SG_ 456 PTESR_EngSpdIntTyp 1;
BA_ "SignalLongName" SG_ 456 PerfTrcTrqRqProt "Performance Traction Torque Request Protection";
BA_ "SignalType" SG_ 456 PerfTrcTrqRqProt "UNM";
BA_ "VNSigAllNodes" SG_ 456 PerfTrcTrqRqProt 1;
BA_ "SignalLongName" SG_ 456 PTTR_TrqReqVal "Performance Traction Torque Request : Torque Request Value";
BA_ "PacketOrder" SG_ 456 PTTR_TrqReqVal 3;
BA_ "SignalType" SG_ 456 PTTR_TrqReqVal "UNM";
BA_ "VNSigAllNodes" SG_ 456 PTTR_TrqReqVal 1;
BA_ "SignalLongName" SG_ 456 PTTR_TrqRedRlzSugg "Performance Traction Torque Request : Torque Reduction Realization Suggestion";
BA_ "PacketOrder" SG_ 456 PTTR_TrqRedRlzSugg 2;
BA_ "SignalType" SG_ 456 PTTR_TrqRedRlzSugg "ENM";
BA_ "VNSigAllNodes" SG_ 456 PTTR_TrqRedRlzSugg 1;
BA_ "SignalLongName" SG_ 456 PTTR_TrqInvTyp "Performance Traction Torque Request : Torque Intervention Type";
BA_ "PacketOrder" SG_ 456 PTTR_TrqInvTyp 1;
BA_ "SignalType" SG_ 456 PTTR_TrqInvTyp "ENM";
BA_ "VNSigAllNodes" SG_ 456 PTTR_TrqInvTyp 1;
BA_ "SignalLongName" SG_ 456 PerfTrcARC "Performance Traction Alive Rolling Count";
BA_ "SignalType" SG_ 456 PerfTrcARC "UNM";
BA_ "VNSigAllNodes" SG_ 456 PerfTrcARC 1;
BA_ "SignalLongName" SG_ 393 TrnsTrqCap "Transmission Torque Capacity";
BA_ "SignalType" SG_ 393 TrnsTrqCap "UNM";
BA_ "VNSigAllNodes" SG_ 393 TrnsTrqCap 1;
BA_ "SignalLongName" SG_ 393 TIDCTR_TrqIntvTyp "Transmission Immediate Directional Crankshaft Torque Request : Torque Intervention Type";
BA_ "PacketOrder" SG_ 393 TIDCTR_TrqIntvTyp 3;
BA_ "SignalType" SG_ 393 TIDCTR_TrqIntvTyp "ENM";
BA_ "VNSigAllNodes" SG_ 393 TIDCTR_TrqIntvTyp 1;
BA_ "SignalLongName" SG_ 393 TIDCTR_TrqReqVal "Transmission Immediate Directional Crankshaft Torque Request : Torque Request Value";
BA_ "PacketOrder" SG_ 393 TIDCTR_TrqReqVal 2;
BA_ "SignalType" SG_ 393 TIDCTR_TrqReqVal "UNM";
BA_ "VNSigAllNodes" SG_ 393 TIDCTR_TrqReqVal 1;
BA_ "SignalLongName" SG_ 393 TIDCTR_TrqRespTyp "Transmission Immediate Directional Crankshaft Torque Request : Torque Response Type";
BA_ "PacketOrder" SG_ 393 TIDCTR_TrqRespTyp 1;
BA_ "SignalType" SG_ 393 TIDCTR_TrqRespTyp "ENM";
BA_ "VNSigAllNodes" SG_ 393 TIDCTR_TrqRespTyp 1;
BA_ "SignalLongName" SG_ 393 TrnsPdCrkshftTqRqPVa "Transmission Predicted Crankshaft Torque Request Protection Value";
BA_ "SignalType" SG_ 393 TrnsPdCrkshftTqRqPVa "UNM";
BA_ "VNSigAllNodes" SG_ 393 TrnsPdCrkshftTqRqPVa 1;
BA_ "SignalLongName" SG_ 393 TPCTR_TorqReqVal "Transmission Predicted Crankshaft Torque Request : Torque Request Value";
BA_ "PacketOrder" SG_ 393 TPCTR_TorqReqVal 2;
BA_ "SignalType" SG_ 393 TPCTR_TorqReqVal "UNM";
BA_ "VNSigAllNodes" SG_ 393 TPCTR_TorqReqVal 1;
BA_ "SignalLongName" SG_ 393 TPCTR_TrqIntrvnTyp "Transmission Predicted Crankshaft Torque Request : Torque Intervention Type";
BA_ "PacketOrder" SG_ 393 TPCTR_TrqIntrvnTyp 1;
BA_ "SignalType" SG_ 393 TPCTR_TrqIntrvnTyp "ENM";
BA_ "VNSigAllNodes" SG_ 393 TPCTR_TrqIntrvnTyp 1;
BA_ "SignalLongName" SG_ 393 TrnsTrqRqALC "Transmission Torque Request Alive Rolling Count";
BA_ "SignalType" SG_ 393 TrnsTrqRqALC "UNM";
BA_ "VNSigAllNodes" SG_ 393 TrnsTrqRqALC 1;
BA_ "SignalLongName" SG_ 199 TORSTimestamp "Transmission Output Rotational Status : Transmission Output Rotational Status Timestamp";
BA_ "PacketOrder" SG_ 199 TORSTimestamp 6;
BA_ "SignalType" SG_ 199 TORSTimestamp "UNM";
BA_ "VNSigAllNodes" SG_ 199 TORSTimestamp 1;
BA_ "SignalLongName" SG_ 199 TORSPulsCntr "Transmission Output Rotational Status : Transmission Output Rotational Status Pulse Counter";
BA_ "PacketOrder" SG_ 199 TORSPulsCntr 5;
BA_ "SignalType" SG_ 199 TORSPulsCntr "UNM";
BA_ "VNSigAllNodes" SG_ 199 TORSPulsCntr 1;
BA_ "SignalLongName" SG_ 199 TORSValidity "Transmission Output Rotational Status : Transmission Output Rotational Status Validity";
BA_ "PacketOrder" SG_ 199 TORSValidity 4;
BA_ "SignalType" SG_ 199 TORSValidity "ENM";
BA_ "VNSigAllNodes" SG_ 199 TORSValidity 1;
BA_ "SignalLongName" SG_ 199 TORSRstOcrd "Transmission Output Rotational Status : Transmission Output Rotational Status Reset Occurred";
BA_ "PacketOrder" SG_ 199 TORSRstOcrd 3;
BA_ "SignalType" SG_ 199 TORSRstOcrd "BLN";
BA_ "VNSigAllNodes" SG_ 199 TORSRstOcrd 1;
BA_ "SignalLongName" SG_ 199 TORSLstTransType "Transmission Output Rotational Status : Transmission Output Rotational Status Last Transition Type";
BA_ "PacketOrder" SG_ 199 TORSLstTransType 2;
BA_ "SignalType" SG_ 199 TORSLstTransType "ENM";
BA_ "VNSigAllNodes" SG_ 199 TORSLstTransType 1;
BA_ "SignalLongName" SG_ 199 TORSRotDir "Transmission Output Rotational Status : Transmission Output Rotational Status Rotation Direction";
BA_ "PacketOrder" SG_ 199 TORSRotDir 1;
BA_ "SignalType" SG_ 199 TORSRotDir "ENM";
BA_ "VNSigAllNodes" SG_ 199 TORSRotDir 1;
BA_ "SignalLongName" SG_ 390 RdHVInvRatVltV "Redundant High Voltage Inverter Rationalized Voltage Validity";
BA_ "SignalType" SG_ 390 RdHVInvRatVltV "ENM";
BA_ "VNSigAllNodes" SG_ 390 RdHVInvRatVltV 1;
BA_ "SignalLongName" SG_ 390 RdHVInvRatVlt "Redundant High Voltage Inverter Rationalized Voltage";
BA_ "SignalType" SG_ 390 RdHVInvRatVlt "UNM";
BA_ "VNSigAllNodes" SG_ 390 RdHVInvRatVlt 1;
BA_ "SignalLongName" SG_ 390 RdPTHVCntrReq "Redundant Powertrain High Voltage Contactor Request";
BA_ "SignalType" SG_ 390 RdPTHVCntrReq "ENM";
BA_ "VNSigAllNodes" SG_ 390 RdPTHVCntrReq 1;
BA_ "SignalLongName" SG_ 390 TransFldPmpMtrDrtd "Transmission Fluid Pump Motor Derated";
BA_ "SignalType" SG_ 390 TransFldPmpMtrDrtd "BLN";
BA_ "VNSigAllNodes" SG_ 390 TransFldPmpMtrDrtd 1;
BA_ "SignalLongName" SG_ 390 EstMtrPwrLossV "Estimated Motor Power Loss Validity";
BA_ "SignalType" SG_ 390 EstMtrPwrLossV "ENM";
BA_ "VNSigAllNodes" SG_ 390 EstMtrPwrLossV 1;
BA_ "SignalLongName" SG_ 390 EstMtrPwrLoss "Estimated Motor Power Loss";
BA_ "SignalType" SG_ 390 EstMtrPwrLoss "UNM";
BA_ "VNSigAllNodes" SG_ 390 EstMtrPwrLoss 1;
BA_ "SignalLongName" SG_ 390 HybGrdBrkgAct "Hybrid Grade Braking Active";
BA_ "SignalType" SG_ 390 HybGrdBrkgAct "BLN";
BA_ "VNSigAllNodes" SG_ 390 HybGrdBrkgAct 1;
BA_ "SignalLongName" SG_ 390 HybCrpCstCrvRq "Hybrid Creep Coast Curve Request";
BA_ "SignalType" SG_ 390 HybCrpCstCrvRq "ENM";
BA_ "VNSigAllNodes" SG_ 390 HybCrpCstCrvRq 1;
BA_ "SignalLongName" SG_ 390 EngActDmpgDsblReq "Engine Active Damping Disable Requested";
BA_ "SignalType" SG_ 390 EngActDmpgDsblReq "BLN";
BA_ "VNSigAllNodes" SG_ 390 EngActDmpgDsblReq 1;
BA_ "SignalLongName" SG_ 390 HybRdcdTrqCapMd1Cmnd "Hybrid Reduced Torque Capacity Mode 1 Commanded";
BA_ "SignalType" SG_ 390 HybRdcdTrqCapMd1Cmnd "BLN";
BA_ "VNSigAllNodes" SG_ 390 HybRdcdTrqCapMd1Cmnd 1;
BA_ "SignalLongName" SG_ 390 HybExtndDcFuelCORq "Hybrid Extended Deceleration Fuel Cut Off Requested";
BA_ "SignalType" SG_ 390 HybExtndDcFuelCORq "BLN";
BA_ "VNSigAllNodes" SG_ 390 HybExtndDcFuelCORq 1;
BA_ "SignalLongName" SG_ 390 HybCmmFailRdPwrCmd "Hybrid Communication Failure Reduced Power Commanded";
BA_ "SignalType" SG_ 390 HybCmmFailRdPwrCmd "BLN";
BA_ "VNSigAllNodes" SG_ 390 HybCmmFailRdPwrCmd 1;
BA_ "SignalLongName" SG_ 390 HybCmmdEngTrqLmtd "Hybrid Commanded Engine Torque Limited";
BA_ "SignalType" SG_ 390 HybCmmdEngTrqLmtd "UNM";
BA_ "VNSigAllNodes" SG_ 390 HybCmmdEngTrqLmtd 1;
BA_ "SignalLongName" SG_ 390 HybACCompRq "Hybrid Air Conditioning Compressor Request";
BA_ "SignalType" SG_ 390 HybACCompRq "ENM";
BA_ "VNSigAllNodes" SG_ 390 HybACCompRq 1;
BA_ "SignalLongName" SG_ 390 HESSI_EngStrtTyp "Hybrid Engine Start Stop Information : Engine Start Type";
BA_ "PacketOrder" SG_ 390 HESSI_EngStrtTyp 2;
BA_ "SignalType" SG_ 390 HESSI_EngStrtTyp "ENM";
BA_ "VNSigAllNodes" SG_ 390 HESSI_EngStrtTyp 1;
BA_ "SignalLongName" SG_ 390 HESSI_EngStrtStpMd "Hybrid Engine Start Stop Information : Engine Start Stop Mode";
BA_ "PacketOrder" SG_ 390 HESSI_EngStrtStpMd 1;
BA_ "SignalType" SG_ 390 HESSI_EngStrtStpMd "ENM";
BA_ "VNSigAllNodes" SG_ 390 HESSI_EngStrtStpMd 1;
BA_ "SignalLongName" SG_ 390 HybCrnkAbrtd "Hybrid Crank Aborted";
BA_ "SignalType" SG_ 390 HybCrnkAbrtd "BLN";
BA_ "VNSigAllNodes" SG_ 390 HybCrnkAbrtd 1;
BA_ "SignalLongName" SG_ 390 CnvntlEngStrtEnbld "Conventional Engine Start Enabled";
BA_ "SignalType" SG_ 390 CnvntlEngStrtEnbld "BLN";
BA_ "VNSigAllNodes" SG_ 390 CnvntlEngStrtEnbld 1;
BA_ "SignalLongName" SG_ 390 HybDFCOReq "Hybrid Deceleration Fuel Cut Off Request";
BA_ "SignalType" SG_ 390 HybDFCOReq "ENM";
BA_ "VNSigAllNodes" SG_ 390 HybDFCOReq 1;
BA_ "SignalLongName" SG_ 460 SecAxlThrmlCapV "Secondary Axle Thermal Capacity Validity";
BA_ "SignalType" SG_ 460 SecAxlThrmlCapV "ENM";
BA_ "VNSigAllNodes" SG_ 460 SecAxlThrmlCapV 1;
BA_ "SignalLongName" SG_ 460 SecAxlThrmlCapPRqAt "Secondary Axle Thermal Capacity Protection Request Active";
BA_ "SignalType" SG_ 460 SecAxlThrmlCapPRqAt "BLN";
BA_ "VNSigAllNodes" SG_ 460 SecAxlThrmlCapPRqAt 1;
BA_ "SignalLongName" SG_ 460 SecAxlThrmlCap "Secondary Axle Thermal Capacity";
BA_ "SignalType" SG_ 460 SecAxlThrmlCap "UNM";
BA_ "VNSigAllNodes" SG_ 460 SecAxlThrmlCap 1;
BA_ "SignalLongName" SG_ 460 SAMDVLReqVal "Secondary Axle Maximum Differential Velocity Limit : Request Value";
BA_ "PacketOrder" SG_ 460 SAMDVLReqVal 2;
BA_ "SignalType" SG_ 460 SAMDVLReqVal "UNM";
BA_ "VNSigAllNodes" SG_ 460 SAMDVLReqVal 1;
BA_ "SignalLongName" SG_ 460 SAMDVLAtv "Secondary Axle Maximum Differential Velocity Limit : Active";
BA_ "PacketOrder" SG_ 460 SAMDVLAtv 1;
BA_ "SignalType" SG_ 460 SAMDVLAtv "BLN";
BA_ "VNSigAllNodes" SG_ 460 SAMDVLAtv 1;
BA_ "SignalLongName" SG_ 460 SecAxlCtrlMod "Secondary Axle Control Mode";
BA_ "SignalType" SG_ 460 SecAxlCtrlMod "ENM";
BA_ "VNSigAllNodes" SG_ 460 SecAxlCtrlMod 1;
BA_ "SignalLongName" SG_ 460 PndgTrnsfrCsRngShft "Pending Transfer Case Range Shift";
BA_ "SignalType" SG_ 460 PndgTrnsfrCsRngShft "ENM";
BA_ "VNSigAllNodes" SG_ 460 PndgTrnsfrCsRngShft 1;
BA_ "SignalLongName" SG_ 460 SecAxlEstTrqV "Secondary Axle Estimated Torque Validity";
BA_ "SignalType" SG_ 460 SecAxlEstTrqV "ENM";
BA_ "VNSigAllNodes" SG_ 460 SecAxlEstTrqV 1;
BA_ "SignalLongName" SG_ 460 SecAxlEstTrq "Secondary Axle Estimated Torque";
BA_ "SignalType" SG_ 460 SecAxlEstTrq "UNM";
BA_ "VNSigAllNodes" SG_ 460 SecAxlEstTrq 1;
BA_ "SignalLongName" SG_ 460 PTTrnsfrCseMd "Powertrain Transfer Case Mode";
BA_ "SignalType" SG_ 460 PTTrnsfrCseMd "ENM";
BA_ "VNSigAllNodes" SG_ 460 PTTrnsfrCseMd 1;
BA_ "SignalLongName" SG_ 460 SecAxlStat "Secondary Axle Status";
BA_ "SignalType" SG_ 460 SecAxlStat "ENM";
BA_ "VNSigAllNodes" SG_ 460 SecAxlStat 1;
BA_ "SignalLongName" SG_ 719 RrVrtlBmpAxlTrqCmdRC "Rear Virtual Bumper Axle Torque Command Rolling Count";
BA_ "SignalType" SG_ 719 RrVrtlBmpAxlTrqCmdRC "UNM";
BA_ "VNSigAllNodes" SG_ 719 RrVrtlBmpAxlTrqCmdRC 1;
BA_ "SignalLongName" SG_ 719 RrVrtlBmpAxlTrqCmdProtVal "Rear Virtual Bumper Axle Torque Command Protection Value";
BA_ "SignalType" SG_ 719 RrVrtlBmpAxlTrqCmdProtVal "UNM";
BA_ "VNSigAllNodes" SG_ 719 RrVrtlBmpAxlTrqCmdProtVal 1;
BA_ "SignalLongName" SG_ 719 RVBATC_AxlTrqRqstAct "Rear Virtual Bumper Axle Torque Command : Axle Torque Request Active";
BA_ "PacketOrder" SG_ 719 RVBATC_AxlTrqRqstAct 1;
BA_ "SignalType" SG_ 719 RVBATC_AxlTrqRqstAct "BLN";
BA_ "VNSigAllNodes" SG_ 719 RVBATC_AxlTrqRqstAct 1;
BA_ "GenSigStartValue" SG_ 719 RVBATC_AxlTrqRqst 32767;
BA_ "SignalLongName" SG_ 719 RVBATC_AxlTrqRqst "Rear Virtual Bumper Axle Torque Command : Axle Torque Request";
BA_ "PacketOrder" SG_ 719 RVBATC_AxlTrqRqst 2;
BA_ "SignalType" SG_ 719 RVBATC_AxlTrqRqst "UNM";
BA_ "VNSigAllNodes" SG_ 719 RVBATC_AxlTrqRqst 1;
BA_ "SignalLongName" SG_ 717 ColPrSysAxlTrqCmdProtVal "Collision Preparation System Axle Torque Command Protection Value";
BA_ "SignalType" SG_ 717 ColPrSysAxlTrqCmdProtVal "UNM";
BA_ "VNSigAllNodes" SG_ 717 ColPrSysAxlTrqCmdProtVal 1;
BA_ "SignalLongName" SG_ 717 CPSATC_AxlTrqRqstAct "Collision Preparation System Axle Torque Command : Axle Torque Request Active";
BA_ "PacketOrder" SG_ 717 CPSATC_AxlTrqRqstAct 1;
BA_ "SignalType" SG_ 717 CPSATC_AxlTrqRqstAct "BLN";
BA_ "VNSigAllNodes" SG_ 717 CPSATC_AxlTrqRqstAct 1;
BA_ "GenSigStartValue" SG_ 717 CPSATC_AxlTrqRqst 32767;
BA_ "SignalLongName" SG_ 717 CPSATC_AxlTrqRqst "Collision Preparation System Axle Torque Command : Axle Torque Request";
BA_ "PacketOrder" SG_ 717 CPSATC_AxlTrqRqst 2;
BA_ "SignalType" SG_ 717 CPSATC_AxlTrqRqst "UNM";
BA_ "VNSigAllNodes" SG_ 717 CPSATC_AxlTrqRqst 1;
BA_ "SignalLongName" SG_ 717 ColPrSysAxlTrqCmdRC "Collision Preparation System Axle Torque Command Rolling Count";
BA_ "SignalType" SG_ 717 ColPrSysAxlTrqCmdRC "UNM";
BA_ "VNSigAllNodes" SG_ 717 ColPrSysAxlTrqCmdRC 1;
BA_ "SignalLongName" SG_ 1105 HybImpSnsDsbld "Hybrid Impact Sensing Disabled";
BA_ "SignalType" SG_ 1105 HybImpSnsDsbld "BLN";
BA_ "VNSigAllNodes" SG_ 1105 HybImpSnsDsbld 1;
BA_ "GenSigSendType" SG_ 1105 HybImpSnsDsbld 10;
BA_ "SignalLongName" SG_ 1105 JmpStrtReq "Jump Start Requested";
BA_ "SignalType" SG_ 1105 JmpStrtReq "BLN";
BA_ "VNSigAllNodes" SG_ 1105 JmpStrtReq 1;
BA_ "GenSigSendType" SG_ 1105 JmpStrtReq 10;
BA_ "GenSigSendOnInit" SG_ 1105 JmpStrtReq 1;
BA_ "SignalLongName" SG_ 1105 HybVehHiVltInvDisRqd "Hybrid Vehicle High Voltage Inverter Disable Requested";
BA_ "SignalType" SG_ 1105 HybVehHiVltInvDisRqd "BLN";
BA_ "VNSigAllNodes" SG_ 1105 HybVehHiVltInvDisRqd 1;
BA_ "GenSigSendType" SG_ 1105 HybVehHiVltInvDisRqd 10;
BA_ "SignalLongName" SG_ 1105 ClmCntFrBlwFnSp "Climate Control Front Blower Fan Speed";
BA_ "SignalType" SG_ 1105 ClmCntFrBlwFnSp "UNM";
BA_ "VNSigAllNodes" SG_ 1105 ClmCntFrBlwFnSp 1;
BA_ "GenSigDeltaValue" SG_ 1105 ClmCntFrBlwFnSp 13;
BA_ "GenSigSendType" SG_ 1105 ClmCntFrBlwFnSp 12;
BA_ "GenSigSendOnInit" SG_ 1105 ClmCntFrBlwFnSp 2;
BA_ "SignalLongName" SG_ 1105 NESSRoSevSt "Notification Event Severity Status : Rollover Severity Achieved";
BA_ "PacketOrder" SG_ 1105 NESSRoSevSt 7;
BA_ "SignalType" SG_ 1105 NESSRoSevSt "BLN";
BA_ "VNSigAllNodes" SG_ 1105 NESSRoSevSt 1;
BA_ "GenSigSendType" SG_ 1105 NESSRoSevSt 10;
BA_ "SignalLongName" SG_ 1105 NESSRiSiSevSt "Notification Event Severity Status : Right Side Severity Achieved";
BA_ "PacketOrder" SG_ 1105 NESSRiSiSevSt 6;
BA_ "SignalType" SG_ 1105 NESSRiSiSevSt "BLN";
BA_ "VNSigAllNodes" SG_ 1105 NESSRiSiSevSt 1;
BA_ "GenSigSendType" SG_ 1105 NESSRiSiSevSt 10;
BA_ "SignalLongName" SG_ 1105 NESSReImpSevSt "Notification Event Severity Status : Rear Impact Severity Achieved";
BA_ "PacketOrder" SG_ 1105 NESSReImpSevSt 5;
BA_ "SignalType" SG_ 1105 NESSReImpSevSt "BLN";
BA_ "VNSigAllNodes" SG_ 1105 NESSReImpSevSt 1;
BA_ "GenSigSendType" SG_ 1105 NESSReImpSevSt 10;
BA_ "SignalLongName" SG_ 1105 NESSLeSiSevSt "Notification Event Severity Status : Left Side Severity Achieved";
BA_ "PacketOrder" SG_ 1105 NESSLeSiSevSt 4;
BA_ "SignalType" SG_ 1105 NESSLeSiSevSt "BLN";
BA_ "VNSigAllNodes" SG_ 1105 NESSLeSiSevSt 1;
BA_ "GenSigSendType" SG_ 1105 NESSLeSiSevSt 10;
BA_ "SignalLongName" SG_ 1105 NESSFrImpSt2SevSt "Notification Event Severity Status : Frontal Impact Stage 2 Severity Achieved";
BA_ "PacketOrder" SG_ 1105 NESSFrImpSt2SevSt 3;
BA_ "SignalType" SG_ 1105 NESSFrImpSt2SevSt "BLN";
BA_ "VNSigAllNodes" SG_ 1105 NESSFrImpSt2SevSt 1;
BA_ "GenSigSendType" SG_ 1105 NESSFrImpSt2SevSt 10;
BA_ "SignalLongName" SG_ 1105 NESSFrImpSt1SevSt "Notification Event Severity Status : Frontal Impact Stage 1 Severity Achieved";
BA_ "PacketOrder" SG_ 1105 NESSFrImpSt1SevSt 2;
BA_ "SignalType" SG_ 1105 NESSFrImpSt1SevSt "BLN";
BA_ "VNSigAllNodes" SG_ 1105 NESSFrImpSt1SevSt 1;
BA_ "GenSigSendType" SG_ 1105 NESSFrImpSt1SevSt 10;
BA_ "SignalLongName" SG_ 1105 NESSFrImpPreSevSt "Notification Event Severity Status : Frontal Impact Pretensioner Severity Achieved";
BA_ "PacketOrder" SG_ 1105 NESSFrImpPreSevSt 1;
BA_ "SignalType" SG_ 1105 NESSFrImpPreSevSt "BLN";
BA_ "VNSigAllNodes" SG_ 1105 NESSFrImpPreSevSt 1;
BA_ "GenSigSendType" SG_ 1105 NESSFrImpPreSevSt 10;
BA_ "SignalLongName" SG_ 1005 EnhSvVehTopSpdLmR "Enhanced Services Vehicle Top Speed Limit Request";
BA_ "SignalType" SG_ 1005 EnhSvVehTopSpdLmR "ENM";
BA_ "VNSigAllNodes" SG_ 1005 EnhSvVehTopSpdLmR 1;
BA_ "SignalLongName" SG_ 1005 EnhSvVTpSpdLVlARC "Enhanced Services Vehicle Top Speed Limit Value Alive Rolling Count";
BA_ "SignalType" SG_ 1005 EnhSvVTpSpdLVlARC "UNM";
BA_ "VNSigAllNodes" SG_ 1005 EnhSvVTpSpdLVlARC 1;
BA_ "SignalLongName" SG_ 1005 EnhSvVehTopSpdLimP "Enhanced Services Vehicle Top Speed Limit Password";
BA_ "SignalType" SG_ 1005 EnhSvVehTopSpdLimP "UNM";
BA_ "VNSigAllNodes" SG_ 1005 EnhSvVehTopSpdLimP 1;
BA_ "GenSigStartValue" SG_ 1005 EnhSvVehTopSpdLim 255;
BA_ "SignalLongName" SG_ 1005 EnhSvVehTopSpdLim "Enhanced Services Vehicle Top Speed Limit Value";
BA_ "SignalType" SG_ 1005 EnhSvVehTopSpdLim "UNM";
BA_ "VNSigAllNodes" SG_ 1005 EnhSvVehTopSpdLim 1;
BA_ "GenSigDeltaValue" SG_ 1005 EnhSvVehTopSpdLim 1;
BA_ "GenSigSendType" SG_ 1005 EnhSvVehTopSpdLim 12;
BA_ "SignalLongName" SG_ 688 StrtrGenSpdV "Starter Generator Speed  Validity";
BA_ "SignalType" SG_ 688 StrtrGenSpdV "ENM";
BA_ "VNSigAllNodes" SG_ 688 StrtrGenSpdV 1;
BA_ "SignalLongName" SG_ 688 StrtrGenSpd "Starter Generator Speed";
BA_ "SignalType" SG_ 688 StrtrGenSpd "UNM";
BA_ "VNSigAllNodes" SG_ 688 StrtrGenSpd 1;
BA_ "SignalLongName" SG_ 431 TrnsInpCltchStatV "Transmission Input Clutch Status Validity";
BA_ "SignalType" SG_ 431 TrnsInpCltchStatV "ENM";
BA_ "VNSigAllNodes" SG_ 431 TrnsInpCltchStatV 1;
BA_ "SignalLongName" SG_ 431 TransCrnkPermsnStatV "Transmission Crank Permission Status Validity";
BA_ "SignalType" SG_ 431 TransCrnkPermsnStatV "ENM";
BA_ "VNSigAllNodes" SG_ 431 TransCrnkPermsnStatV 1;
BA_ "GenSigStartValue" SG_ 431 TransVehTopSpdLim 255;
BA_ "SignalLongName" SG_ 431 TransVehTopSpdLim "Transmission Vehicle Top Speed Limit Value";
BA_ "SignalType" SG_ 431 TransVehTopSpdLim "UNM";
BA_ "VNSigAllNodes" SG_ 431 TransVehTopSpdLim 1;
BA_ "SignalLongName" SG_ 431 TransMinVoltReq "Transmission Minimum Voltage Request";
BA_ "SignalType" SG_ 431 TransMinVoltReq "UNM";
BA_ "VNSigAllNodes" SG_ 431 TransMinVoltReq 1;
BA_ "SignalLongName" SG_ 431 TDslPrtFltrIdlRgtnMdAtv "Transmission Diesel Particulate Filter Idle Regeneration Mode Active";
BA_ "SignalType" SG_ 431 TDslPrtFltrIdlRgtnMdAtv "BLN";
BA_ "VNSigAllNodes" SG_ 431 TDslPrtFltrIdlRgtnMdAtv 1;
BA_ "SignalLongName" SG_ 431 DrvlneTrqStabStat "Driveline Torque Stability Status";
BA_ "SignalType" SG_ 431 DrvlneTrqStabStat "ENM";
BA_ "VNSigAllNodes" SG_ 431 DrvlneTrqStabStat 1;
BA_ "SignalLongName" SG_ 431 TrnsTrqCnvCltCmdMdF "Transmission Torque Converter Clutch Commanded Mode Failure";
BA_ "SignalType" SG_ 431 TrnsTrqCnvCltCmdMdF "BLN";
BA_ "VNSigAllNodes" SG_ 431 TrnsTrqCnvCltCmdMdF 1;
BA_ "SignalLongName" SG_ 431 AutoTransGrSftDirectFl "Automatic Transmission Gear Shift Direction Failure";
BA_ "SignalType" SG_ 431 AutoTransGrSftDirectFl "BLN";
BA_ "VNSigAllNodes" SG_ 431 AutoTransGrSftDirectFl 1;
BA_ "SignalLongName" SG_ 431 AutoTransGrSftDirect "Automatic Transmission Gear Shift Direction";
BA_ "SignalType" SG_ 431 AutoTransGrSftDirect "ENM";
BA_ "VNSigAllNodes" SG_ 431 AutoTransGrSftDirect 1;
BA_ "GenSigStartValue" SG_ 431 TrnsTrqCnvCltCmndMd 7;
BA_ "SignalLongName" SG_ 431 TrnsTrqCnvCltCmndMd "Transmission Torque Converter Clutch Commanded Mode";
BA_ "SignalType" SG_ 431 TrnsTrqCnvCltCmndMd "ENM";
BA_ "VNSigAllNodes" SG_ 431 TrnsTrqCnvCltCmndMd 1;
BA_ "SignalLongName" SG_ 431 TrnsTrqCnvCltDsrSlp "Transmission Torque Converter Clutch Desired Slip";
BA_ "SignalType" SG_ 431 TrnsTrqCnvCltDsrSlp "SNM";
BA_ "VNSigAllNodes" SG_ 431 TrnsTrqCnvCltDsrSlp 1;
BA_ "SignalLongName" SG_ 431 TrnsStWntrMdOvrd "Transmission State Winter Mode Override";
BA_ "SignalType" SG_ 431 TrnsStWntrMdOvrd "ENM";
BA_ "VNSigAllNodes" SG_ 431 TrnsStWntrMdOvrd 1;
BA_ "SignalLongName" SG_ 431 TrnsStTwHaulMdOvrd "Transmission State Tow Haul Mode Override";
BA_ "SignalType" SG_ 431 TrnsStTwHaulMdOvrd "ENM";
BA_ "VNSigAllNodes" SG_ 431 TrnsStTwHaulMdOvrd 1;
BA_ "SignalLongName" SG_ 431 TrnsStSprtMdOvrd "Transmission State Sport Mode Override";
BA_ "SignalType" SG_ 431 TrnsStSprtMdOvrd "ENM";
BA_ "VNSigAllNodes" SG_ 431 TrnsStSprtMdOvrd 1;
BA_ "SignalLongName" SG_ 431 TrnsStEconMdOvrd "Transmission State Economy Mode Override";
BA_ "SignalType" SG_ 431 TrnsStEconMdOvrd "ENM";
BA_ "VNSigAllNodes" SG_ 431 TrnsStEconMdOvrd 1;
BA_ "SignalLongName" SG_ 431 TrnsInpCltchStat "Transmission Input Clutch Status";
BA_ "SignalType" SG_ 431 TrnsInpCltchStat "ENM";
BA_ "VNSigAllNodes" SG_ 431 TrnsInpCltchStat 1;
BA_ "SignalLongName" SG_ 431 TrnsAntcptdCrpTrqRRnV "Transmission Anticipated Creep Torque Reduced Range Validity";
BA_ "SignalType" SG_ 431 TrnsAntcptdCrpTrqRRnV "ENM";
BA_ "VNSigAllNodes" SG_ 431 TrnsAntcptdCrpTrqRRnV 1;
BA_ "SignalLongName" SG_ 431 TrnsAntcptdCrpTrqRRn "Transmission Anticipated Creep Torque Reduced Range";
BA_ "SignalType" SG_ 431 TrnsAntcptdCrpTrqRRn "UNM";
BA_ "VNSigAllNodes" SG_ 431 TrnsAntcptdCrpTrqRRn 1;
BA_ "SignalLongName" SG_ 431 TrnCltAdpAtv "Transmission Clutch Adaptation Active";
BA_ "SignalType" SG_ 431 TrnCltAdpAtv "BLN";
BA_ "VNSigAllNodes" SG_ 431 TrnCltAdpAtv 1;
BA_ "SignalLongName" SG_ 431 TransCrnkPermsnStat "Transmission Crank Permission Status";
BA_ "SignalType" SG_ 431 TransCrnkPermsnStat "ENM";
BA_ "VNSigAllNodes" SG_ 431 TransCrnkPermsnStat 1;
BA_ "SignalLongName" SG_ 431 WrmUpShftPtrn "Warm Up Shift Pattern Status";
BA_ "SignalType" SG_ 431 WrmUpShftPtrn "ENM";
BA_ "VNSigAllNodes" SG_ 431 WrmUpShftPtrn 1;
BA_ "SignalLongName" SG_ 715 ACCATC_SplREngInpR "Adaptive Cruise Control Axle Torque Command : Special Re-engagement Input Required";
BA_ "PacketOrder" SG_ 715 ACCATC_SplREngInpR 4;
BA_ "SignalType" SG_ 715 ACCATC_SplREngInpR "BLN";
BA_ "VNSigAllNodes" SG_ 715 ACCATC_SplREngInpR 1;
BA_ "SignalLongName" SG_ 715 ACCATC_DrvAstdGoSt "Adaptive Cruise Control Axle Torque Command : Driver Assisted Go State";
BA_ "PacketOrder" SG_ 715 ACCATC_DrvAstdGoSt 3;
BA_ "SignalType" SG_ 715 ACCATC_DrvAstdGoSt "ENM";
BA_ "VNSigAllNodes" SG_ 715 ACCATC_DrvAstdGoSt 1;
BA_ "SignalLongName" SG_ 715 ACCATC_AxlTrqRq "Adaptive Cruise Control Axle Torque Command : Axle Torque Request";
BA_ "PacketOrder" SG_ 715 ACCATC_AxlTrqRq 5;
BA_ "SignalType" SG_ 715 ACCATC_AxlTrqRq "UNM";
BA_ "VNSigAllNodes" SG_ 715 ACCATC_AxlTrqRq 1;
BA_ "SignalLongName" SG_ 715 ACCATC_ACCTyp "Adaptive Cruise Control Axle Torque Command : Adaptive Cruise Control Type";
BA_ "PacketOrder" SG_ 715 ACCATC_ACCTyp 2;
BA_ "SignalType" SG_ 715 ACCATC_ACCTyp "ENM";
BA_ "VNSigAllNodes" SG_ 715 ACCATC_ACCTyp 1;
BA_ "SignalLongName" SG_ 715 ACCATC_ACCAct "Adaptive Cruise Control Axle Torque Command : Adaptive Cruise Control Active";
BA_ "PacketOrder" SG_ 715 ACCATC_ACCAct 1;
BA_ "SignalType" SG_ 715 ACCATC_ACCAct "BLN";
BA_ "VNSigAllNodes" SG_ 715 ACCATC_ACCAct 1;
BA_ "SignalLongName" SG_ 715 ACCAxlTrqCmdProt "Adaptive Cruise Control Axle torque Command Protection";
BA_ "SignalType" SG_ 715 ACCAxlTrqCmdProt "UNM";
BA_ "VNSigAllNodes" SG_ 715 ACCAxlTrqCmdProt 1;
BA_ "SignalLongName" SG_ 715 ACCCmndAlvRlgCnt "Adaptive Cruise Control Command Alive Rolling Count";
BA_ "SignalType" SG_ 715 ACCCmndAlvRlgCnt "UNM";
BA_ "VNSigAllNodes" SG_ 715 ACCCmndAlvRlgCnt 1;
BA_ "SignalLongName" SG_ 320 Ky_IdDevPrgmAuthReq "Key / Identification Device Programming Authentication Requested";
BA_ "SignalType" SG_ 320 Ky_IdDevPrgmAuthReq "BLN";
BA_ "VNSigAllNodes" SG_ 320 Ky_IdDevPrgmAuthReq 1;
BA_ "GenSigSendType" SG_ 320 Ky_IdDevPrgmAuthReq 10;
BA_ "SignalLongName" SG_ 320 ClmnLckStatV "Column Lock Status Validity";
BA_ "SignalType" SG_ 320 ClmnLckStatV "ENM";
BA_ "VNSigAllNodes" SG_ 320 ClmnLckStatV 1;
BA_ "GenSigSendType" SG_ 320 ClmnLckStatV 10;
BA_ "SignalLongName" SG_ 320 ClmnLckStat "Column Lock Status";
BA_ "SignalType" SG_ 320 ClmnLckStat "ENM";
BA_ "VNSigAllNodes" SG_ 320 ClmnLckStat 1;
BA_ "GenSigSendType" SG_ 320 ClmnLckStat 10;
BA_ "GenSigSendOnInit" SG_ 320 ClmnLckStat 2;
BA_ "SignalLongName" SG_ 320 AutoBmSlctAllwd "Automatic Beam Select Allowed";
BA_ "SignalType" SG_ 320 AutoBmSlctAllwd "BLN";
BA_ "VNSigAllNodes" SG_ 320 AutoBmSlctAllwd 1;
BA_ "GenSigSendType" SG_ 320 AutoBmSlctAllwd 10;
BA_ "GenSigSendOnInit" SG_ 320 AutoBmSlctAllwd 2;
BA_ "SignalLongName" SG_ 320 BrkLtsAtv "Brake Lights Active";
BA_ "SignalType" SG_ 320 BrkLtsAtv "BLN";
BA_ "VNSigAllNodes" SG_ 320 BrkLtsAtv 1;
BA_ "GenSigSendType" SG_ 320 BrkLtsAtv 10;
BA_ "GenSigSendOnInit" SG_ 320 BrkLtsAtv 1;
BA_ "SignalLongName" SG_ 320 RrFogLmpsAct "Rear Fog Lamps Active";
BA_ "SignalType" SG_ 320 RrFogLmpsAct "BLN";
BA_ "VNSigAllNodes" SG_ 320 RrFogLmpsAct 1;
BA_ "GenSigSendType" SG_ 320 RrFogLmpsAct 10;
BA_ "GenSigSendOnInit" SG_ 320 RrFogLmpsAct 1;
BA_ "SignalLongName" SG_ 320 OtsdAmbtLtLvlStatV "Outside Ambient Light Level Status Validity";
BA_ "SignalType" SG_ 320 OtsdAmbtLtLvlStatV "ENM";
BA_ "VNSigAllNodes" SG_ 320 OtsdAmbtLtLvlStatV 1;
BA_ "GenSigSendType" SG_ 320 OtsdAmbtLtLvlStatV 10;
BA_ "SignalLongName" SG_ 320 OtsdAmbtLtLvlStat "Outside Ambient Light Level Status";
BA_ "SignalType" SG_ 320 OtsdAmbtLtLvlStat "ENM";
BA_ "VNSigAllNodes" SG_ 320 OtsdAmbtLtLvlStat 1;
BA_ "GenSigSendType" SG_ 320 OtsdAmbtLtLvlStat 10;
BA_ "SignalLongName" SG_ 320 MainLghtSw "Main Light Switch";
BA_ "SignalType" SG_ 320 MainLghtSw "ENM";
BA_ "VNSigAllNodes" SG_ 320 MainLghtSw 1;
BA_ "GenSigSendType" SG_ 320 MainLghtSw 10;
BA_ "GenSigSendOnInit" SG_ 320 MainLghtSw 1;
BA_ "SignalLongName" SG_ 320 LowBmAct "Low Beam Active";
BA_ "SignalType" SG_ 320 LowBmAct "BLN";
BA_ "VNSigAllNodes" SG_ 320 LowBmAct 1;
BA_ "GenSigSendType" SG_ 320 LowBmAct 10;
BA_ "SignalLongName" SG_ 320 HighBmAct "High Beam Active";
BA_ "SignalType" SG_ 320 HighBmAct "BLN";
BA_ "VNSigAllNodes" SG_ 320 HighBmAct 1;
BA_ "GenSigSendType" SG_ 320 HighBmAct 10;
BA_ "SignalLongName" SG_ 320 HdlmpBmSelectStat "Headlamp Beam Select Status";
BA_ "SignalType" SG_ 320 HdlmpBmSelectStat "ENM";
BA_ "VNSigAllNodes" SG_ 320 HdlmpBmSelectStat 1;
BA_ "GenSigSendType" SG_ 320 HdlmpBmSelectStat 10;
BA_ "GenSigSendOnInit" SG_ 320 HdlmpBmSelectStat 1;
BA_ "SignalLongName" SG_ 320 FlToPsSwAtv "Flash To Pass Switch Active";
BA_ "SignalType" SG_ 320 FlToPsSwAtv "BLN";
BA_ "VNSigAllNodes" SG_ 320 FlToPsSwAtv 1;
BA_ "GenSigSendType" SG_ 320 FlToPsSwAtv 10;
BA_ "SignalLongName" SG_ 320 AdvFrntLghtSysEnbld "Advanced Front Lighting System Enabled";
BA_ "SignalType" SG_ 320 AdvFrntLghtSysEnbld "BLN";
BA_ "VNSigAllNodes" SG_ 320 AdvFrntLghtSysEnbld 1;
BA_ "GenSigSendType" SG_ 320 AdvFrntLghtSysEnbld 10;
BA_ "SignalLongName" SG_ 320 FrFogLmpsAct "Front Fog Lamps Active";
BA_ "SignalType" SG_ 320 FrFogLmpsAct "BLN";
BA_ "VNSigAllNodes" SG_ 320 FrFogLmpsAct 1;
BA_ "GenSigSendType" SG_ 320 FrFogLmpsAct 10;
BA_ "SignalLongName" SG_ 320 AutLghtCtrl "Auto Light Control";
BA_ "SignalType" SG_ 320 AutLghtCtrl "BLN";
BA_ "VNSigAllNodes" SG_ 320 AutLghtCtrl 1;
BA_ "GenSigSendType" SG_ 320 AutLghtCtrl 10;
BA_ "SignalLongName" SG_ 320 TrnSwAct "Turn Switch Activation";
BA_ "SignalType" SG_ 320 TrnSwAct "ENM";
BA_ "VNSigAllNodes" SG_ 320 TrnSwAct 1;
BA_ "GenSigSendType" SG_ 320 TrnSwAct 10;
BA_ "GenSigSendOnInit" SG_ 320 TrnSwAct 1;
BA_ "SignalLongName" SG_ 499 OvrdrvDsblReqd "Overdrive Disable Requested";
BA_ "SignalType" SG_ 499 OvrdrvDsblReqd "BLN";
BA_ "VNSigAllNodes" SG_ 499 OvrdrvDsblReqd 1;
BA_ "SignalLongName" SG_ 499 PTShftPtrnOvrdAct "Powertrain Shift Pattern Override Active";
BA_ "SignalType" SG_ 499 PTShftPtrnOvrdAct "BLN";
BA_ "VNSigAllNodes" SG_ 499 PTShftPtrnOvrdAct 1;
BA_ "SignalLongName" SG_ 499 PFTrnsTUDSecSwSt "Platform Transmission Tap Up/Down Secondary Switch State";
BA_ "SignalType" SG_ 499 PFTrnsTUDSecSwSt "ENM";
BA_ "VNSigAllNodes" SG_ 499 PFTrnsTUDSecSwSt 1;
BA_ "SignalLongName" SG_ 499 PFTrnsTUDSwStAlvRC "Platform Transmission Tap Up/Down Switch Status Alive Rolling Count";
BA_ "SignalType" SG_ 499 PFTrnsTUDSwStAlvRC "UNM";
BA_ "VNSigAllNodes" SG_ 499 PFTrnsTUDSwStAlvRC 1;
BA_ "SignalLongName" SG_ 499 PFTrnsTUDSwSt "Platform Transmission Tap Up/Down Switch State";
BA_ "SignalType" SG_ 499 PFTrnsTUDSwSt "ENM";
BA_ "VNSigAllNodes" SG_ 499 PFTrnsTUDSwSt 1;
BA_ "SignalLongName" SG_ 499 PFTrnsTUDEnSwSt "Platform Transmission Tap Up/Down Enable Switch State";
BA_ "SignalType" SG_ 499 PFTrnsTUDEnSwSt "ENM";
BA_ "VNSigAllNodes" SG_ 499 PFTrnsTUDEnSwSt 1;
BA_ "SignalLongName" SG_ 499 TrnsPFShftPattSwARC "Transmission Platform Shift Pattern Switch Alive Rolling Count";
BA_ "SignalType" SG_ 499 TrnsPFShftPattSwARC "UNM";
BA_ "VNSigAllNodes" SG_ 499 TrnsPFShftPattSwARC 1;
BA_ "SignalLongName" SG_ 499 TrnsPFShftPattSw4Act "Transmission Platform Shift Pattern Switch 4 Active";
BA_ "SignalType" SG_ 499 TrnsPFShftPattSw4Act "BLN";
BA_ "VNSigAllNodes" SG_ 499 TrnsPFShftPattSw4Act 1;
BA_ "SignalLongName" SG_ 499 TrnsPFShftPattSw3Act "Transmission Platform Shift Pattern Switch 3 Active";
BA_ "SignalType" SG_ 499 TrnsPFShftPattSw3Act "BLN";
BA_ "VNSigAllNodes" SG_ 499 TrnsPFShftPattSw3Act 1;
BA_ "SignalLongName" SG_ 499 TrnsPFShftPattSw2Act "Transmission Platform Shift Pattern Switch 2 Active";
BA_ "SignalType" SG_ 499 TrnsPFShftPattSw2Act "BLN";
BA_ "VNSigAllNodes" SG_ 499 TrnsPFShftPattSw2Act 1;
BA_ "SignalLongName" SG_ 499 TrnsPFShftPattSw1Act "Transmission Platform Shift Pattern Switch 1 Active";
BA_ "SignalType" SG_ 499 TrnsPFShftPattSw1Act "BLN";
BA_ "VNSigAllNodes" SG_ 499 TrnsPFShftPattSw1Act 1;
BA_ "SignalLongName" SG_ 880 FOAI_VehAhdIndRq "Forward Object Alert Indications : Vehicle Ahead Indication Request";
BA_ "PacketOrder" SG_ 880 FOAI_VehAhdIndRq 2;
BA_ "SignalType" SG_ 880 FOAI_VehAhdIndRq "ENM";
BA_ "VNSigAllNodes" SG_ 880 FOAI_VehAhdIndRq 1;
BA_ "SignalLongName" SG_ 880 FOAI_AlrtWrnIndRq "Forward Object Alert Indications : Alert Warning Indication Request";
BA_ "PacketOrder" SG_ 880 FOAI_AlrtWrnIndRq 3;
BA_ "SignalType" SG_ 880 FOAI_AlrtWrnIndRq "ENM";
BA_ "VNSigAllNodes" SG_ 880 FOAI_AlrtWrnIndRq 1;
BA_ "SignalLongName" SG_ 880 FOAI_AlrtChmIhbRq "Forward Object Alert Indications : Alert Warning Chime Inhibit Request";
BA_ "PacketOrder" SG_ 880 FOAI_AlrtChmIhbRq 1;
BA_ "SignalType" SG_ 880 FOAI_AlrtChmIhbRq "ENM";
BA_ "VNSigAllNodes" SG_ 880 FOAI_AlrtChmIhbRq 1;
BA_ "SignalLongName" SG_ 880 FwdClnAlrtPr "Forward Collision Alert Present";
BA_ "SignalType" SG_ 880 FwdClnAlrtPr "BLN";
BA_ "VNSigAllNodes" SG_ 880 FwdClnAlrtPr 1;
BA_ "SignalLongName" SG_ 880 ACCUnavlbleDTWthrIO "Adaptive Cruise Unavailable Due To Weather Indication On";
BA_ "SignalType" SG_ 880 ACCUnavlbleDTWthrIO "BLN";
BA_ "VNSigAllNodes" SG_ 880 ACCUnavlbleDTWthrIO 1;
BA_ "SignalLongName" SG_ 880 DrvThrtlOvrdIO "Driver Throttle Override Indication On";
BA_ "SignalType" SG_ 880 DrvThrtlOvrdIO "BLN";
BA_ "VNSigAllNodes" SG_ 880 DrvThrtlOvrdIO 1;
BA_ "SignalLongName" SG_ 880 ServAdpCrsCtrlIndOn "Service Adaptive Cruise Control Indication On";
BA_ "SignalType" SG_ 880 ServAdpCrsCtrlIndOn "BLN";
BA_ "VNSigAllNodes" SG_ 880 ServAdpCrsCtrlIndOn 1;
BA_ "SignalLongName" SG_ 880 ACCHdwayStngIO "Adaptive Cruise Control Headway Setting Indication On";
BA_ "SignalType" SG_ 880 ACCHdwayStngIO "BLN";
BA_ "VNSigAllNodes" SG_ 880 ACCHdwayStngIO 1;
BA_ "SignalLongName" SG_ 880 ACCHdwyStg "Adaptive Cruise Control Headway Setting";
BA_ "SignalType" SG_ 880 ACCHdwyStg "ENM";
BA_ "VNSigAllNodes" SG_ 880 ACCHdwyStg 1;
BA_ "SignalLongName" SG_ 880 ACCSnsClnRqdIO "Adaptive Cruise Control Sensor Cleaning Required Indication On";
BA_ "SignalType" SG_ 880 ACCSnsClnRqdIO "BLN";
BA_ "VNSigAllNodes" SG_ 880 ACCSnsClnRqdIO 1;
BA_ "SignalLongName" SG_ 880 ACCTmpUnavlbleIO "Adaptive Cruise Control Temporarily Unavailable Indication On";
BA_ "SignalType" SG_ 880 ACCTmpUnavlbleIO "BLN";
BA_ "VNSigAllNodes" SG_ 880 ACCTmpUnavlbleIO 1;
BA_ "SignalLongName" SG_ 880 ACCDrvrSeltdSpdIO "Adaptive Cruise Control Driver Selected Speed Indication On";
BA_ "SignalType" SG_ 880 ACCDrvrSeltdSpdIO "BLN";
BA_ "VNSigAllNodes" SG_ 880 ACCDrvrSeltdSpdIO 1;
BA_ "SignalLongName" SG_ 880 ACCAct370 "Adaptive Cruise Control Active";
BA_ "SignalType" SG_ 880 ACCAct370 "BLN";
BA_ "VNSigAllNodes" SG_ 880 ACCAct370 1;
BA_ "SignalLongName" SG_ 880 ACCDrvrSeltdSpd "Adaptive Cruise Control Driver Selected Speed";
BA_ "SignalType" SG_ 880 ACCDrvrSeltdSpd "UNM";
BA_ "VNSigAllNodes" SG_ 880 ACCDrvrSeltdSpd 1;
BA_ "SignalLongName" SG_ 298 ChmAct "Chime Active";
BA_ "SignalType" SG_ 298 ChmAct "BLN";
BA_ "VNSigAllNodes" SG_ 298 ChmAct 1;
BA_ "GenSigSendType" SG_ 298 ChmAct 10;
BA_ "GenSigSendOnInit" SG_ 298 ChmAct 1;
BA_ "SignalLongName" SG_ 298 Ky_IdDevPr "Key / Identification Device Present";
BA_ "SignalType" SG_ 298 Ky_IdDevPr "BLN";
BA_ "VNSigAllNodes" SG_ 298 Ky_IdDevPr 1;
BA_ "GenSigSendType" SG_ 298 Ky_IdDevPr 10;
BA_ "GenSigSendOnInit" SG_ 298 Ky_IdDevPr 1;
BA_ "SignalLongName" SG_ 298 CrshAlrtDrvrSlctdType "Crash Alert Driver Selected Type";
BA_ "SignalType" SG_ 298 CrshAlrtDrvrSlctdType "ENM";
BA_ "VNSigAllNodes" SG_ 298 CrshAlrtDrvrSlctdType 1;
BA_ "GenSigSendType" SG_ 298 CrshAlrtDrvrSlctdType 10;
BA_ "GenSigSendOnInit" SG_ 298 CrshAlrtDrvrSlctdType 1;
BA_ "SignalLongName" SG_ 298 PsSbltAtcV "Passenger Seatbelt Attached Validity";
BA_ "SignalType" SG_ 298 PsSbltAtcV "ENM";
BA_ "VNSigAllNodes" SG_ 298 PsSbltAtcV 1;
BA_ "GenSigSendType" SG_ 298 PsSbltAtcV 10;
BA_ "GenSigSendOnInit" SG_ 298 PsSbltAtcV 2;
BA_ "SignalLongName" SG_ 298 PsSbltAtc "Passenger Seatbelt Attached";
BA_ "SignalType" SG_ 298 PsSbltAtc "BLN";
BA_ "VNSigAllNodes" SG_ 298 PsSbltAtc 1;
BA_ "GenSigSendType" SG_ 298 PsSbltAtc 10;
BA_ "GenSigSendOnInit" SG_ 298 PsSbltAtc 2;
BA_ "SignalLongName" SG_ 298 TrlrBrkDsplyAct "Trailer Brake Display Active";
BA_ "SignalType" SG_ 298 TrlrBrkDsplyAct "BLN";
BA_ "VNSigAllNodes" SG_ 298 TrlrBrkDsplyAct 1;
BA_ "GenSigSendType" SG_ 298 TrlrBrkDsplyAct 10;
BA_ "GenSigSendOnInit" SG_ 298 TrlrBrkDsplyAct 1;
BA_ "SignalLongName" SG_ 298 RdSpdCatType "Road Speed Category Type";
BA_ "SignalType" SG_ 298 RdSpdCatType "ENM";
BA_ "VNSigAllNodes" SG_ 298 RdSpdCatType 1;
BA_ "GenSigSendType" SG_ 298 RdSpdCatType 10;
BA_ "GenSigSendOnInit" SG_ 298 RdSpdCatType 1;
BA_ "SignalLongName" SG_ 298 LnCat "Lane Category";
BA_ "SignalType" SG_ 298 LnCat "ENM";
BA_ "VNSigAllNodes" SG_ 298 LnCat 1;
BA_ "GenSigSendType" SG_ 298 LnCat 10;
BA_ "GenSigSendOnInit" SG_ 298 LnCat 1;
BA_ "SignalLongName" SG_ 298 FncRdClass "Functional Road Class";
BA_ "SignalType" SG_ 298 FncRdClass "ENM";
BA_ "VNSigAllNodes" SG_ 298 FncRdClass 1;
BA_ "GenSigSendType" SG_ 298 FncRdClass 10;
BA_ "GenSigSendOnInit" SG_ 298 FncRdClass 1;
BA_ "SignalLongName" SG_ 298 SprtLnRd "Separate Lane Road";
BA_ "SignalType" SG_ 298 SprtLnRd "BLN";
BA_ "VNSigAllNodes" SG_ 298 SprtLnRd 1;
BA_ "GenSigSendType" SG_ 298 SprtLnRd 10;
BA_ "GenSigSendOnInit" SG_ 298 SprtLnRd 1;
BA_ "SignalLongName" SG_ 298 CntrldAccRd "Controlled Access Road";
BA_ "SignalType" SG_ 298 CntrldAccRd "BLN";
BA_ "VNSigAllNodes" SG_ 298 CntrldAccRd 1;
BA_ "GenSigSendType" SG_ 298 CntrldAccRd 10;
BA_ "GenSigSendOnInit" SG_ 298 CntrldAccRd 1;
BA_ "SignalLongName" SG_ 298 BldUpArDet "Build Up Area Detected";
BA_ "SignalType" SG_ 298 BldUpArDet "BLN";
BA_ "VNSigAllNodes" SG_ 298 BldUpArDet 1;
BA_ "GenSigSendType" SG_ 298 BldUpArDet 10;
BA_ "GenSigSendOnInit" SG_ 298 BldUpArDet 1;
BA_ "SignalLongName" SG_ 298 MpDataAvlbl "Map Data Available";
BA_ "SignalType" SG_ 298 MpDataAvlbl "BLN";
BA_ "VNSigAllNodes" SG_ 298 MpDataAvlbl 1;
BA_ "GenSigSendType" SG_ 298 MpDataAvlbl 10;
BA_ "GenSigSendOnInit" SG_ 298 MpDataAvlbl 1;
BA_ "SignalLongName" SG_ 298 SusCustStngReq "Suspension Customization Setting Request";
BA_ "SignalType" SG_ 298 SusCustStngReq "ENM";
BA_ "VNSigAllNodes" SG_ 298 SusCustStngReq 1;
BA_ "GenSigSendType" SG_ 298 SusCustStngReq 10;
BA_ "GenSigSendOnInit" SG_ 298 SusCustStngReq 1;
BA_ "SignalLongName" SG_ 298 StrCustStngReq "Steering Customization Setting Request";
BA_ "SignalType" SG_ 298 StrCustStngReq "ENM";
BA_ "VNSigAllNodes" SG_ 298 StrCustStngReq 1;
BA_ "GenSigSendType" SG_ 298 StrCustStngReq 10;
BA_ "GenSigSendOnInit" SG_ 298 StrCustStngReq 1;
BA_ "SignalLongName" SG_ 298 RstrCustFctrDef "Restore Customization Factory Defaults";
BA_ "SignalType" SG_ 298 RstrCustFctrDef "ENM";
BA_ "VNSigAllNodes" SG_ 298 RstrCustFctrDef 1;
BA_ "GenSigSendType" SG_ 298 RstrCustFctrDef 10;
BA_ "GenSigSendOnInit" SG_ 298 RstrCustFctrDef 1;
BA_ "SignalLongName" SG_ 298 DrvlnCustStngReq "Driveline Customization Setting Request";
BA_ "SignalType" SG_ 298 DrvlnCustStngReq "ENM";
BA_ "VNSigAllNodes" SG_ 298 DrvlnCustStngReq 1;
BA_ "GenSigSendType" SG_ 298 DrvlnCustStngReq 10;
BA_ "GenSigSendOnInit" SG_ 298 DrvlnCustStngReq 1;
BA_ "GenSigStartValue" SG_ 298 ChmMstrVDA 1;
BA_ "SignalLongName" SG_ 298 ChmMstrVDA "Chime Master Virtual Device Availability";
BA_ "SignalType" SG_ 298 ChmMstrVDA "ENM";
BA_ "VNSigAllNodes" SG_ 298 ChmMstrVDA 1;
BA_ "GenSigStartValue" SG_ 298 IPCVDA 1;
BA_ "SignalLongName" SG_ 298 IPCVDA "Instrument Panel Cluster Virtual Device Availability";
BA_ "SignalType" SG_ 298 IPCVDA "ENM";
BA_ "VNSigAllNodes" SG_ 298 IPCVDA 1;
BA_ "GenSigStartValue" SG_ 298 HeadUpDispVDA 1;
BA_ "SignalLongName" SG_ 298 HeadUpDispVDA "Head Up Display Virtual Device Availability";
BA_ "SignalType" SG_ 298 HeadUpDispVDA "ENM";
BA_ "VNSigAllNodes" SG_ 298 HeadUpDispVDA 1;
BA_ "GenSigStartValue" SG_ 298 HapticSeatVDA 1;
BA_ "SignalLongName" SG_ 298 HapticSeatVDA "Haptic Seat Virtual Device Availability";
BA_ "SignalType" SG_ 298 HapticSeatVDA "ENM";
BA_ "VNSigAllNodes" SG_ 298 HapticSeatVDA 1;
BA_ "SignalLongName" SG_ 298 RRDoorAjarSwAct "Rear Right Door Ajar Switch Active";
BA_ "SignalType" SG_ 298 RRDoorAjarSwAct "BLN";
BA_ "VNSigAllNodes" SG_ 298 RRDoorAjarSwAct 1;
BA_ "GenSigSendType" SG_ 298 RRDoorAjarSwAct 10;
BA_ "GenSigSendOnInit" SG_ 298 RRDoorAjarSwAct 2;
BA_ "SignalLongName" SG_ 298 PDAjrSwAtv "Passenger Door Ajar Switch Active";
BA_ "SignalType" SG_ 298 PDAjrSwAtv "BLN";
BA_ "VNSigAllNodes" SG_ 298 PDAjrSwAtv 1;
BA_ "GenSigSendType" SG_ 298 PDAjrSwAtv 10;
BA_ "GenSigSendOnInit" SG_ 298 PDAjrSwAtv 2;
BA_ "GenSigStartValue" SG_ 298 TrlrHWIntrfcVDA 1;
BA_ "SignalLongName" SG_ 298 TrlrHWIntrfcVDA "Trailer Hardware Interface Virtual Device Availability";
BA_ "SignalType" SG_ 298 TrlrHWIntrfcVDA "ENM";
BA_ "VNSigAllNodes" SG_ 298 TrlrHWIntrfcVDA 1;
BA_ "GenSigStartValue" SG_ 298 DrId 7;
BA_ "SignalLongName" SG_ 298 DrId "Driver Identifier";
BA_ "SignalType" SG_ 298 DrId "ENM";
BA_ "VNSigAllNodes" SG_ 298 DrId 1;
BA_ "GenSigSendType" SG_ 298 DrId 10;
BA_ "GenSigSendOnInit" SG_ 298 DrId 1;
BA_ "SignalLongName" SG_ 298 EnrgMgtLdShdRq "Energy Management Load Shedding Request";
BA_ "SignalType" SG_ 298 EnrgMgtLdShdRq "ENM";
BA_ "VNSigAllNodes" SG_ 298 EnrgMgtLdShdRq 1;
BA_ "SignalLongName" SG_ 298 TreInfMonSysRstReq "Tire Inflation Monitoring System Reset Requested";
BA_ "SignalType" SG_ 298 TreInfMonSysRstReq "BLN";
BA_ "VNSigAllNodes" SG_ 298 TreInfMonSysRstReq 1;
BA_ "GenSigSendType" SG_ 298 TreInfMonSysRstReq 10;
BA_ "SignalLongName" SG_ 298 HUDActv "Head Up Display Active";
BA_ "SignalType" SG_ 298 HUDActv "BLN";
BA_ "VNSigAllNodes" SG_ 298 HUDActv 1;
BA_ "GenSigSendType" SG_ 298 HUDActv 10;
BA_ "SignalLongName" SG_ 298 RLDoorAjarSwAct "Rear Left Door Ajar Switch Active";
BA_ "SignalType" SG_ 298 RLDoorAjarSwAct "BLN";
BA_ "VNSigAllNodes" SG_ 298 RLDoorAjarSwAct 1;
BA_ "GenSigSendType" SG_ 298 RLDoorAjarSwAct 10;
BA_ "SignalLongName" SG_ 298 AutoMdSpdLmtCnfrmd "Auto Mode Speed Limit Confirmed";
BA_ "SignalType" SG_ 298 AutoMdSpdLmtCnfrmd "BLN";
BA_ "VNSigAllNodes" SG_ 298 AutoMdSpdLmtCnfrmd 1;
BA_ "GenSigSendType" SG_ 298 AutoMdSpdLmtCnfrmd 10;
BA_ "SignalLongName" SG_ 298 TCSysDisSwAtvARC "Traction Control System Disable Switch Active Alive Rolling Count";
BA_ "SignalType" SG_ 298 TCSysDisSwAtvARC "UNM";
BA_ "VNSigAllNodes" SG_ 298 TCSysDisSwAtvARC 1;
BA_ "SignalLongName" SG_ 298 TCSysDisSwAtv_12A "Traction Control System Disable Switch Active";
BA_ "SignalType" SG_ 298 TCSysDisSwAtv_12A "BLN";
BA_ "VNSigAllNodes" SG_ 298 TCSysDisSwAtv_12A 1;
BA_ "SignalLongName" SG_ 298 DDAjrSwAtvM "Driver Door Ajar Switch Active Mask";
BA_ "SignalType" SG_ 298 DDAjrSwAtvM "ENM";
BA_ "VNSigAllNodes" SG_ 298 DDAjrSwAtvM 1;
BA_ "SignalLongName" SG_ 298 DDAjrSwAtv "Driver Door Ajar Switch Active";
BA_ "SignalType" SG_ 298 DDAjrSwAtv "BLN";
BA_ "VNSigAllNodes" SG_ 298 DDAjrSwAtv 1;
BA_ "GenSigSendType" SG_ 298 DDAjrSwAtv 10;
BA_ "GenSigSendOnInit" SG_ 298 DDAjrSwAtv 2;
BA_ "SignalLongName" SG_ 298 DrSbltAtcV "Driver Seatbelt Attached Validity";
BA_ "SignalType" SG_ 298 DrSbltAtcV "ENM";
BA_ "VNSigAllNodes" SG_ 298 DrSbltAtcV 1;
BA_ "GenSigSendType" SG_ 298 DrSbltAtcV 10;
BA_ "SignalLongName" SG_ 298 TrlrHtchSwAtv "Trailer Hitch Switch Active";
BA_ "SignalType" SG_ 298 TrlrHtchSwAtv "BLN";
BA_ "VNSigAllNodes" SG_ 298 TrlrHtchSwAtv 1;
BA_ "GenSigSendType" SG_ 298 TrlrHtchSwAtv 10;
BA_ "GenSigSendOnInit" SG_ 298 TrlrHtchSwAtv 2;
BA_ "SignalLongName" SG_ 298 BatVltV "Battery Voltage Validity";
BA_ "SignalType" SG_ 298 BatVltV "ENM";
BA_ "VNSigAllNodes" SG_ 298 BatVltV 1;
BA_ "SignalLongName" SG_ 298 BatVlt "Battery Voltage";
BA_ "SignalType" SG_ 298 BatVlt "UNM";
BA_ "VNSigAllNodes" SG_ 298 BatVlt 1;
BA_ "SignalLongName" SG_ 298 DrSbltAtc "Driver Seatbelt Attached";
BA_ "SignalType" SG_ 298 DrSbltAtc "BLN";
BA_ "VNSigAllNodes" SG_ 298 DrSbltAtc 1;
BA_ "GenSigSendType" SG_ 298 DrSbltAtc 10;
BA_ "SignalLongName" SG_ 485 StrAngSnsChksm "Steering Angle Sensor state0589";
BA_ "SignalType" SG_ 485 StrAngSnsChksm "UNM";
BA_ "VNSigAllNodes" SG_ 485 StrAngSnsChksm 1;
BA_ "SignalLongName" SG_ 485 StrWhAngGrdV "Steering Wheel Angle Gradient Validity";
BA_ "SignalType" SG_ 485 StrWhAngGrdV "ENM";
BA_ "VNSigAllNodes" SG_ 485 StrWhAngGrdV 1;
BA_ "SignalLongName" SG_ 485 StrWhlAngSenCalStat "Steering Wheel Angle Sensor Calibration Status";
BA_ "SignalType" SG_ 485 StrWhlAngSenCalStat "ENM";
BA_ "VNSigAllNodes" SG_ 485 StrWhlAngSenCalStat 1;
BA_ "SignalLongName" SG_ 485 StrWhAngGrd "Steering Wheel Angle Gradient";
BA_ "SignalType" SG_ 485 StrWhAngGrd "SNM";
BA_ "VNSigAllNodes" SG_ 485 StrWhAngGrd 1;
BA_ "SignalLongName" SG_ 485 StrWhAngV "Steering Wheel Angle Validity";
BA_ "SignalType" SG_ 485 StrWhAngV "ENM";
BA_ "VNSigAllNodes" SG_ 485 StrWhAngV 1;
BA_ "SignalLongName" SG_ 485 StrWhAng "Steering Wheel Angle";
BA_ "SignalType" SG_ 485 StrWhAng "SNM";
BA_ "VNSigAllNodes" SG_ 485 StrWhAng 1;
BA_ "SignalLongName" SG_ 485 StrWhAngGrdMsk "Steering Wheel Angle Gradient Mask";
BA_ "SignalType" SG_ 485 StrWhAngGrdMsk "ENM";
BA_ "VNSigAllNodes" SG_ 485 StrWhAngGrdMsk 1;
BA_ "SignalLongName" SG_ 485 StrWhAngMsk "Steering Wheel Angle Mask";
BA_ "SignalType" SG_ 485 StrWhAngMsk "ENM";
BA_ "VNSigAllNodes" SG_ 485 StrWhAngMsk 1;
BA_ "SignalLongName" SG_ 485 StrWhlAngSenTyp "Steering Wheel Angle Sensor Type";
BA_ "SignalType" SG_ 485 StrWhlAngSenTyp "ENM";
BA_ "VNSigAllNodes" SG_ 485 StrWhlAngSenTyp 1;
BA_ "SignalLongName" SG_ 485 StWhlAngAliveRollCnt "Steering Wheel Angle Alive Rolling Count";
BA_ "SignalType" SG_ 485 StWhlAngAliveRollCnt "UNM";
BA_ "VNSigAllNodes" SG_ 485 StWhlAngAliveRollCnt 1;
BA_ "SignalLongName" SG_ 1241 FSERDTC_CdNum "Fuel System Emissions Related DTC : Code Number";
BA_ "PacketOrder" SG_ 1241 FSERDTC_CdNum 2;
BA_ "SignalType" SG_ 1241 FSERDTC_CdNum "UNM";
BA_ "VNSigAllNodes" SG_ 1241 FSERDTC_CdNum 1;
BA_ "SignalLongName" SG_ 1241 FSERDTC_SysDes "Fuel System Emissions Related DTC : System Designator";
BA_ "PacketOrder" SG_ 1241 FSERDTC_SysDes 1;
BA_ "SignalType" SG_ 1241 FSERDTC_SysDes "ENM";
BA_ "VNSigAllNodes" SG_ 1241 FSERDTC_SysDes 1;
BA_ "SignalLongName" SG_ 1241 FuelSysEmsRldMlfAtv "Fuel System Emissions Related Malfunction Active";
BA_ "SignalType" SG_ 1241 FuelSysEmsRldMlfAtv "BLN";
BA_ "VNSigAllNodes" SG_ 1241 FuelSysEmsRldMlfAtv 1;
BA_ "SignalLongName" SG_ 491 ExhPrsRgVlv2Pos "Exhaust Pressure Regulator Valve 2 Position";
BA_ "SignalType" SG_ 491 ExhPrsRgVlv2Pos "ENM";
BA_ "VNSigAllNodes" SG_ 491 ExhPrsRgVlv2Pos 1;
BA_ "SignalLongName" SG_ 491 ExhPrsRgVlv2PosV "Exhaust Pressure Regulator Valve 2 Position Validity";
BA_ "SignalType" SG_ 491 ExhPrsRgVlv2PosV "ENM";
BA_ "VNSigAllNodes" SG_ 491 ExhPrsRgVlv2PosV 1;
BA_ "SignalLongName" SG_ 491 ExhPrsRgVlvPosV "Exhaust Pressure Regulator Valve Position Validity";
BA_ "SignalType" SG_ 491 ExhPrsRgVlvPosV "ENM";
BA_ "VNSigAllNodes" SG_ 491 ExhPrsRgVlvPosV 1;
BA_ "SignalLongName" SG_ 491 ExhPrsRgVlvPos "Exhaust Pressure Regulator Valve Position";
BA_ "SignalType" SG_ 491 ExhPrsRgVlvPos "ENM";
BA_ "VNSigAllNodes" SG_ 491 ExhPrsRgVlvPos 1;
BA_ "SignalLongName" SG_ 491 FuelSysEstPressDlvrd "Fuel System Estimated Pressure Delivered";
BA_ "SignalType" SG_ 491 FuelSysEstPressDlvrd "UNM";
BA_ "VNSigAllNodes" SG_ 491 FuelSysEstPressDlvrd 1;
BA_ "SignalLongName" SG_ 491 FuelSysEstPressDlvrdV "Fuel System Estimated Pressure Delivered Validity";
BA_ "SignalType" SG_ 491 FuelSysEstPressDlvrdV "ENM";
BA_ "VNSigAllNodes" SG_ 491 FuelSysEstPressDlvrdV 1;
BA_ "SignalLongName" SG_ 409 TrnsAliveRC_199 "Transmission Alive Rolling Count 199";
BA_ "SignalType" SG_ 409 TrnsAliveRC_199 "UNM";
BA_ "VNSigAllNodes" SG_ 409 TrnsAliveRC_199 1;
BA_ "SignalLongName" SG_ 409 TDslPrtFltrIdlRgtnMdAtv "Transmission Diesel Particulate Filter Idle Regeneration Mode Active";
BA_ "SignalType" SG_ 409 TDslPrtFltrIdlRgtnMdAtv "BLN";
BA_ "VNSigAllNodes" SG_ 409 TDslPrtFltrIdlRgtnMdAtv 1;
BA_ "SignalLongName" SG_ 409 TransMinVoltReq "Transmission Minimum Voltage Request";
BA_ "SignalType" SG_ 409 TransMinVoltReq "UNM";
BA_ "VNSigAllNodes" SG_ 409 TransMinVoltReq 1;
BA_ "GenSigStartValue" SG_ 409 TransVehTopSpdLim 255;
BA_ "SignalLongName" SG_ 409 TransVehTopSpdLim "Transmission Vehicle Top Speed Limit Value";
BA_ "SignalType" SG_ 409 TransVehTopSpdLim "UNM";
BA_ "VNSigAllNodes" SG_ 409 TransVehTopSpdLim 1;
BA_ "SignalLongName" SG_ 409 TrnsTrqRqProt "Transmission Torque Request Protection";
BA_ "SignalType" SG_ 409 TrnsTrqRqProt "UNM";
BA_ "VNSigAllNodes" SG_ 409 TrnsTrqRqProt 1;
BA_ "SignalLongName" SG_ 409 TTRLT_TorqReqVal "Transmission Torque Request Long-term : Torque Request Value";
BA_ "PacketOrder" SG_ 409 TTRLT_TorqReqVal 3;
BA_ "SignalType" SG_ 409 TTRLT_TorqReqVal "UNM";
BA_ "VNSigAllNodes" SG_ 409 TTRLT_TorqReqVal 1;
BA_ "SignalLongName" SG_ 409 TTRLT_TqRdnRlznSgg "Transmission Torque Request Long-term : Torque Reduction Realization Suggestion";
BA_ "PacketOrder" SG_ 409 TTRLT_TqRdnRlznSgg 2;
BA_ "SignalType" SG_ 409 TTRLT_TqRdnRlznSgg "ENM";
BA_ "VNSigAllNodes" SG_ 409 TTRLT_TqRdnRlznSgg 1;
BA_ "SignalLongName" SG_ 409 TTRLT_TorqInvntnTyp "Transmission Torque Request Long-term : Torque Intervention Type";
BA_ "PacketOrder" SG_ 409 TTRLT_TorqInvntnTyp 1;
BA_ "SignalType" SG_ 409 TTRLT_TorqInvntnTyp "ENM";
BA_ "VNSigAllNodes" SG_ 409 TTRLT_TorqInvntnTyp 1;
BA_ "SignalLongName" SG_ 409 TTRST_TorqReqVal "Transmission Torque Request Short-term : Torque Request Value";
BA_ "PacketOrder" SG_ 409 TTRST_TorqReqVal 2;
BA_ "SignalType" SG_ 409 TTRST_TorqReqVal "UNM";
BA_ "VNSigAllNodes" SG_ 409 TTRST_TorqReqVal 1;
BA_ "SignalLongName" SG_ 409 TTRST_TorqInvntnTyp "Transmission Torque Request Short-term : Torque Intervention Type";
BA_ "PacketOrder" SG_ 409 TTRST_TorqInvntnTyp 1;
BA_ "SignalType" SG_ 409 TTRST_TorqInvntnTyp "ENM";
BA_ "VNSigAllNodes" SG_ 409 TTRST_TorqInvntnTyp 1;
BA_ "SignalLongName" SG_ 413 TrnsCyDactTransStat "Transmission Cylinder Deactivation Transition Status";
BA_ "SignalType" SG_ 413 TrnsCyDactTransStat "ENM";
BA_ "VNSigAllNodes" SG_ 413 TrnsCyDactTransStat 1;
BA_ "SignalLongName" SG_ 413 EngBrkDsblReqd "Engine Brake Disable Requested";
BA_ "SignalType" SG_ 413 EngBrkDsblReqd "BLN";
BA_ "VNSigAllNodes" SG_ 413 EngBrkDsblReqd 1;
BA_ "SignalLongName" SG_ 413 TransNtrlCntrlMdStat "Transmission Neutral Control Mode Status";
BA_ "SignalType" SG_ 413 TransNtrlCntrlMdStat "ENM";
BA_ "VNSigAllNodes" SG_ 413 TransNtrlCntrlMdStat 1;
BA_ "SignalLongName" SG_ 413 TrnsRtoCntlSysFlt "Transmission Ratio Control System Fault";
BA_ "SignalType" SG_ 413 TrnsRtoCntlSysFlt "BLN";
BA_ "VNSigAllNodes" SG_ 413 TrnsRtoCntlSysFlt 1;
BA_ "SignalLongName" SG_ 413 TrnTrbAngVl "Transmission Turbine Angular Velocity";
BA_ "SignalType" SG_ 413 TrnTrbAngVl "UNM";
BA_ "VNSigAllNodes" SG_ 413 TrnTrbAngVl 1;
BA_ "SignalLongName" SG_ 413 TrnTrbAngVlV "Transmission Turbine Angular Velocity Validity";
BA_ "SignalType" SG_ 413 TrnTrbAngVlV "ENM";
BA_ "VNSigAllNodes" SG_ 413 TrnTrbAngVlV 1;
BA_ "SignalLongName" SG_ 413 TrnGrRat "Transmission Gear Ratio";
BA_ "SignalType" SG_ 413 TrnGrRat "UNM";
BA_ "VNSigAllNodes" SG_ 413 TrnGrRat 1;
BA_ "SignalLongName" SG_ 413 TrnGrRatV "Transmission Gear Ratio Validity";
BA_ "SignalType" SG_ 413 TrnGrRatV "ENM";
BA_ "VNSigAllNodes" SG_ 413 TrnGrRatV 1;
BA_ "SignalLongName" SG_ 413 TrnPrfAlgShfAtv "Transmission Performance Algorithm Shift Mode Active";
BA_ "SignalType" SG_ 413 TrnPrfAlgShfAtv "BLN";
BA_ "VNSigAllNodes" SG_ 413 TrnPrfAlgShfAtv 1;
BA_ "SignalLongName" SG_ 413 TrnsAliveRC "Transmission Alive Rolling Count";
BA_ "SignalType" SG_ 413 TrnsAliveRC "UNM";
BA_ "VNSigAllNodes" SG_ 413 TrnsAliveRC 1;
BA_ "SignalLongName" SG_ 413 TrnsEngSpdRqProt "Transmission Engine Speed Request Protection";
BA_ "SignalType" SG_ 413 TrnsEngSpdRqProt "UNM";
BA_ "VNSigAllNodes" SG_ 413 TrnsEngSpdRqProt 1;
BA_ "SignalLongName" SG_ 413 TESR_EngSpdCntlRsp "Transmission Engine Speed Request : Engine Speed Control Response";
BA_ "PacketOrder" SG_ 413 TESR_EngSpdCntlRsp 2;
BA_ "SignalType" SG_ 413 TESR_EngSpdCntlRsp "ENM";
BA_ "VNSigAllNodes" SG_ 413 TESR_EngSpdCntlRsp 1;
BA_ "SignalLongName" SG_ 413 TESR_EngSpdRqVal "Transmission Engine Speed Request : Engine Speed Request Value";
BA_ "PacketOrder" SG_ 413 TESR_EngSpdRqVal 3;
BA_ "SignalType" SG_ 413 TESR_EngSpdRqVal "UNM";
BA_ "VNSigAllNodes" SG_ 413 TESR_EngSpdRqVal 1;
BA_ "SignalLongName" SG_ 413 TESR_EngSpdIntTyp "Transmission Engine Speed Request : Engine Speed Intervention Type";
BA_ "PacketOrder" SG_ 413 TESR_EngSpdIntTyp 1;
BA_ "SignalType" SG_ 413 TESR_EngSpdIntTyp "ENM";
BA_ "VNSigAllNodes" SG_ 413 TESR_EngSpdIntTyp 1;
BA_ "SignalLongName" SG_ 413 TrnsGrgShftAct "Transmission Garage Shift Active";
BA_ "SignalType" SG_ 413 TrnsGrgShftAct "BLN";
BA_ "VNSigAllNodes" SG_ 413 TrnsGrgShftAct 1;
BA_ "SignalLongName" SG_ 257 DgnInf "Diagnostic Information";
BA_ "SignalType" SG_ 257 DgnInf "UNM";
BA_ "VNSigAllNodes" SG_ 257 DgnInf 1;
BA_ "VNSigSLHSSharedDiagnostic" SG_ 257 DgnInf 1;
BA_ "SignalLongName" SG_ 2015 DgnInf "Diagnostic Information";
BA_ "SignalType" SG_ 2015 DgnInf "UNM";
BA_ "VNSigAllNodes" SG_ 2015 DgnInf 1;
BA_ "VNSigSLHSSharedDiagnostic" SG_ 2015 DgnInf 1;
BA_ "SignalLongName" SG_ 2016 DgnInf "Diagnostic Information";
BA_ "SignalType" SG_ 2016 DgnInf "UNM";
BA_ "VNSigAllNodes" SG_ 2016 DgnInf 1;
BA_ "VNSigSLHSSharedDiagnostic" SG_ 2016 DgnInf 1;
BA_REL_ "GenSigTimeoutTime" BU_SG_REL_ ECM_HS SG_ 1273 BrkSyCtl1EmsRldMlfAct 1250;
BA_REL_ "GenSigTimeoutMsg" BU_SG_REL_ ECM_HS SG_ 1273 BrkSyCtl1EmsRldMlfAct 1273;
BA_REL_ "GenSigSuprvResp" BU_SG_REL_ ECM_HS SG_ 1273 BrkSyCtl1EmsRldMlfAct 1;
BA_REL_ "GenSigTimeoutTime" BU_SG_REL_ ECM_HS SG_ 1273 BSC1ERDTC_CdNum 1250;
BA_REL_ "GenSigTimeoutMsg" BU_SG_REL_ ECM_HS SG_ 1273 BSC1ERDTC_CdNum 1273;
BA_REL_ "GenSigSuprvResp" BU_SG_REL_ ECM_HS SG_ 1273 BSC1ERDTC_CdNum 1;
BA_REL_ "GenSigTimeoutTime" BU_SG_REL_ ECM_HS SG_ 1273 BSC1ERDTC_SysDes 1250;
BA_REL_ "GenSigTimeoutMsg" BU_SG_REL_ ECM_HS SG_ 1273 BSC1ERDTC_SysDes 1273;
BA_REL_ "GenSigSuprvResp" BU_SG_REL_ ECM_HS SG_ 1273 BSC1ERDTC_SysDes 1;
BA_REL_ "GenSigTimeoutTime" BU_SG_REL_ ECM_HS SG_ 407 TransRatio 250;
BA_REL_ "GenSigTimeoutMsg" BU_SG_REL_ ECM_HS SG_ 407 TransRatio 407;
BA_REL_ "GenSigSuprvResp" BU_SG_REL_ ECM_HS SG_ 407 TransRatio 1;
BA_REL_ "GenSigTimeoutTime" BU_SG_REL_ ECM_HS SG_ 189 HybDisengCruzCmnd 250;
BA_REL_ "GenSigTimeoutMsg" BU_SG_REL_ ECM_HS SG_ 189 HybDisengCruzCmnd 189;
BA_REL_ "GenSigSuprvResp" BU_SG_REL_ ECM_HS SG_ 189 HybDisengCruzCmnd 1;
BA_REL_ "GenSigTimeoutTime" BU_SG_REL_ ECM_HS SG_ 1221 SpdLmtVsnFsdSpdUnt 1250;
BA_REL_ "GenSigTimeoutMsg" BU_SG_REL_ ECM_HS SG_ 1221 SpdLmtVsnFsdSpdUnt 1221;
BA_REL_ "GenSigSuprvResp" BU_SG_REL_ ECM_HS SG_ 1221 SpdLmtVsnFsdSpdUnt 1;
BA_REL_ "GenSigTimeoutTime" BU_SG_REL_ ECM_HS SG_ 1221 SpdLmtVnFsSpdNwDet 1250;
BA_REL_ "GenSigTimeoutMsg" BU_SG_REL_ ECM_HS SG_ 1221 SpdLmtVnFsSpdNwDet 1221;
BA_REL_ "GenSigSuprvResp" BU_SG_REL_ ECM_HS SG_ 1221 SpdLmtVnFsSpdNwDet 1;
BA_REL_ "GenSigTimeoutTime" BU_SG_REL_ ECM_HS SG_ 1221 SpdLmtVsnFsdSpd 1250;
BA_REL_ "GenSigTimeoutMsg" BU_SG_REL_ ECM_HS SG_ 1221 SpdLmtVsnFsdSpd 1221;
BA_REL_ "GenSigSuprvResp" BU_SG_REL_ ECM_HS SG_ 1221 SpdLmtVsnFsdSpd 1;
BA_REL_ "GenSigTimeoutTime" BU_SG_REL_ ECM_HS SG_ 1243 CSERDTC_CdNum 1250;
BA_REL_ "GenSigTimeoutMsg" BU_SG_REL_ ECM_HS SG_ 1243 CSERDTC_CdNum 1243;
BA_REL_ "GenSigSuprvResp" BU_SG_REL_ ECM_HS SG_ 1243 CSERDTC_CdNum 1;
BA_REL_ "GenSigTimeoutTime" BU_SG_REL_ ECM_HS SG_ 1243 CSERDTC_SysDes 1250;
BA_REL_ "GenSigTimeoutMsg" BU_SG_REL_ ECM_HS SG_ 1243 CSERDTC_SysDes 1243;
BA_REL_ "GenSigSuprvResp" BU_SG_REL_ ECM_HS SG_ 1243 CSERDTC_SysDes 1;
BA_REL_ "GenSigTimeoutTime" BU_SG_REL_ ECM_HS SG_ 1243 ChsSysEmmRelMalfAct 1250;
BA_REL_ "GenSigTimeoutMsg" BU_SG_REL_ ECM_HS SG_ 1243 ChsSysEmmRelMalfAct 1243;
BA_REL_ "GenSigSuprvResp" BU_SG_REL_ ECM_HS SG_ 1243 ChsSysEmmRelMalfAct 1;
BA_REL_ "GenSigTimeoutTime" BU_SG_REL_ TCM_HS SG_ 508 LonLatAccSnsChk 125;
BA_REL_ "GenSigTimeoutMsg" BU_SG_REL_ TCM_HS SG_ 508 LonLatAccSnsChk 508;
BA_REL_ "GenSigSuprvResp" BU_SG_REL_ TCM_HS SG_ 508 LonLatAccSnsChk 1;
BA_REL_ "GenSigTimeoutTime" BU_SG_REL_ TCM_HS SG_ 508 LonLatAccSnsValARC 125;
BA_REL_ "GenSigTimeoutMsg" BU_SG_REL_ TCM_HS SG_ 508 LonLatAccSnsValARC 508;
BA_REL_ "GenSigSuprvResp" BU_SG_REL_ TCM_HS SG_ 508 LonLatAccSnsValARC 1;
BA_REL_ "GenSigTimeoutTime" BU_SG_REL_ ICCM_OBD_HS SG_ 508 LatAccSnsVal 250;
BA_REL_ "GenSigTimeoutMsg" BU_SG_REL_ ICCM_OBD_HS SG_ 508 LatAccSnsVal 508;
BA_REL_ "GenSigSuprvResp" BU_SG_REL_ ICCM_OBD_HS SG_ 508 LatAccSnsVal 1;
BA_REL_ "GenSigTimeoutTime" BU_SG_REL_ ICCM_HS SG_ 508 LatAccSnsVal 250;
BA_REL_ "GenSigTimeoutMsg" BU_SG_REL_ ICCM_HS SG_ 508 LatAccSnsVal 508;
BA_REL_ "GenSigSuprvResp" BU_SG_REL_ ICCM_HS SG_ 508 LatAccSnsVal 1;
BA_REL_ "GenSigTimeoutTime" BU_SG_REL_ TCM_HS SG_ 508 LatAccSnsVal 125;
BA_REL_ "GenSigTimeoutMsg" BU_SG_REL_ TCM_HS SG_ 508 LatAccSnsVal 508;
BA_REL_ "GenSigSuprvResp" BU_SG_REL_ TCM_HS SG_ 508 LatAccSnsVal 1;
BA_REL_ "GenSigTimeoutTime" BU_SG_REL_ ECM_HS SG_ 508 LatAccSnsVal 250;
BA_REL_ "GenSigTimeoutMsg" BU_SG_REL_ ECM_HS SG_ 508 LatAccSnsVal 508;
BA_REL_ "GenSigSuprvResp" BU_SG_REL_ ECM_HS SG_ 508 LatAccSnsVal 1;
BA_REL_ "GenSigTimeoutTime" BU_SG_REL_ ICCM_OBD_HS SG_ 508 LonAccSnsVal 250;
BA_REL_ "GenSigTimeoutMsg" BU_SG_REL_ ICCM_OBD_HS SG_ 508 LonAccSnsVal 508;
BA_REL_ "GenSigSuprvResp" BU_SG_REL_ ICCM_OBD_HS SG_ 508 LonAccSnsVal 1;
BA_REL_ "GenSigTimeoutTime" BU_SG_REL_ ICCM_HS SG_ 508 LonAccSnsVal 250;
BA_REL_ "GenSigTimeoutMsg" BU_SG_REL_ ICCM_HS SG_ 508 LonAccSnsVal 508;
BA_REL_ "GenSigSuprvResp" BU_SG_REL_ ICCM_HS SG_ 508 LonAccSnsVal 1;
BA_REL_ "GenSigTimeoutTime" BU_SG_REL_ TCM_HS SG_ 508 LonAccSnsVal 125;
BA_REL_ "GenSigTimeoutMsg" BU_SG_REL_ TCM_HS SG_ 508 LonAccSnsVal 508;
BA_REL_ "GenSigSuprvResp" BU_SG_REL_ TCM_HS SG_ 508 LonAccSnsVal 1;
BA_REL_ "GenSigTimeoutTime" BU_SG_REL_ ECM_HS SG_ 508 LonAccSnsVal 250;
BA_REL_ "GenSigTimeoutMsg" BU_SG_REL_ ECM_HS SG_ 508 LonAccSnsVal 508;
BA_REL_ "GenSigSuprvResp" BU_SG_REL_ ECM_HS SG_ 508 LonAccSnsVal 1;
BA_REL_ "GenSigTimeoutTime" BU_SG_REL_ ICCM_OBD_HS SG_ 508 CSTBATS_TrqVl 250;
BA_REL_ "GenSigTimeoutMsg" BU_SG_REL_ ICCM_OBD_HS SG_ 508 CSTBATS_TrqVl 508;
BA_REL_ "GenSigSuprvResp" BU_SG_REL_ ICCM_OBD_HS SG_ 508 CSTBATS_TrqVl 1;
BA_REL_ "GenSigTimeoutTime" BU_SG_REL_ ICCM_HS SG_ 508 CSTBATS_TrqVl 250;
BA_REL_ "GenSigTimeoutMsg" BU_SG_REL_ ICCM_HS SG_ 508 CSTBATS_TrqVl 508;
BA_REL_ "GenSigSuprvResp" BU_SG_REL_ ICCM_HS SG_ 508 CSTBATS_TrqVl 1;
BA_REL_ "GenSigTimeoutTime" BU_SG_REL_ TCM_HS SG_ 508 CSTBATS_TrqVl 125;
BA_REL_ "GenSigTimeoutMsg" BU_SG_REL_ TCM_HS SG_ 508 CSTBATS_TrqVl 508;
BA_REL_ "GenSigSuprvResp" BU_SG_REL_ TCM_HS SG_ 508 CSTBATS_TrqVl 1;
BA_REL_ "GenSigTimeoutTime" BU_SG_REL_ ECM_HS SG_ 508 CSTBATS_TrqVl 250;
BA_REL_ "GenSigTimeoutMsg" BU_SG_REL_ ECM_HS SG_ 508 CSTBATS_TrqVl 508;
BA_REL_ "GenSigSuprvResp" BU_SG_REL_ ECM_HS SG_ 508 CSTBATS_TrqVl 1;
BA_REL_ "GenSigTimeoutTime" BU_SG_REL_ ICCM_OBD_HS SG_ 508 CSTBATS_TrqVlV 250;
BA_REL_ "GenSigTimeoutMsg" BU_SG_REL_ ICCM_OBD_HS SG_ 508 CSTBATS_TrqVlV 508;
BA_REL_ "GenSigSuprvResp" BU_SG_REL_ ICCM_OBD_HS SG_ 508 CSTBATS_TrqVlV 1;
BA_REL_ "GenSigTimeoutTime" BU_SG_REL_ ICCM_HS SG_ 508 CSTBATS_TrqVlV 250;
BA_REL_ "GenSigTimeoutMsg" BU_SG_REL_ ICCM_HS SG_ 508 CSTBATS_TrqVlV 508;
BA_REL_ "GenSigSuprvResp" BU_SG_REL_ ICCM_HS SG_ 508 CSTBATS_TrqVlV 1;
BA_REL_ "GenSigTimeoutTime" BU_SG_REL_ TCM_HS SG_ 508 CSTBATS_TrqVlV 125;
BA_REL_ "GenSigTimeoutMsg" BU_SG_REL_ TCM_HS SG_ 508 CSTBATS_TrqVlV 508;
BA_REL_ "GenSigSuprvResp" BU_SG_REL_ TCM_HS SG_ 508 CSTBATS_TrqVlV 1;
BA_REL_ "GenSigTimeoutTime" BU_SG_REL_ ECM_HS SG_ 508 CSTBATS_TrqVlV 250;
BA_REL_ "GenSigTimeoutMsg" BU_SG_REL_ ECM_HS SG_ 508 CSTBATS_TrqVlV 508;
BA_REL_ "GenSigSuprvResp" BU_SG_REL_ ECM_HS SG_ 508 CSTBATS_TrqVlV 1;
BA_REL_ "GenSigTimeoutTime" BU_SG_REL_ ECM_HS SG_ 422 TrnsAuxPrsDisOvrrdOn 250;
BA_REL_ "GenSigTimeoutMsg" BU_SG_REL_ ECM_HS SG_ 422 TrnsAuxPrsDisOvrrdOn 422;
BA_REL_ "GenSigSuprvResp" BU_SG_REL_ ECM_HS SG_ 422 TrnsAuxPrsDisOvrrdOn 1;
BA_REL_ "GenSigTimeoutTime" BU_SG_REL_ ECM_HS SG_ 422 TransEngShtdwnRqd 250;
BA_REL_ "GenSigTimeoutMsg" BU_SG_REL_ ECM_HS SG_ 422 TransEngShtdwnRqd 422;
BA_REL_ "GenSigSuprvResp" BU_SG_REL_ ECM_HS SG_ 422 TransEngShtdwnRqd 1;
BA_REL_ "GenSigTimeoutTime" BU_SG_REL_ ECM_HS SG_ 422 TransCrksftTqLoad 250;
BA_REL_ "GenSigTimeoutMsg" BU_SG_REL_ ECM_HS SG_ 422 TransCrksftTqLoad 422;
BA_REL_ "GenSigSuprvResp" BU_SG_REL_ ECM_HS SG_ 422 TransCrksftTqLoad 1;
BA_REL_ "GenSigTimeoutTime" BU_SG_REL_ ECM_HS SG_ 422 TrStPTGrdBrkDsMdOvr 62;
BA_REL_ "GenSigTimeoutMsg" BU_SG_REL_ ECM_HS SG_ 422 TrStPTGrdBrkDsMdOvr 422;
BA_REL_ "GenSigSuprvResp" BU_SG_REL_ ECM_HS SG_ 422 TrStPTGrdBrkDsMdOvr 1;
BA_REL_ "GenSigTimeoutTime" BU_SG_REL_ ECM_HS SG_ 422 TrnsHybEngSrtStpOvrd 250;
BA_REL_ "GenSigTimeoutMsg" BU_SG_REL_ ECM_HS SG_ 422 TrnsHybEngSrtStpOvrd 422;
BA_REL_ "GenSigSuprvResp" BU_SG_REL_ ECM_HS SG_ 422 TrnsHybEngSrtStpOvrd 1;
BA_REL_ "GenSigTimeoutTime" BU_SG_REL_ ECM_HS SG_ 209 ChsBrkPdlPsERltdPVal 250;
BA_REL_ "GenSigTimeoutMsg" BU_SG_REL_ ECM_HS SG_ 209 ChsBrkPdlPsERltdPVal 209;
BA_REL_ "GenSigSuprvResp" BU_SG_REL_ ECM_HS SG_ 209 ChsBrkPdlPsERltdPVal 1;
BA_REL_ "GenSigTimeoutTime" BU_SG_REL_ ECM_HS SG_ 209 ChsBrkPdlPsERltdARC 250;
BA_REL_ "GenSigTimeoutMsg" BU_SG_REL_ ECM_HS SG_ 209 ChsBrkPdlPsERltdARC 209;
BA_REL_ "GenSigSuprvResp" BU_SG_REL_ ECM_HS SG_ 209 ChsBrkPdlPsERltdARC 1;
BA_REL_ "GenSigTimeoutTime" BU_SG_REL_ ECM_HS SG_ 209 ChsBrkPdlPsERltd 250;
BA_REL_ "GenSigTimeoutMsg" BU_SG_REL_ ECM_HS SG_ 209 ChsBrkPdlPsERltd 209;
BA_REL_ "GenSigSuprvResp" BU_SG_REL_ ECM_HS SG_ 209 ChsBrkPdlPsERltd 1;
BA_REL_ "GenSigTimeoutTime" BU_SG_REL_ ECM_HS SG_ 1189 TAFR_AirFlwReqTyp 1250;
BA_REL_ "GenSigTimeoutMsg" BU_SG_REL_ ECM_HS SG_ 1189 TAFR_AirFlwReqTyp 1189;
BA_REL_ "GenSigSuprvResp" BU_SG_REL_ ECM_HS SG_ 1189 TAFR_AirFlwReqTyp 1;
BA_REL_ "GenSigTimeoutTime" BU_SG_REL_ ECM_HS SG_ 1189 TAFR_AirFlwReqPrcnt 1250;
BA_REL_ "GenSigTimeoutMsg" BU_SG_REL_ ECM_HS SG_ 1189 TAFR_AirFlwReqPrcnt 1189;
BA_REL_ "GenSigSuprvResp" BU_SG_REL_ ECM_HS SG_ 1189 TAFR_AirFlwReqPrcnt 1;
BA_REL_ "GenSigTimeoutTime" BU_SG_REL_ TCM_HS SG_ 421 HybAuxTransPresCmndOn 250;
BA_REL_ "GenSigTimeoutMsg" BU_SG_REL_ TCM_HS SG_ 421 HybAuxTransPresCmndOn 421;
BA_REL_ "GenSigSuprvResp" BU_SG_REL_ TCM_HS SG_ 421 HybAuxTransPresCmndOn 1;
BA_REL_ "GenSigTimeoutTime" BU_SG_REL_ TCM_HS SG_ 421 HybEconBhvAlwd 250;
BA_REL_ "GenSigTimeoutMsg" BU_SG_REL_ TCM_HS SG_ 421 HybEconBhvAlwd 421;
BA_REL_ "GenSigSuprvResp" BU_SG_REL_ TCM_HS SG_ 421 HybEconBhvAlwd 1;
BA_REL_ "GenSigTimeoutTime" BU_SG_REL_ TCM_HS SG_ 421 HybTwHaulBhvAlwd 250;
BA_REL_ "GenSigTimeoutMsg" BU_SG_REL_ TCM_HS SG_ 421 HybTwHaulBhvAlwd 421;
BA_REL_ "GenSigSuprvResp" BU_SG_REL_ TCM_HS SG_ 421 HybTwHaulBhvAlwd 1;
BA_REL_ "GenSigTimeoutTime" BU_SG_REL_ TCM_HS SG_ 421 HybSnsBrkPdlPosPVal 250;
BA_REL_ "GenSigTimeoutMsg" BU_SG_REL_ TCM_HS SG_ 421 HybSnsBrkPdlPosPVal 421;
BA_REL_ "GenSigSuprvResp" BU_SG_REL_ TCM_HS SG_ 421 HybSnsBrkPdlPosPVal 1;
BA_REL_ "GenSigTimeoutTime" BU_SG_REL_ ECM_HS SG_ 421 HybSnsBrkPdlPosPVal 250;
BA_REL_ "GenSigTimeoutMsg" BU_SG_REL_ ECM_HS SG_ 421 HybSnsBrkPdlPosPVal 421;
BA_REL_ "GenSigSuprvResp" BU_SG_REL_ ECM_HS SG_ 421 HybSnsBrkPdlPosPVal 1;
BA_REL_ "GenSigTimeoutTime" BU_SG_REL_ TCM_HS SG_ 421 HybSnsBrkPdlPosARC 250;
BA_REL_ "GenSigTimeoutMsg" BU_SG_REL_ TCM_HS SG_ 421 HybSnsBrkPdlPosARC 421;
BA_REL_ "GenSigSuprvResp" BU_SG_REL_ TCM_HS SG_ 421 HybSnsBrkPdlPosARC 1;
BA_REL_ "GenSigTimeoutTime" BU_SG_REL_ ECM_HS SG_ 421 HybSnsBrkPdlPosARC 250;
BA_REL_ "GenSigTimeoutMsg" BU_SG_REL_ ECM_HS SG_ 421 HybSnsBrkPdlPosARC 421;
BA_REL_ "GenSigSuprvResp" BU_SG_REL_ ECM_HS SG_ 421 HybSnsBrkPdlPosARC 1;
BA_REL_ "GenSigTimeoutTime" BU_SG_REL_ ICCM_OBD_HS SG_ 421 HybSnsBrkPdlPos 250;
BA_REL_ "GenSigTimeoutMsg" BU_SG_REL_ ICCM_OBD_HS SG_ 421 HybSnsBrkPdlPos 421;
BA_REL_ "GenSigSuprvResp" BU_SG_REL_ ICCM_OBD_HS SG_ 421 HybSnsBrkPdlPos 1;
BA_REL_ "GenSigTimeoutTime" BU_SG_REL_ ICCM_HS SG_ 421 HybSnsBrkPdlPos 250;
BA_REL_ "GenSigTimeoutMsg" BU_SG_REL_ ICCM_HS SG_ 421 HybSnsBrkPdlPos 421;
BA_REL_ "GenSigSuprvResp" BU_SG_REL_ ICCM_HS SG_ 421 HybSnsBrkPdlPos 1;
BA_REL_ "GenSigTimeoutTime" BU_SG_REL_ TCM_HS SG_ 421 HybSnsBrkPdlPos 250;
BA_REL_ "GenSigTimeoutMsg" BU_SG_REL_ TCM_HS SG_ 421 HybSnsBrkPdlPos 421;
BA_REL_ "GenSigSuprvResp" BU_SG_REL_ TCM_HS SG_ 421 HybSnsBrkPdlPos 1;
BA_REL_ "GenSigTimeoutTime" BU_SG_REL_ ECM_HS SG_ 421 HybSnsBrkPdlPos 250;
BA_REL_ "GenSigTimeoutMsg" BU_SG_REL_ ECM_HS SG_ 421 HybSnsBrkPdlPos 421;
BA_REL_ "GenSigSuprvResp" BU_SG_REL_ ECM_HS SG_ 421 HybSnsBrkPdlPos 1;
BA_REL_ "GenSigTimeoutTime" BU_SG_REL_ ICCM_OBD_HS SG_ 456 PTTR_TrqReqVal 250;
BA_REL_ "GenSigTimeoutMsg" BU_SG_REL_ ICCM_OBD_HS SG_ 456 PTTR_TrqReqVal 456;
BA_REL_ "GenSigSuprvResp" BU_SG_REL_ ICCM_OBD_HS SG_ 456 PTTR_TrqReqVal 1;
BA_REL_ "GenSigTimeoutTime" BU_SG_REL_ ICCM_HS SG_ 456 PTTR_TrqReqVal 250;
BA_REL_ "GenSigTimeoutMsg" BU_SG_REL_ ICCM_HS SG_ 456 PTTR_TrqReqVal 456;
BA_REL_ "GenSigSuprvResp" BU_SG_REL_ ICCM_HS SG_ 456 PTTR_TrqReqVal 1;
BA_REL_ "GenSigTimeoutTime" BU_SG_REL_ ICCM_OBD_HS SG_ 456 PTTR_TrqRedRlzSugg 250;
BA_REL_ "GenSigTimeoutMsg" BU_SG_REL_ ICCM_OBD_HS SG_ 456 PTTR_TrqRedRlzSugg 456;
BA_REL_ "GenSigSuprvResp" BU_SG_REL_ ICCM_OBD_HS SG_ 456 PTTR_TrqRedRlzSugg 1;
BA_REL_ "GenSigTimeoutTime" BU_SG_REL_ ICCM_HS SG_ 456 PTTR_TrqRedRlzSugg 250;
BA_REL_ "GenSigTimeoutMsg" BU_SG_REL_ ICCM_HS SG_ 456 PTTR_TrqRedRlzSugg 456;
BA_REL_ "GenSigSuprvResp" BU_SG_REL_ ICCM_HS SG_ 456 PTTR_TrqRedRlzSugg 1;
BA_REL_ "GenSigTimeoutTime" BU_SG_REL_ ICCM_OBD_HS SG_ 456 PTTR_TrqInvTyp 250;
BA_REL_ "GenSigTimeoutMsg" BU_SG_REL_ ICCM_OBD_HS SG_ 456 PTTR_TrqInvTyp 456;
BA_REL_ "GenSigSuprvResp" BU_SG_REL_ ICCM_OBD_HS SG_ 456 PTTR_TrqInvTyp 1;
BA_REL_ "GenSigTimeoutTime" BU_SG_REL_ ICCM_HS SG_ 456 PTTR_TrqInvTyp 250;
BA_REL_ "GenSigTimeoutMsg" BU_SG_REL_ ICCM_HS SG_ 456 PTTR_TrqInvTyp 456;
BA_REL_ "GenSigSuprvResp" BU_SG_REL_ ICCM_HS SG_ 456 PTTR_TrqInvTyp 1;
BA_REL_ "GenSigTimeoutTime" BU_SG_REL_ ECM_HS SG_ 393 TIDCTR_TrqIntvTyp 250;
BA_REL_ "GenSigTimeoutMsg" BU_SG_REL_ ECM_HS SG_ 393 TIDCTR_TrqIntvTyp 393;
BA_REL_ "GenSigSuprvResp" BU_SG_REL_ ECM_HS SG_ 393 TIDCTR_TrqIntvTyp 1;
BA_REL_ "GenSigTimeoutTime" BU_SG_REL_ ECM_HS SG_ 393 TIDCTR_TrqReqVal 250;
BA_REL_ "GenSigTimeoutMsg" BU_SG_REL_ ECM_HS SG_ 393 TIDCTR_TrqReqVal 393;
BA_REL_ "GenSigSuprvResp" BU_SG_REL_ ECM_HS SG_ 393 TIDCTR_TrqReqVal 1;
BA_REL_ "GenSigTimeoutTime" BU_SG_REL_ ECM_HS SG_ 393 TIDCTR_TrqRespTyp 250;
BA_REL_ "GenSigTimeoutMsg" BU_SG_REL_ ECM_HS SG_ 393 TIDCTR_TrqRespTyp 393;
BA_REL_ "GenSigSuprvResp" BU_SG_REL_ ECM_HS SG_ 393 TIDCTR_TrqRespTyp 1;
BA_REL_ "GenSigTimeoutTime" BU_SG_REL_ ICCM_OBD_HS SG_ 199 TORSTimestamp 250;
BA_REL_ "GenSigTimeoutMsg" BU_SG_REL_ ICCM_OBD_HS SG_ 199 TORSTimestamp 199;
BA_REL_ "GenSigSuprvResp" BU_SG_REL_ ICCM_OBD_HS SG_ 199 TORSTimestamp 1;
BA_REL_ "GenSigTimeoutTime" BU_SG_REL_ EBCM_OBD_HS SG_ 199 TORSTimestamp 250;
BA_REL_ "GenSigTimeoutMsg" BU_SG_REL_ EBCM_OBD_HS SG_ 199 TORSTimestamp 199;
BA_REL_ "GenSigSuprvResp" BU_SG_REL_ EBCM_OBD_HS SG_ 199 TORSTimestamp 1;
BA_REL_ "GenSigTimeoutTime" BU_SG_REL_ ICCM_HS SG_ 199 TORSTimestamp 250;
BA_REL_ "GenSigTimeoutMsg" BU_SG_REL_ ICCM_HS SG_ 199 TORSTimestamp 199;
BA_REL_ "GenSigSuprvResp" BU_SG_REL_ ICCM_HS SG_ 199 TORSTimestamp 1;
BA_REL_ "GenSigTimeoutTime" BU_SG_REL_ TCCM_HS SG_ 199 TORSTimestamp 250;
BA_REL_ "GenSigTimeoutMsg" BU_SG_REL_ TCCM_HS SG_ 199 TORSTimestamp 199;
BA_REL_ "GenSigSuprvResp" BU_SG_REL_ TCCM_HS SG_ 199 TORSTimestamp 1;
BA_REL_ "GenSigTimeoutTime" BU_SG_REL_ EBCM_HS SG_ 199 TORSTimestamp 250;
BA_REL_ "GenSigTimeoutMsg" BU_SG_REL_ EBCM_HS SG_ 199 TORSTimestamp 199;
BA_REL_ "GenSigSuprvResp" BU_SG_REL_ EBCM_HS SG_ 199 TORSTimestamp 1;
BA_REL_ "GenSigTimeoutTime" BU_SG_REL_ ECM_HS SG_ 199 TORSTimestamp 250;
BA_REL_ "GenSigTimeoutMsg" BU_SG_REL_ ECM_HS SG_ 199 TORSTimestamp 199;
BA_REL_ "GenSigSuprvResp" BU_SG_REL_ ECM_HS SG_ 199 TORSTimestamp 1;
BA_REL_ "GenSigTimeoutTime" BU_SG_REL_ ICCM_OBD_HS SG_ 199 TORSPulsCntr 250;
BA_REL_ "GenSigTimeoutMsg" BU_SG_REL_ ICCM_OBD_HS SG_ 199 TORSPulsCntr 199;
BA_REL_ "GenSigSuprvResp" BU_SG_REL_ ICCM_OBD_HS SG_ 199 TORSPulsCntr 1;
BA_REL_ "GenSigTimeoutTime" BU_SG_REL_ EBCM_OBD_HS SG_ 199 TORSPulsCntr 250;
BA_REL_ "GenSigTimeoutMsg" BU_SG_REL_ EBCM_OBD_HS SG_ 199 TORSPulsCntr 199;
BA_REL_ "GenSigSuprvResp" BU_SG_REL_ EBCM_OBD_HS SG_ 199 TORSPulsCntr 1;
BA_REL_ "GenSigTimeoutTime" BU_SG_REL_ ICCM_HS SG_ 199 TORSPulsCntr 250;
BA_REL_ "GenSigTimeoutMsg" BU_SG_REL_ ICCM_HS SG_ 199 TORSPulsCntr 199;
BA_REL_ "GenSigSuprvResp" BU_SG_REL_ ICCM_HS SG_ 199 TORSPulsCntr 1;
BA_REL_ "GenSigTimeoutTime" BU_SG_REL_ TCCM_HS SG_ 199 TORSPulsCntr 250;
BA_REL_ "GenSigTimeoutMsg" BU_SG_REL_ TCCM_HS SG_ 199 TORSPulsCntr 199;
BA_REL_ "GenSigSuprvResp" BU_SG_REL_ TCCM_HS SG_ 199 TORSPulsCntr 1;
BA_REL_ "GenSigTimeoutTime" BU_SG_REL_ EBCM_HS SG_ 199 TORSPulsCntr 250;
BA_REL_ "GenSigTimeoutMsg" BU_SG_REL_ EBCM_HS SG_ 199 TORSPulsCntr 199;
BA_REL_ "GenSigSuprvResp" BU_SG_REL_ EBCM_HS SG_ 199 TORSPulsCntr 1;
BA_REL_ "GenSigTimeoutTime" BU_SG_REL_ ECM_HS SG_ 199 TORSPulsCntr 250;
BA_REL_ "GenSigTimeoutMsg" BU_SG_REL_ ECM_HS SG_ 199 TORSPulsCntr 199;
BA_REL_ "GenSigSuprvResp" BU_SG_REL_ ECM_HS SG_ 199 TORSPulsCntr 1;
BA_REL_ "GenSigTimeoutTime" BU_SG_REL_ ICCM_OBD_HS SG_ 199 TORSValidity 250;
BA_REL_ "GenSigTimeoutMsg" BU_SG_REL_ ICCM_OBD_HS SG_ 199 TORSValidity 199;
BA_REL_ "GenSigSuprvResp" BU_SG_REL_ ICCM_OBD_HS SG_ 199 TORSValidity 1;
BA_REL_ "GenSigTimeoutTime" BU_SG_REL_ EBCM_OBD_HS SG_ 199 TORSValidity 250;
BA_REL_ "GenSigTimeoutMsg" BU_SG_REL_ EBCM_OBD_HS SG_ 199 TORSValidity 199;
BA_REL_ "GenSigSuprvResp" BU_SG_REL_ EBCM_OBD_HS SG_ 199 TORSValidity 1;
BA_REL_ "GenSigTimeoutTime" BU_SG_REL_ ICCM_HS SG_ 199 TORSValidity 250;
BA_REL_ "GenSigTimeoutMsg" BU_SG_REL_ ICCM_HS SG_ 199 TORSValidity 199;
BA_REL_ "GenSigSuprvResp" BU_SG_REL_ ICCM_HS SG_ 199 TORSValidity 1;
BA_REL_ "GenSigTimeoutTime" BU_SG_REL_ TCCM_HS SG_ 199 TORSValidity 250;
BA_REL_ "GenSigTimeoutMsg" BU_SG_REL_ TCCM_HS SG_ 199 TORSValidity 199;
BA_REL_ "GenSigSuprvResp" BU_SG_REL_ TCCM_HS SG_ 199 TORSValidity 1;
BA_REL_ "GenSigTimeoutTime" BU_SG_REL_ EBCM_HS SG_ 199 TORSValidity 250;
BA_REL_ "GenSigTimeoutMsg" BU_SG_REL_ EBCM_HS SG_ 199 TORSValidity 199;
BA_REL_ "GenSigSuprvResp" BU_SG_REL_ EBCM_HS SG_ 199 TORSValidity 1;
BA_REL_ "GenSigTimeoutTime" BU_SG_REL_ ECM_HS SG_ 199 TORSValidity 250;
BA_REL_ "GenSigTimeoutMsg" BU_SG_REL_ ECM_HS SG_ 199 TORSValidity 199;
BA_REL_ "GenSigSuprvResp" BU_SG_REL_ ECM_HS SG_ 199 TORSValidity 1;
BA_REL_ "GenSigTimeoutTime" BU_SG_REL_ ICCM_OBD_HS SG_ 199 TORSRstOcrd 250;
BA_REL_ "GenSigTimeoutMsg" BU_SG_REL_ ICCM_OBD_HS SG_ 199 TORSRstOcrd 199;
BA_REL_ "GenSigSuprvResp" BU_SG_REL_ ICCM_OBD_HS SG_ 199 TORSRstOcrd 1;
BA_REL_ "GenSigTimeoutTime" BU_SG_REL_ EBCM_OBD_HS SG_ 199 TORSRstOcrd 250;
BA_REL_ "GenSigTimeoutMsg" BU_SG_REL_ EBCM_OBD_HS SG_ 199 TORSRstOcrd 199;
BA_REL_ "GenSigSuprvResp" BU_SG_REL_ EBCM_OBD_HS SG_ 199 TORSRstOcrd 1;
BA_REL_ "GenSigTimeoutTime" BU_SG_REL_ ICCM_HS SG_ 199 TORSRstOcrd 250;
BA_REL_ "GenSigTimeoutMsg" BU_SG_REL_ ICCM_HS SG_ 199 TORSRstOcrd 199;
BA_REL_ "GenSigSuprvResp" BU_SG_REL_ ICCM_HS SG_ 199 TORSRstOcrd 1;
BA_REL_ "GenSigTimeoutTime" BU_SG_REL_ TCCM_HS SG_ 199 TORSRstOcrd 250;
BA_REL_ "GenSigTimeoutMsg" BU_SG_REL_ TCCM_HS SG_ 199 TORSRstOcrd 199;
BA_REL_ "GenSigSuprvResp" BU_SG_REL_ TCCM_HS SG_ 199 TORSRstOcrd 1;
BA_REL_ "GenSigTimeoutTime" BU_SG_REL_ EBCM_HS SG_ 199 TORSRstOcrd 250;
BA_REL_ "GenSigTimeoutMsg" BU_SG_REL_ EBCM_HS SG_ 199 TORSRstOcrd 199;
BA_REL_ "GenSigSuprvResp" BU_SG_REL_ EBCM_HS SG_ 199 TORSRstOcrd 1;
BA_REL_ "GenSigTimeoutTime" BU_SG_REL_ ECM_HS SG_ 199 TORSRstOcrd 250;
BA_REL_ "GenSigTimeoutMsg" BU_SG_REL_ ECM_HS SG_ 199 TORSRstOcrd 199;
BA_REL_ "GenSigSuprvResp" BU_SG_REL_ ECM_HS SG_ 199 TORSRstOcrd 1;
BA_REL_ "GenSigTimeoutTime" BU_SG_REL_ ICCM_OBD_HS SG_ 199 TORSLstTransType 250;
BA_REL_ "GenSigTimeoutMsg" BU_SG_REL_ ICCM_OBD_HS SG_ 199 TORSLstTransType 199;
BA_REL_ "GenSigSuprvResp" BU_SG_REL_ ICCM_OBD_HS SG_ 199 TORSLstTransType 1;
BA_REL_ "GenSigTimeoutTime" BU_SG_REL_ EBCM_OBD_HS SG_ 199 TORSLstTransType 250;
BA_REL_ "GenSigTimeoutMsg" BU_SG_REL_ EBCM_OBD_HS SG_ 199 TORSLstTransType 199;
BA_REL_ "GenSigSuprvResp" BU_SG_REL_ EBCM_OBD_HS SG_ 199 TORSLstTransType 1;
BA_REL_ "GenSigTimeoutTime" BU_SG_REL_ ICCM_HS SG_ 199 TORSLstTransType 250;
BA_REL_ "GenSigTimeoutMsg" BU_SG_REL_ ICCM_HS SG_ 199 TORSLstTransType 199;
BA_REL_ "GenSigSuprvResp" BU_SG_REL_ ICCM_HS SG_ 199 TORSLstTransType 1;
BA_REL_ "GenSigTimeoutTime" BU_SG_REL_ TCCM_HS SG_ 199 TORSLstTransType 250;
BA_REL_ "GenSigTimeoutMsg" BU_SG_REL_ TCCM_HS SG_ 199 TORSLstTransType 199;
BA_REL_ "GenSigSuprvResp" BU_SG_REL_ TCCM_HS SG_ 199 TORSLstTransType 1;
BA_REL_ "GenSigTimeoutTime" BU_SG_REL_ EBCM_HS SG_ 199 TORSLstTransType 250;
BA_REL_ "GenSigTimeoutMsg" BU_SG_REL_ EBCM_HS SG_ 199 TORSLstTransType 199;
BA_REL_ "GenSigSuprvResp" BU_SG_REL_ EBCM_HS SG_ 199 TORSLstTransType 1;
BA_REL_ "GenSigTimeoutTime" BU_SG_REL_ ECM_HS SG_ 199 TORSLstTransType 250;
BA_REL_ "GenSigTimeoutMsg" BU_SG_REL_ ECM_HS SG_ 199 TORSLstTransType 199;
BA_REL_ "GenSigSuprvResp" BU_SG_REL_ ECM_HS SG_ 199 TORSLstTransType 1;
BA_REL_ "GenSigTimeoutTime" BU_SG_REL_ ICCM_OBD_HS SG_ 199 TORSRotDir 250;
BA_REL_ "GenSigTimeoutMsg" BU_SG_REL_ ICCM_OBD_HS SG_ 199 TORSRotDir 199;
BA_REL_ "GenSigSuprvResp" BU_SG_REL_ ICCM_OBD_HS SG_ 199 TORSRotDir 1;
BA_REL_ "GenSigTimeoutTime" BU_SG_REL_ EBCM_OBD_HS SG_ 199 TORSRotDir 250;
BA_REL_ "GenSigTimeoutMsg" BU_SG_REL_ EBCM_OBD_HS SG_ 199 TORSRotDir 199;
BA_REL_ "GenSigSuprvResp" BU_SG_REL_ EBCM_OBD_HS SG_ 199 TORSRotDir 1;
BA_REL_ "GenSigTimeoutTime" BU_SG_REL_ ICCM_HS SG_ 199 TORSRotDir 250;
BA_REL_ "GenSigTimeoutMsg" BU_SG_REL_ ICCM_HS SG_ 199 TORSRotDir 199;
BA_REL_ "GenSigSuprvResp" BU_SG_REL_ ICCM_HS SG_ 199 TORSRotDir 1;
BA_REL_ "GenSigTimeoutTime" BU_SG_REL_ TCCM_HS SG_ 199 TORSRotDir 250;
BA_REL_ "GenSigTimeoutMsg" BU_SG_REL_ TCCM_HS SG_ 199 TORSRotDir 199;
BA_REL_ "GenSigSuprvResp" BU_SG_REL_ TCCM_HS SG_ 199 TORSRotDir 1;
BA_REL_ "GenSigTimeoutTime" BU_SG_REL_ EBCM_HS SG_ 199 TORSRotDir 250;
BA_REL_ "GenSigTimeoutMsg" BU_SG_REL_ EBCM_HS SG_ 199 TORSRotDir 199;
BA_REL_ "GenSigSuprvResp" BU_SG_REL_ EBCM_HS SG_ 199 TORSRotDir 1;
BA_REL_ "GenSigTimeoutTime" BU_SG_REL_ ECM_HS SG_ 199 TORSRotDir 250;
BA_REL_ "GenSigTimeoutMsg" BU_SG_REL_ ECM_HS SG_ 199 TORSRotDir 199;
BA_REL_ "GenSigSuprvResp" BU_SG_REL_ ECM_HS SG_ 199 TORSRotDir 1;
BA_REL_ "GenSigTimeoutTime" BU_SG_REL_ TCM_HS SG_ 390 TransFldPmpMtrDrtd 250;
BA_REL_ "GenSigTimeoutMsg" BU_SG_REL_ TCM_HS SG_ 390 TransFldPmpMtrDrtd 390;
BA_REL_ "GenSigSuprvResp" BU_SG_REL_ TCM_HS SG_ 390 TransFldPmpMtrDrtd 1;
BA_REL_ "GenSigTimeoutTime" BU_SG_REL_ TCM_HS SG_ 390 HybGrdBrkgAct 250;
BA_REL_ "GenSigTimeoutMsg" BU_SG_REL_ TCM_HS SG_ 390 HybGrdBrkgAct 390;
BA_REL_ "GenSigSuprvResp" BU_SG_REL_ TCM_HS SG_ 390 HybGrdBrkgAct 1;
BA_REL_ "GenSigTimeoutTime" BU_SG_REL_ ECM_HS SG_ 390 HybCrpCstCrvRq 250;
BA_REL_ "GenSigTimeoutMsg" BU_SG_REL_ ECM_HS SG_ 390 HybCrpCstCrvRq 390;
BA_REL_ "GenSigSuprvResp" BU_SG_REL_ ECM_HS SG_ 390 HybCrpCstCrvRq 1;
BA_REL_ "GenSigTimeoutTime" BU_SG_REL_ ECM_HS SG_ 390 EngActDmpgDsblReq 250;
BA_REL_ "GenSigTimeoutMsg" BU_SG_REL_ ECM_HS SG_ 390 EngActDmpgDsblReq 390;
BA_REL_ "GenSigSuprvResp" BU_SG_REL_ ECM_HS SG_ 390 EngActDmpgDsblReq 1;
BA_REL_ "GenSigTimeoutTime" BU_SG_REL_ ECM_HS SG_ 390 HybRdcdTrqCapMd1Cmnd 250;
BA_REL_ "GenSigTimeoutMsg" BU_SG_REL_ ECM_HS SG_ 390 HybRdcdTrqCapMd1Cmnd 390;
BA_REL_ "GenSigSuprvResp" BU_SG_REL_ ECM_HS SG_ 390 HybRdcdTrqCapMd1Cmnd 1;
BA_REL_ "GenSigTimeoutTime" BU_SG_REL_ EBCM_OBD_HS SG_ 460 SecAxlThrmlCapPRqAt 250;
BA_REL_ "GenSigTimeoutMsg" BU_SG_REL_ EBCM_OBD_HS SG_ 460 SecAxlThrmlCapPRqAt 460;
BA_REL_ "GenSigSuprvResp" BU_SG_REL_ EBCM_OBD_HS SG_ 460 SecAxlThrmlCapPRqAt 1;
BA_REL_ "GenSigTimeoutTime" BU_SG_REL_ EBCM_HS SG_ 460 SecAxlThrmlCapPRqAt 250;
BA_REL_ "GenSigTimeoutMsg" BU_SG_REL_ EBCM_HS SG_ 460 SecAxlThrmlCapPRqAt 460;
BA_REL_ "GenSigSuprvResp" BU_SG_REL_ EBCM_HS SG_ 460 SecAxlThrmlCapPRqAt 1;
BA_REL_ "GenSigTimeoutTime" BU_SG_REL_ EBCM_OBD_HS SG_ 460 SecAxlThrmlCap 250;
BA_REL_ "GenSigTimeoutMsg" BU_SG_REL_ EBCM_OBD_HS SG_ 460 SecAxlThrmlCap 460;
BA_REL_ "GenSigSuprvResp" BU_SG_REL_ EBCM_OBD_HS SG_ 460 SecAxlThrmlCap 1;
BA_REL_ "GenSigTimeoutTime" BU_SG_REL_ EBCM_HS SG_ 460 SecAxlThrmlCap 250;
BA_REL_ "GenSigTimeoutMsg" BU_SG_REL_ EBCM_HS SG_ 460 SecAxlThrmlCap 460;
BA_REL_ "GenSigSuprvResp" BU_SG_REL_ EBCM_HS SG_ 460 SecAxlThrmlCap 1;
BA_REL_ "GenSigTimeoutTime" BU_SG_REL_ ECM_HS SG_ 460 PndgTrnsfrCsRngShft 250;
BA_REL_ "GenSigTimeoutMsg" BU_SG_REL_ ECM_HS SG_ 460 PndgTrnsfrCsRngShft 460;
BA_REL_ "GenSigSuprvResp" BU_SG_REL_ ECM_HS SG_ 460 PndgTrnsfrCsRngShft 1;
BA_REL_ "GenSigTimeoutTime" BU_SG_REL_ ECM_HS SG_ 460 SecAxlEstTrq 250;
BA_REL_ "GenSigTimeoutMsg" BU_SG_REL_ ECM_HS SG_ 460 SecAxlEstTrq 460;
BA_REL_ "GenSigSuprvResp" BU_SG_REL_ ECM_HS SG_ 460 SecAxlEstTrq 1;
BA_REL_ "GenSigTimeoutTime" BU_SG_REL_ ECM_HS SG_ 719 RrVrtlBmpAxlTrqCmdRC 250;
BA_REL_ "GenSigSuprvResp" BU_SG_REL_ ECM_HS SG_ 719 RrVrtlBmpAxlTrqCmdRC 1;
BA_REL_ "GenSigTimeoutTime" BU_SG_REL_ ECM_HS SG_ 719 RrVrtlBmpAxlTrqCmdProtVal 250;
BA_REL_ "GenSigSuprvResp" BU_SG_REL_ ECM_HS SG_ 719 RrVrtlBmpAxlTrqCmdProtVal 1;
BA_REL_ "GenSigTimeoutTime" BU_SG_REL_ ECM_HS SG_ 719 RVBATC_AxlTrqRqstAct 250;
BA_REL_ "GenSigSuprvResp" BU_SG_REL_ ECM_HS SG_ 719 RVBATC_AxlTrqRqstAct 1;
BA_REL_ "GenSigTimeoutTime" BU_SG_REL_ ECM_HS SG_ 719 RVBATC_AxlTrqRqst 250;
BA_REL_ "GenSigSuprvResp" BU_SG_REL_ ECM_HS SG_ 719 RVBATC_AxlTrqRqst 1;
BA_REL_ "GenSigTimeoutTime" BU_SG_REL_ ECM_HS SG_ 717 ColPrSysAxlTrqCmdProtVal 250;
BA_REL_ "GenSigSuprvResp" BU_SG_REL_ ECM_HS SG_ 717 ColPrSysAxlTrqCmdProtVal 1;
BA_REL_ "GenSigTimeoutTime" BU_SG_REL_ ECM_HS SG_ 717 CPSATC_AxlTrqRqstAct 250;
BA_REL_ "GenSigSuprvResp" BU_SG_REL_ ECM_HS SG_ 717 CPSATC_AxlTrqRqstAct 1;
BA_REL_ "GenSigTimeoutTime" BU_SG_REL_ ECM_HS SG_ 717 CPSATC_AxlTrqRqst 250;
BA_REL_ "GenSigSuprvResp" BU_SG_REL_ ECM_HS SG_ 717 CPSATC_AxlTrqRqst 1;
BA_REL_ "GenSigTimeoutTime" BU_SG_REL_ ECM_HS SG_ 717 ColPrSysAxlTrqCmdRC 250;
BA_REL_ "GenSigSuprvResp" BU_SG_REL_ ECM_HS SG_ 717 ColPrSysAxlTrqCmdRC 1;
BA_REL_ "GenSigTimeoutTime" BU_SG_REL_ BCP_HS SG_ 1105 HybImpSnsDsbld 250;
BA_REL_ "GenSigTimeoutMsg" BU_SG_REL_ BCP_HS SG_ 1105 HybImpSnsDsbld 1105;
BA_REL_ "GenSigSuprvResp" BU_SG_REL_ BCP_HS SG_ 1105 HybImpSnsDsbld 1;
BA_REL_ "GenSigTimeoutTime" BU_SG_REL_ BCP_HS SG_ 1105 HybVehHiVltInvDisRqd 250;
BA_REL_ "GenSigTimeoutMsg" BU_SG_REL_ BCP_HS SG_ 1105 HybVehHiVltInvDisRqd 1105;
BA_REL_ "GenSigVDAFailComment" BU_SG_REL_ BCP_HS SG_ 1105 HybVehHiVltInvDisRqd "Airbag Virtual Device Availability";
BA_REL_ "GenSigVDAFailResp" BU_SG_REL_ BCP_HS SG_ 1105 HybVehHiVltInvDisRqd 1;
BA_REL_ "GenSigSuprvResp" BU_SG_REL_ BCP_HS SG_ 1105 HybVehHiVltInvDisRqd 1;
BA_REL_ "GenSigRxStartValue" BU_SG_REL_ ECM_HS SG_ 1005 EnhSvVehTopSpdLmR "$0 - No Action";
BA_REL_ "GenSigTimeoutTime" BU_SG_REL_ EBCM_OBD_HS SG_ 688 StrtrGenSpd 250;
BA_REL_ "GenSigTimeoutMsg" BU_SG_REL_ EBCM_OBD_HS SG_ 688 StrtrGenSpd 688;
BA_REL_ "GenSigSuprvResp" BU_SG_REL_ EBCM_OBD_HS SG_ 688 StrtrGenSpd 1;
BA_REL_ "GenSigTimeoutTime" BU_SG_REL_ EBCM_HS SG_ 688 StrtrGenSpd 250;
BA_REL_ "GenSigTimeoutMsg" BU_SG_REL_ EBCM_HS SG_ 688 StrtrGenSpd 688;
BA_REL_ "GenSigSuprvResp" BU_SG_REL_ EBCM_HS SG_ 688 StrtrGenSpd 1;
BA_REL_ "GenSigTimeoutTime" BU_SG_REL_ ECM_HS SG_ 688 StrtrGenSpd 250;
BA_REL_ "GenSigTimeoutMsg" BU_SG_REL_ ECM_HS SG_ 688 StrtrGenSpd 688;
BA_REL_ "GenSigSuprvResp" BU_SG_REL_ ECM_HS SG_ 688 StrtrGenSpd 1;
BA_REL_ "GenSigTimeoutTime" BU_SG_REL_ ECM_HS SG_ 431 TransVehTopSpdLim 250;
BA_REL_ "GenSigTimeoutMsg" BU_SG_REL_ ECM_HS SG_ 431 TransVehTopSpdLim 431;
BA_REL_ "GenSigSuprvResp" BU_SG_REL_ ECM_HS SG_ 431 TransVehTopSpdLim 1;
BA_REL_ "GenSigTimeoutTime" BU_SG_REL_ ECM_HS SG_ 431 TransMinVoltReq 250;
BA_REL_ "GenSigTimeoutMsg" BU_SG_REL_ ECM_HS SG_ 431 TransMinVoltReq 431;
BA_REL_ "GenSigSuprvResp" BU_SG_REL_ ECM_HS SG_ 431 TransMinVoltReq 1;
BA_REL_ "GenSigTimeoutTime" BU_SG_REL_ ECM_HS SG_ 431 TDslPrtFltrIdlRgtnMdAtv 250;
BA_REL_ "GenSigTimeoutMsg" BU_SG_REL_ ECM_HS SG_ 431 TDslPrtFltrIdlRgtnMdAtv 431;
BA_REL_ "GenSigSuprvResp" BU_SG_REL_ ECM_HS SG_ 431 TDslPrtFltrIdlRgtnMdAtv 1;
BA_REL_ "GenSigTimeoutTime" BU_SG_REL_ ECM_HS SG_ 431 DrvlneTrqStabStat 250;
BA_REL_ "GenSigTimeoutMsg" BU_SG_REL_ ECM_HS SG_ 431 DrvlneTrqStabStat 431;
BA_REL_ "GenSigSuprvResp" BU_SG_REL_ ECM_HS SG_ 431 DrvlneTrqStabStat 1;
BA_REL_ "GenSigTimeoutTime" BU_SG_REL_ ECM_HS SG_ 431 TrnsTrqCnvCltDsrSlp 250;
BA_REL_ "GenSigTimeoutMsg" BU_SG_REL_ ECM_HS SG_ 431 TrnsTrqCnvCltDsrSlp 431;
BA_REL_ "GenSigSuprvResp" BU_SG_REL_ ECM_HS SG_ 431 TrnsTrqCnvCltDsrSlp 1;
BA_REL_ "GenSigTimeoutTime" BU_SG_REL_ ECM_HS SG_ 431 TrnsStWntrMdOvrd 250;
BA_REL_ "GenSigTimeoutMsg" BU_SG_REL_ ECM_HS SG_ 431 TrnsStWntrMdOvrd 431;
BA_REL_ "GenSigSuprvResp" BU_SG_REL_ ECM_HS SG_ 431 TrnsStWntrMdOvrd 1;
BA_REL_ "GenSigTimeoutTime" BU_SG_REL_ ECM_HS SG_ 431 TrnsStTwHaulMdOvrd 250;
BA_REL_ "GenSigTimeoutMsg" BU_SG_REL_ ECM_HS SG_ 431 TrnsStTwHaulMdOvrd 431;
BA_REL_ "GenSigSuprvResp" BU_SG_REL_ ECM_HS SG_ 431 TrnsStTwHaulMdOvrd 1;
BA_REL_ "GenSigTimeoutTime" BU_SG_REL_ ECM_HS SG_ 431 TrnsStSprtMdOvrd 250;
BA_REL_ "GenSigTimeoutMsg" BU_SG_REL_ ECM_HS SG_ 431 TrnsStSprtMdOvrd 431;
BA_REL_ "GenSigSuprvResp" BU_SG_REL_ ECM_HS SG_ 431 TrnsStSprtMdOvrd 1;
BA_REL_ "GenSigTimeoutTime" BU_SG_REL_ ECM_HS SG_ 431 TrnsStEconMdOvrd 250;
BA_REL_ "GenSigTimeoutMsg" BU_SG_REL_ ECM_HS SG_ 431 TrnsStEconMdOvrd 431;
BA_REL_ "GenSigSuprvResp" BU_SG_REL_ ECM_HS SG_ 431 TrnsStEconMdOvrd 1;
BA_REL_ "GenSigTimeoutTime" BU_SG_REL_ ECM_HS SG_ 715 ACCATC_SplREngInpR 250;
BA_REL_ "GenSigSuprvResp" BU_SG_REL_ ECM_HS SG_ 715 ACCATC_SplREngInpR 1;
BA_REL_ "GenSigTimeoutTime" BU_SG_REL_ ECM_HS SG_ 715 ACCATC_DrvAstdGoSt 250;
BA_REL_ "GenSigSuprvResp" BU_SG_REL_ ECM_HS SG_ 715 ACCATC_DrvAstdGoSt 1;
BA_REL_ "GenSigTimeoutTime" BU_SG_REL_ ECM_HS SG_ 715 ACCATC_AxlTrqRq 250;
BA_REL_ "GenSigSuprvResp" BU_SG_REL_ ECM_HS SG_ 715 ACCATC_AxlTrqRq 1;
BA_REL_ "GenSigTimeoutTime" BU_SG_REL_ ECM_HS SG_ 715 ACCATC_ACCTyp 250;
BA_REL_ "GenSigSuprvResp" BU_SG_REL_ ECM_HS SG_ 715 ACCATC_ACCTyp 1;
BA_REL_ "GenSigTimeoutTime" BU_SG_REL_ ECM_HS SG_ 715 ACCATC_ACCAct 250;
BA_REL_ "GenSigSuprvResp" BU_SG_REL_ ECM_HS SG_ 715 ACCATC_ACCAct 1;
BA_REL_ "GenSigTimeoutTime" BU_SG_REL_ ECM_HS SG_ 715 ACCAxlTrqCmdProt 250;
BA_REL_ "GenSigSuprvResp" BU_SG_REL_ ECM_HS SG_ 715 ACCAxlTrqCmdProt 1;
BA_REL_ "GenSigTimeoutTime" BU_SG_REL_ ECM_HS SG_ 715 ACCCmndAlvRlgCnt 250;
BA_REL_ "GenSigSuprvResp" BU_SG_REL_ ECM_HS SG_ 715 ACCCmndAlvRlgCnt 1;
BA_REL_ "GenSigTimeoutTime" BU_SG_REL_ EPS_HS SG_ 320 Ky_IdDevPrgmAuthReq 2500;
BA_REL_ "GenSigTimeoutMsg" BU_SG_REL_ EPS_HS SG_ 320 Ky_IdDevPrgmAuthReq 320;
BA_REL_ "GenSigSuprvResp" BU_SG_REL_ EPS_HS SG_ 320 Ky_IdDevPrgmAuthReq 1;
BA_REL_ "GenSigTimeoutTime" BU_SG_REL_ EPS_HS SG_ 320 ClmnLckStat 2500;
BA_REL_ "GenSigTimeoutMsg" BU_SG_REL_ EPS_HS SG_ 320 ClmnLckStat 320;
BA_REL_ "GenSigSuprvResp" BU_SG_REL_ EPS_HS SG_ 320 ClmnLckStat 1;
BA_REL_ "GenSigTimeoutTime" BU_SG_REL_ EBCM_OBD_HS SG_ 320 TrnSwAct 2500;
BA_REL_ "GenSigTimeoutMsg" BU_SG_REL_ EBCM_OBD_HS SG_ 320 TrnSwAct 320;
BA_REL_ "GenSigSuprvResp" BU_SG_REL_ EBCM_OBD_HS SG_ 320 TrnSwAct 1;
BA_REL_ "GenSigTimeoutTime" BU_SG_REL_ EBCM_HS SG_ 320 TrnSwAct 2500;
BA_REL_ "GenSigTimeoutMsg" BU_SG_REL_ EBCM_HS SG_ 320 TrnSwAct 320;
BA_REL_ "GenSigSuprvResp" BU_SG_REL_ EBCM_HS SG_ 320 TrnSwAct 1;
BA_REL_ "GenSigTimeoutTime" BU_SG_REL_ ECM_HS SG_ 320 TrnSwAct 2500;
BA_REL_ "GenSigTimeoutMsg" BU_SG_REL_ ECM_HS SG_ 320 TrnSwAct 320;
BA_REL_ "GenSigSuprvResp" BU_SG_REL_ ECM_HS SG_ 320 TrnSwAct 1;
BA_REL_ "GenSigRxStartValue" BU_SG_REL_ TCM_HS SG_ 499 PTShftPtrnOvrdAct "False";
BA_REL_ "GenSigRxStartValue" BU_SG_REL_ TCM_HS SG_ 499 PFTrnsTUDSecSwSt "$0 - No Activation";
BA_REL_ "GenSigRxStartValue" BU_SG_REL_ TCM_HS SG_ 499 PFTrnsTUDSwSt "$0 - No Activation";
BA_REL_ "GenSigRxStartValue" BU_SG_REL_ TCM_HS SG_ 499 PFTrnsTUDEnSwSt "$0 - No Activation";
BA_REL_ "GenSigRxStartValue" BU_SG_REL_ TCM_HS SG_ 499 TrnsPFShftPattSw4Act "False";
BA_REL_ "GenSigRxStartValue" BU_SG_REL_ ECM_HS SG_ 499 TrnsPFShftPattSw4Act "False";
BA_REL_ "GenSigRxStartValue" BU_SG_REL_ TCM_HS SG_ 499 TrnsPFShftPattSw3Act "False";
BA_REL_ "GenSigRxStartValue" BU_SG_REL_ ECM_HS SG_ 499 TrnsPFShftPattSw3Act "False";
BA_REL_ "GenSigRxStartValue" BU_SG_REL_ TCM_HS SG_ 499 TrnsPFShftPattSw2Act "False";
BA_REL_ "GenSigRxStartValue" BU_SG_REL_ ECM_HS SG_ 499 TrnsPFShftPattSw2Act "False";
BA_REL_ "GenSigRxStartValue" BU_SG_REL_ TCM_HS SG_ 499 TrnsPFShftPattSw1Act "False";
BA_REL_ "GenSigRxStartValue" BU_SG_REL_ ECM_HS SG_ 499 TrnsPFShftPattSw1Act "False";
BA_REL_ "GenSigTimeoutTime" BU_SG_REL_ BCM_HS SG_ 880 FOAI_VehAhdIndRq 250;
BA_REL_ "GenSigSuprvResp" BU_SG_REL_ BCM_HS SG_ 880 FOAI_VehAhdIndRq 1;
BA_REL_ "GenSigTimeoutTime" BU_SG_REL_ BCM_HS SG_ 880 FOAI_AlrtWrnIndRq 250;
BA_REL_ "GenSigSuprvResp" BU_SG_REL_ BCM_HS SG_ 880 FOAI_AlrtWrnIndRq 1;
BA_REL_ "GenSigTimeoutTime" BU_SG_REL_ BCM_HS SG_ 880 FOAI_AlrtChmIhbRq 250;
BA_REL_ "GenSigSuprvResp" BU_SG_REL_ BCM_HS SG_ 880 FOAI_AlrtChmIhbRq 1;
BA_REL_ "GenSigTimeoutTime" BU_SG_REL_ BCM_HS SG_ 880 FwdClnAlrtPr 250;
BA_REL_ "GenSigSuprvResp" BU_SG_REL_ BCM_HS SG_ 880 FwdClnAlrtPr 1;
BA_REL_ "GenSigTimeoutTime" BU_SG_REL_ BCM_HS SG_ 880 ACCUnavlbleDTWthrIO 250;
BA_REL_ "GenSigSuprvResp" BU_SG_REL_ BCM_HS SG_ 880 ACCUnavlbleDTWthrIO 1;
BA_REL_ "GenSigTimeoutTime" BU_SG_REL_ BCM_HS SG_ 880 DrvThrtlOvrdIO 250;
BA_REL_ "GenSigTimeoutMsg" BU_SG_REL_ BCM_HS SG_ 880 DrvThrtlOvrdIO 880;
BA_REL_ "GenSigSuprvResp" BU_SG_REL_ BCM_HS SG_ 880 DrvThrtlOvrdIO 1;
BA_REL_ "GenSigTimeoutTime" BU_SG_REL_ BCM_HS SG_ 880 ServAdpCrsCtrlIndOn 250;
BA_REL_ "GenSigTimeoutMsg" BU_SG_REL_ BCM_HS SG_ 880 ServAdpCrsCtrlIndOn 880;
BA_REL_ "GenSigSuprvResp" BU_SG_REL_ BCM_HS SG_ 880 ServAdpCrsCtrlIndOn 1;
BA_REL_ "GenSigTimeoutTime" BU_SG_REL_ BCM_HS SG_ 880 ACCHdwayStngIO 250;
BA_REL_ "GenSigTimeoutMsg" BU_SG_REL_ BCM_HS SG_ 880 ACCHdwayStngIO 880;
BA_REL_ "GenSigSuprvResp" BU_SG_REL_ BCM_HS SG_ 880 ACCHdwayStngIO 1;
BA_REL_ "GenSigTimeoutTime" BU_SG_REL_ BCM_HS SG_ 880 ACCHdwyStg 250;
BA_REL_ "GenSigSuprvResp" BU_SG_REL_ BCM_HS SG_ 880 ACCHdwyStg 1;
BA_REL_ "GenSigTimeoutTime" BU_SG_REL_ BCM_HS SG_ 880 ACCSnsClnRqdIO 250;
BA_REL_ "GenSigTimeoutMsg" BU_SG_REL_ BCM_HS SG_ 880 ACCSnsClnRqdIO 880;
BA_REL_ "GenSigSuprvResp" BU_SG_REL_ BCM_HS SG_ 880 ACCSnsClnRqdIO 1;
BA_REL_ "GenSigTimeoutTime" BU_SG_REL_ BCM_HS SG_ 880 ACCTmpUnavlbleIO 250;
BA_REL_ "GenSigTimeoutMsg" BU_SG_REL_ BCM_HS SG_ 880 ACCTmpUnavlbleIO 880;
BA_REL_ "GenSigSuprvResp" BU_SG_REL_ BCM_HS SG_ 880 ACCTmpUnavlbleIO 1;
BA_REL_ "GenSigTimeoutTime" BU_SG_REL_ BCM_HS SG_ 880 ACCDrvrSeltdSpdIO 250;
BA_REL_ "GenSigTimeoutMsg" BU_SG_REL_ BCM_HS SG_ 880 ACCDrvrSeltdSpdIO 880;
BA_REL_ "GenSigSuprvResp" BU_SG_REL_ BCM_HS SG_ 880 ACCDrvrSeltdSpdIO 1;
BA_REL_ "GenSigTimeoutTime" BU_SG_REL_ EBCM_OBD_HS SG_ 880 ACCAct370 250;
BA_REL_ "GenSigTimeoutMsg" BU_SG_REL_ EBCM_OBD_HS SG_ 880 ACCAct370 880;
BA_REL_ "GenSigSuprvResp" BU_SG_REL_ EBCM_OBD_HS SG_ 880 ACCAct370 1;
BA_REL_ "GenSigTimeoutTime" BU_SG_REL_ EBCM_HS SG_ 880 ACCAct370 250;
BA_REL_ "GenSigTimeoutMsg" BU_SG_REL_ EBCM_HS SG_ 880 ACCAct370 880;
BA_REL_ "GenSigSuprvResp" BU_SG_REL_ EBCM_HS SG_ 880 ACCAct370 1;
BA_REL_ "GenSigTimeoutTime" BU_SG_REL_ BCM_HS SG_ 880 ACCAct370 250;
BA_REL_ "GenSigTimeoutMsg" BU_SG_REL_ BCM_HS SG_ 880 ACCAct370 880;
BA_REL_ "GenSigSuprvResp" BU_SG_REL_ BCM_HS SG_ 880 ACCAct370 1;
BA_REL_ "GenSigTimeoutTime" BU_SG_REL_ TCM_HS SG_ 880 ACCAct370 250;
BA_REL_ "GenSigTimeoutMsg" BU_SG_REL_ TCM_HS SG_ 880 ACCAct370 880;
BA_REL_ "GenSigSuprvResp" BU_SG_REL_ TCM_HS SG_ 880 ACCAct370 1;
BA_REL_ "GenSigTimeoutTime" BU_SG_REL_ BCM_HS SG_ 880 ACCDrvrSeltdSpd 250;
BA_REL_ "GenSigSuprvResp" BU_SG_REL_ BCM_HS SG_ 880 ACCDrvrSeltdSpd 1;
BA_REL_ "GenSigTimeoutTime" BU_SG_REL_ ECM_HS SG_ 880 ACCDrvrSeltdSpd 250;
BA_REL_ "GenSigTimeoutMsg" BU_SG_REL_ ECM_HS SG_ 880 ACCDrvrSeltdSpd 880;
BA_REL_ "GenSigSuprvResp" BU_SG_REL_ ECM_HS SG_ 880 ACCDrvrSeltdSpd 1;
BA_REL_ "GenSigTimeoutTime" BU_SG_REL_ EBCM_OBD_HS SG_ 298 Ky_IdDevPr 250;
BA_REL_ "GenSigTimeoutMsg" BU_SG_REL_ EBCM_OBD_HS SG_ 298 Ky_IdDevPr 298;
BA_REL_ "GenSigSuprvResp" BU_SG_REL_ EBCM_OBD_HS SG_ 298 Ky_IdDevPr 1;
BA_REL_ "GenSigTimeoutTime" BU_SG_REL_ EPB_HS SG_ 298 Ky_IdDevPr 250;
BA_REL_ "GenSigTimeoutMsg" BU_SG_REL_ EPB_HS SG_ 298 Ky_IdDevPr 298;
BA_REL_ "GenSigSuprvResp" BU_SG_REL_ EPB_HS SG_ 298 Ky_IdDevPr 1;
BA_REL_ "GenSigTimeoutTime" BU_SG_REL_ EBCM_HS SG_ 298 Ky_IdDevPr 250;
BA_REL_ "GenSigTimeoutMsg" BU_SG_REL_ EBCM_HS SG_ 298 Ky_IdDevPr 298;
BA_REL_ "GenSigSuprvResp" BU_SG_REL_ EBCM_HS SG_ 298 Ky_IdDevPr 1;
BA_REL_ "GenSigTimeoutTime" BU_SG_REL_ EBCM_OBD_HS SG_ 298 CrshAlrtDrvrSlctdType 250;
BA_REL_ "GenSigTimeoutMsg" BU_SG_REL_ EBCM_OBD_HS SG_ 298 CrshAlrtDrvrSlctdType 298;
BA_REL_ "GenSigSuprvResp" BU_SG_REL_ EBCM_OBD_HS SG_ 298 CrshAlrtDrvrSlctdType 1;
BA_REL_ "GenSigTimeoutTime" BU_SG_REL_ EBCM_HS SG_ 298 CrshAlrtDrvrSlctdType 250;
BA_REL_ "GenSigTimeoutMsg" BU_SG_REL_ EBCM_HS SG_ 298 CrshAlrtDrvrSlctdType 298;
BA_REL_ "GenSigSuprvResp" BU_SG_REL_ EBCM_HS SG_ 298 CrshAlrtDrvrSlctdType 1;
BA_REL_ "GenSigTimeoutTime" BU_SG_REL_ EBCM_OBD_HS SG_ 298 PsSbltAtc 250;
BA_REL_ "GenSigTimeoutMsg" BU_SG_REL_ EBCM_OBD_HS SG_ 298 PsSbltAtc 298;
BA_REL_ "GenSigSuprvResp" BU_SG_REL_ EBCM_OBD_HS SG_ 298 PsSbltAtc 1;
BA_REL_ "GenSigTimeoutTime" BU_SG_REL_ EBCM_HS SG_ 298 PsSbltAtc 250;
BA_REL_ "GenSigTimeoutMsg" BU_SG_REL_ EBCM_HS SG_ 298 PsSbltAtc 298;
BA_REL_ "GenSigSuprvResp" BU_SG_REL_ EBCM_HS SG_ 298 PsSbltAtc 1;
BA_REL_ "GenSigTimeoutTime" BU_SG_REL_ ICCM_OBD_HS SG_ 298 TrlrBrkDsplyAct 250;
BA_REL_ "GenSigTimeoutMsg" BU_SG_REL_ ICCM_OBD_HS SG_ 298 TrlrBrkDsplyAct 298;
BA_REL_ "GenSigSuprvResp" BU_SG_REL_ ICCM_OBD_HS SG_ 298 TrlrBrkDsplyAct 1;
BA_REL_ "GenSigTimeoutTime" BU_SG_REL_ ICCM_HS SG_ 298 TrlrBrkDsplyAct 250;
BA_REL_ "GenSigTimeoutMsg" BU_SG_REL_ ICCM_HS SG_ 298 TrlrBrkDsplyAct 298;
BA_REL_ "GenSigSuprvResp" BU_SG_REL_ ICCM_HS SG_ 298 TrlrBrkDsplyAct 1;
BA_REL_ "GenSigTimeoutTime" BU_SG_REL_ EBCM_OBD_HS SG_ 298 DrId 250;
BA_REL_ "GenSigTimeoutMsg" BU_SG_REL_ EBCM_OBD_HS SG_ 298 DrId 298;
BA_REL_ "GenSigSuprvResp" BU_SG_REL_ EBCM_OBD_HS SG_ 298 DrId 1;
BA_REL_ "GenSigTimeoutTime" BU_SG_REL_ EBCM_HS SG_ 298 DrId 250;
BA_REL_ "GenSigTimeoutMsg" BU_SG_REL_ EBCM_HS SG_ 298 DrId 298;
BA_REL_ "GenSigSuprvResp" BU_SG_REL_ EBCM_HS SG_ 298 DrId 1;
BA_REL_ "GenSigTimeoutTime" BU_SG_REL_ ECM_HS SG_ 298 AutoMdSpdLmtCnfrmd 250;
BA_REL_ "GenSigTimeoutMsg" BU_SG_REL_ ECM_HS SG_ 298 AutoMdSpdLmtCnfrmd 298;
BA_REL_ "GenSigSuprvResp" BU_SG_REL_ ECM_HS SG_ 298 AutoMdSpdLmtCnfrmd 1;
BA_REL_ "GenSigTimeoutTime" BU_SG_REL_ EBCM_OBD_HS SG_ 298 TCSysDisSwAtvARC 250;
BA_REL_ "GenSigTimeoutMsg" BU_SG_REL_ EBCM_OBD_HS SG_ 298 TCSysDisSwAtvARC 298;
BA_REL_ "GenSigSuprvResp" BU_SG_REL_ EBCM_OBD_HS SG_ 298 TCSysDisSwAtvARC 1;
BA_REL_ "GenSigTimeoutTime" BU_SG_REL_ EBCM_HS SG_ 298 TCSysDisSwAtvARC 250;
BA_REL_ "GenSigTimeoutMsg" BU_SG_REL_ EBCM_HS SG_ 298 TCSysDisSwAtvARC 298;
BA_REL_ "GenSigSuprvResp" BU_SG_REL_ EBCM_HS SG_ 298 TCSysDisSwAtvARC 1;
BA_REL_ "GenSigTimeoutTime" BU_SG_REL_ ECM_HS SG_ 298 TCSysDisSwAtvARC 250;
BA_REL_ "GenSigTimeoutMsg" BU_SG_REL_ ECM_HS SG_ 298 TCSysDisSwAtvARC 298;
BA_REL_ "GenSigSuprvResp" BU_SG_REL_ ECM_HS SG_ 298 TCSysDisSwAtvARC 1;
BA_REL_ "GenSigTimeoutTime" BU_SG_REL_ ECM_HS SG_ 298 TCSysDisSwAtv_12A 250;
BA_REL_ "GenSigTimeoutMsg" BU_SG_REL_ ECM_HS SG_ 298 TCSysDisSwAtv_12A 298;
BA_REL_ "GenSigSuprvResp" BU_SG_REL_ ECM_HS SG_ 298 TCSysDisSwAtv_12A 1;
BA_REL_ "GenSigTimeoutTime" BU_SG_REL_ EBCM_OBD_HS SG_ 298 DDAjrSwAtv 250;
BA_REL_ "GenSigTimeoutMsg" BU_SG_REL_ EBCM_OBD_HS SG_ 298 DDAjrSwAtv 298;
BA_REL_ "GenSigSuprvResp" BU_SG_REL_ EBCM_OBD_HS SG_ 298 DDAjrSwAtv 1;
BA_REL_ "GenSigTimeoutTime" BU_SG_REL_ EBCM_HS SG_ 298 DDAjrSwAtv 250;
BA_REL_ "GenSigTimeoutMsg" BU_SG_REL_ EBCM_HS SG_ 298 DDAjrSwAtv 298;
BA_REL_ "GenSigSuprvResp" BU_SG_REL_ EBCM_HS SG_ 298 DDAjrSwAtv 1;
BA_REL_ "GenSigTimeoutTime" BU_SG_REL_ EBCM_OBD_HS SG_ 298 TrlrHtchSwAtv 250;
BA_REL_ "GenSigTimeoutMsg" BU_SG_REL_ EBCM_OBD_HS SG_ 298 TrlrHtchSwAtv 298;
BA_REL_ "GenSigSuprvResp" BU_SG_REL_ EBCM_OBD_HS SG_ 298 TrlrHtchSwAtv 1;
BA_REL_ "GenSigTimeoutTime" BU_SG_REL_ EBCM_HS SG_ 298 TrlrHtchSwAtv 250;
BA_REL_ "GenSigTimeoutMsg" BU_SG_REL_ EBCM_HS SG_ 298 TrlrHtchSwAtv 298;
BA_REL_ "GenSigSuprvResp" BU_SG_REL_ EBCM_HS SG_ 298 TrlrHtchSwAtv 1;
BA_REL_ "GenSigTimeoutTime" BU_SG_REL_ ECM_HS SG_ 298 TrlrHtchSwAtv 250;
BA_REL_ "GenSigTimeoutMsg" BU_SG_REL_ ECM_HS SG_ 298 TrlrHtchSwAtv 298;
BA_REL_ "GenSigSuprvResp" BU_SG_REL_ ECM_HS SG_ 298 TrlrHtchSwAtv 1;
BA_REL_ "GenSigTimeoutTime" BU_SG_REL_ ICCM_OBD_HS SG_ 298 BatVlt 250;
BA_REL_ "GenSigTimeoutMsg" BU_SG_REL_ ICCM_OBD_HS SG_ 298 BatVlt 298;
BA_REL_ "GenSigSuprvResp" BU_SG_REL_ ICCM_OBD_HS SG_ 298 BatVlt 1;
BA_REL_ "GenSigTimeoutTime" BU_SG_REL_ ICCM_HS SG_ 298 BatVlt 250;
BA_REL_ "GenSigTimeoutMsg" BU_SG_REL_ ICCM_HS SG_ 298 BatVlt 298;
BA_REL_ "GenSigSuprvResp" BU_SG_REL_ ICCM_HS SG_ 298 BatVlt 1;
BA_REL_ "GenSigTimeoutTime" BU_SG_REL_ BCP_HS SG_ 298 BatVlt 250;
BA_REL_ "GenSigTimeoutMsg" BU_SG_REL_ BCP_HS SG_ 298 BatVlt 298;
BA_REL_ "GenSigSuprvResp" BU_SG_REL_ BCP_HS SG_ 298 BatVlt 1;
BA_REL_ "GenSigTimeoutTime" BU_SG_REL_ TCM_HS SG_ 298 BatVlt 250;
BA_REL_ "GenSigTimeoutMsg" BU_SG_REL_ TCM_HS SG_ 298 BatVlt 298;
BA_REL_ "GenSigSuprvResp" BU_SG_REL_ TCM_HS SG_ 298 BatVlt 1;
BA_REL_ "GenSigTimeoutTime" BU_SG_REL_ ECM_HS SG_ 298 BatVlt 250;
BA_REL_ "GenSigTimeoutMsg" BU_SG_REL_ ECM_HS SG_ 298 BatVlt 298;
BA_REL_ "GenSigSuprvResp" BU_SG_REL_ ECM_HS SG_ 298 BatVlt 1;
BA_REL_ "GenSigTimeoutTime" BU_SG_REL_ EPB_HS SG_ 298 DrSbltAtc 250;
BA_REL_ "GenSigTimeoutMsg" BU_SG_REL_ EPB_HS SG_ 298 DrSbltAtc 298;
BA_REL_ "GenSigSuprvResp" BU_SG_REL_ EPB_HS SG_ 298 DrSbltAtc 1;
BA_REL_ "GenSigTimeoutTime" BU_SG_REL_ CGM_HS SG_ 485 StrWhlAngSenCalStat 250;
BA_REL_ "GenSigTimeoutMsg" BU_SG_REL_ CGM_HS SG_ 485 StrWhlAngSenCalStat 485;
BA_REL_ "GenSigSuprvResp" BU_SG_REL_ CGM_HS SG_ 485 StrWhlAngSenCalStat 1;
BA_REL_ "GenSigTimeoutTime" BU_SG_REL_ ECM_HS SG_ 485 StrWhlAngSenCalStat 250;
BA_REL_ "GenSigTimeoutMsg" BU_SG_REL_ ECM_HS SG_ 485 StrWhlAngSenCalStat 485;
BA_REL_ "GenSigSuprvResp" BU_SG_REL_ ECM_HS SG_ 485 StrWhlAngSenCalStat 1;
BA_REL_ "GenSigTimeoutTime" BU_SG_REL_ CGM_HS SG_ 485 StrWhAngGrd 250;
BA_REL_ "GenSigTimeoutMsg" BU_SG_REL_ CGM_HS SG_ 485 StrWhAngGrd 485;
BA_REL_ "GenSigSuprvResp" BU_SG_REL_ CGM_HS SG_ 485 StrWhAngGrd 1;
BA_REL_ "GenSigTimeoutTime" BU_SG_REL_ CGM_HS SG_ 485 StrWhAng 250;
BA_REL_ "GenSigTimeoutMsg" BU_SG_REL_ CGM_HS SG_ 485 StrWhAng 485;
BA_REL_ "GenSigSuprvResp" BU_SG_REL_ CGM_HS SG_ 485 StrWhAng 1;
BA_REL_ "GenSigTimeoutTime" BU_SG_REL_ ICCM_OBD_HS SG_ 485 StrWhAng 250;
BA_REL_ "GenSigTimeoutMsg" BU_SG_REL_ ICCM_OBD_HS SG_ 485 StrWhAng 485;
BA_REL_ "GenSigSuprvResp" BU_SG_REL_ ICCM_OBD_HS SG_ 485 StrWhAng 1;
BA_REL_ "GenSigTimeoutTime" BU_SG_REL_ ICCM_HS SG_ 485 StrWhAng 250;
BA_REL_ "GenSigTimeoutMsg" BU_SG_REL_ ICCM_HS SG_ 485 StrWhAng 485;
BA_REL_ "GenSigSuprvResp" BU_SG_REL_ ICCM_HS SG_ 485 StrWhAng 1;
BA_REL_ "GenSigTimeoutTime" BU_SG_REL_ HMIM_HS SG_ 485 StrWhAng 250;
BA_REL_ "GenSigTimeoutMsg" BU_SG_REL_ HMIM_HS SG_ 485 StrWhAng 485;
BA_REL_ "GenSigSuprvResp" BU_SG_REL_ HMIM_HS SG_ 485 StrWhAng 1;
BA_REL_ "GenSigTimeoutTime" BU_SG_REL_ EPS_HS SG_ 485 StrWhAng 250;
BA_REL_ "GenSigTimeoutMsg" BU_SG_REL_ EPS_HS SG_ 485 StrWhAng 485;
BA_REL_ "GenSigSuprvResp" BU_SG_REL_ EPS_HS SG_ 485 StrWhAng 1;
BA_REL_ "GenSigTimeoutTime" BU_SG_REL_ TCCM_HS SG_ 485 StrWhAng 250;
BA_REL_ "GenSigTimeoutMsg" BU_SG_REL_ TCCM_HS SG_ 485 StrWhAng 485;
BA_REL_ "GenSigSuprvResp" BU_SG_REL_ TCCM_HS SG_ 485 StrWhAng 1;
BA_REL_ "GenSigTimeoutTime" BU_SG_REL_ BCM_HS SG_ 485 StrWhAng 250;
BA_REL_ "GenSigTimeoutMsg" BU_SG_REL_ BCM_HS SG_ 485 StrWhAng 485;
BA_REL_ "GenSigVBitResp" BU_SG_REL_ BCM_HS SG_ 485 StrWhAng 1;
BA_REL_ "GenSigSuprvResp" BU_SG_REL_ BCM_HS SG_ 485 StrWhAng 1;
BA_REL_ "GenSigTimeoutTime" BU_SG_REL_ ECM_HS SG_ 485 StrWhAng 250;
BA_REL_ "GenSigTimeoutMsg" BU_SG_REL_ ECM_HS SG_ 485 StrWhAng 485;
BA_REL_ "GenSigSuprvResp" BU_SG_REL_ ECM_HS SG_ 485 StrWhAng 1;
BA_REL_ "GenSigTimeoutTime" BU_SG_REL_ CGM_HS SG_ 485 StrWhlAngSenTyp 250;
BA_REL_ "GenSigTimeoutMsg" BU_SG_REL_ CGM_HS SG_ 485 StrWhlAngSenTyp 485;
BA_REL_ "GenSigSuprvResp" BU_SG_REL_ CGM_HS SG_ 485 StrWhlAngSenTyp 1;
BA_REL_ "GenSigTimeoutTime" BU_SG_REL_ ECM_HS SG_ 491 ExhPrsRgVlv2Pos 31;
BA_REL_ "GenSigTimeoutMsg" BU_SG_REL_ ECM_HS SG_ 491 ExhPrsRgVlv2Pos 491;
BA_REL_ "GenSigSuprvResp" BU_SG_REL_ ECM_HS SG_ 491 ExhPrsRgVlv2Pos 1;
BA_REL_ "GenSigTimeoutTime" BU_SG_REL_ ECM_HS SG_ 491 ExhPrsRgVlvPosV 30;
BA_REL_ "GenSigTimeoutMsg" BU_SG_REL_ ECM_HS SG_ 491 ExhPrsRgVlvPosV 491;
BA_REL_ "GenSigSuprvResp" BU_SG_REL_ ECM_HS SG_ 491 ExhPrsRgVlvPosV 1;
BA_REL_ "GenSigTimeoutTime" BU_SG_REL_ ECM_HS SG_ 491 ExhPrsRgVlvPos 30;
BA_REL_ "GenSigTimeoutMsg" BU_SG_REL_ ECM_HS SG_ 491 ExhPrsRgVlvPos 491;
BA_REL_ "GenSigSuprvResp" BU_SG_REL_ ECM_HS SG_ 491 ExhPrsRgVlvPos 1;
BA_REL_ "GenSigTimeoutTime" BU_SG_REL_ ECM_HS SG_ 491 FuelSysEstPressDlvrd 30;
BA_REL_ "GenSigTimeoutMsg" BU_SG_REL_ ECM_HS SG_ 491 FuelSysEstPressDlvrd 491;
BA_REL_ "GenSigSuprvResp" BU_SG_REL_ ECM_HS SG_ 491 FuelSysEstPressDlvrd 1;
BA_REL_ "GenSigTimeoutTime" BU_SG_REL_ ECM_HS SG_ 491 FuelSysEstPressDlvrdV 30;
BA_REL_ "GenSigTimeoutMsg" BU_SG_REL_ ECM_HS SG_ 491 FuelSysEstPressDlvrdV 491;
BA_REL_ "GenSigSuprvResp" BU_SG_REL_ ECM_HS SG_ 491 FuelSysEstPressDlvrdV 1;
BA_REL_ "GenSigTimeoutTime" BU_SG_REL_ ECM_HS SG_ 409 TTRLT_TorqReqVal 31;
BA_REL_ "GenSigTimeoutMsg" BU_SG_REL_ ECM_HS SG_ 409 TTRLT_TorqReqVal 409;
BA_REL_ "GenSigSuprvResp" BU_SG_REL_ ECM_HS SG_ 409 TTRLT_TorqReqVal 1;
BA_REL_ "GenSigTimeoutTime" BU_SG_REL_ ECM_HS SG_ 409 TTRLT_TqRdnRlznSgg 31;
BA_REL_ "GenSigTimeoutMsg" BU_SG_REL_ ECM_HS SG_ 409 TTRLT_TqRdnRlznSgg 409;
BA_REL_ "GenSigSuprvResp" BU_SG_REL_ ECM_HS SG_ 409 TTRLT_TqRdnRlznSgg 1;
BA_REL_ "GenSigTimeoutTime" BU_SG_REL_ ECM_HS SG_ 409 TTRLT_TorqInvntnTyp 31;
BA_REL_ "GenSigTimeoutMsg" BU_SG_REL_ ECM_HS SG_ 409 TTRLT_TorqInvntnTyp 409;
BA_REL_ "GenSigSuprvResp" BU_SG_REL_ ECM_HS SG_ 409 TTRLT_TorqInvntnTyp 1;
BA_REL_ "GenSigTimeoutTime" BU_SG_REL_ ECM_HS SG_ 409 TTRST_TorqReqVal 31;
BA_REL_ "GenSigTimeoutMsg" BU_SG_REL_ ECM_HS SG_ 409 TTRST_TorqReqVal 409;
BA_REL_ "GenSigSuprvResp" BU_SG_REL_ ECM_HS SG_ 409 TTRST_TorqReqVal 1;
BA_REL_ "GenSigTimeoutTime" BU_SG_REL_ ECM_HS SG_ 409 TTRST_TorqInvntnTyp 31;
BA_REL_ "GenSigTimeoutMsg" BU_SG_REL_ ECM_HS SG_ 409 TTRST_TorqInvntnTyp 409;
BA_REL_ "GenSigSuprvResp" BU_SG_REL_ ECM_HS SG_ 409 TTRST_TorqInvntnTyp 1;
BA_REL_ "GenSigTimeoutTime" BU_SG_REL_ ECM_HS SG_ 413 TrnsRtoCntlSysFlt 62;
BA_REL_ "GenSigTimeoutMsg" BU_SG_REL_ ECM_HS SG_ 413 TrnsRtoCntlSysFlt 413;
BA_REL_ "GenSigSuprvResp" BU_SG_REL_ ECM_HS SG_ 413 TrnsRtoCntlSysFlt 1;
BA_REL_ "GenSigTimeoutTime" BU_SG_REL_ CGM_HS SG_ 413 TrnGrRat 250;
BA_REL_ "GenSigTimeoutMsg" BU_SG_REL_ CGM_HS SG_ 413 TrnGrRat 413;
BA_REL_ "GenSigSuprvResp" BU_SG_REL_ CGM_HS SG_ 413 TrnGrRat 1;
BA_REL_ "GenSigTimeoutTime" BU_SG_REL_ ECM_HS SG_ 413 TESR_EngSpdCntlRsp 62;
BA_REL_ "GenSigTimeoutMsg" BU_SG_REL_ ECM_HS SG_ 413 TESR_EngSpdCntlRsp 413;
BA_REL_ "GenSigSuprvResp" BU_SG_REL_ ECM_HS SG_ 413 TESR_EngSpdCntlRsp 1;
BA_REL_ "GenSigTimeoutTime" BU_SG_REL_ ECM_HS SG_ 413 TESR_EngSpdRqVal 62;
BA_REL_ "GenSigTimeoutMsg" BU_SG_REL_ ECM_HS SG_ 413 TESR_EngSpdRqVal 413;
BA_REL_ "GenSigSuprvResp" BU_SG_REL_ ECM_HS SG_ 413 TESR_EngSpdRqVal 1;
BA_REL_ "GenSigTimeoutTime" BU_SG_REL_ ECM_HS SG_ 413 TESR_EngSpdIntTyp 62;
BA_REL_ "GenSigTimeoutMsg" BU_SG_REL_ ECM_HS SG_ 413 TESR_EngSpdIntTyp 413;
BA_REL_ "GenSigSuprvResp" BU_SG_REL_ ECM_HS SG_ 413 TESR_EngSpdIntTyp 1;
BA_REL_ "GenSigTimeoutTime" BU_SG_REL_ ECM_HS SG_ 413 TrnsGrgShftAct 62;
BA_REL_ "GenSigTimeoutMsg" BU_SG_REL_ ECM_HS SG_ 413 TrnsGrgShftAct 413;
BA_REL_ "GenSigSuprvResp" BU_SG_REL_ ECM_HS SG_ 413 TrnsGrgShftAct 1;
VAL_ 424 TransClch3FlAch 1 "true" 0 "false" ;
VAL_ 424 TransClch2FlAch 1 "true" 0 "false" ;
VAL_ 423 TrnsPTSysShtdwnRq 1 "true" 0 "false" ;
VAL_ 423 TransClch1FlAch 1 "true" 0 "false" ;
VAL_ 423 TransHydrlcDfltgAct 1 "true" 0 "false" ;
VAL_ 423 TCFS_Cltch5FltStat 0 "None" 1 "Failed Off Fault Active" 2 "Failed On Fault Active" 3 "Failed Off Fault Pending" 4 "Failed On Fault Pending" 5 "Mismatch" ;
VAL_ 423 TCFS_Cltch4FltStat 0 "None" 1 "Failed Off Fault Active" 2 "Failed On Fault Active" 3 "Failed Off Fault Pending" 4 "Failed On Fault Pending" 5 "Mismatch" ;
VAL_ 423 TCFS_Cltch3FltStat 0 "None" 1 "Failed Off Fault Active" 2 "Failed On Fault Active" 3 "Failed Off Fault Pending" 4 "Failed On Fault Pending" 5 "Mismatch" ;
VAL_ 423 TCFS_Cltch2FltStat 0 "None" 1 "Failed Off Fault Active" 2 "Failed On Fault Active" 3 "Failed Off Fault Pending" 4 "Failed On Fault Pending" 5 "Mismatch" ;
VAL_ 423 TCFS_Cltch1FltStat 0 "None" 1 "Failed Off Fault Active" 2 "Failed On Fault Active" 3 "Failed Off Fault Pending" 4 "Failed On Fault Pending" 5 "Mismatch" ;
VAL_ 423 TCAS_Cltch5AvlbltyStat 0 "Unavailable" 1 "Ready" 2 "Allowed" 3 "Unused and Reserved" ;
VAL_ 423 TCAS_Cltch4AvlbltyStat 0 "Unavailable" 1 "Ready" 2 "Allowed" 3 "Unused and Reserved" ;
VAL_ 423 TCAS_Cltch3AvlbltyStat 0 "Unavailable" 1 "Ready" 2 "Allowed" 3 "Unused and Reserved" ;
VAL_ 423 TCAS_Cltch2AvlbltyStat 0 "Unavailable" 1 "Ready" 2 "Allowed" 3 "Unused and Reserved" ;
VAL_ 423 TCAS_Cltch1AvlbltyStat 0 "Unavailable" 1 "Ready" 2 "Allowed" 3 "Unused and Reserved" ;
VAL_ 1919 DTCI_DTCFaultType_77F 3 "Type C" 2 "Type B" 1 "Type A" 0 "Not Supported" ;
VAL_ 1919 DTCI_CodeSupported_77F 1 "true" 0 "false" ;
VAL_ 1919 DTCI_CurrentStatus_77F 1 "true" 0 "false" ;
VAL_ 1919 DTCI_TstNPsdCdClrdSt_77F 1 "true" 0 "false" ;
VAL_ 1919 DTCI_TstFldCdClrdStat_77F 1 "true" 0 "false" ;
VAL_ 1919 DTCI_HistStat_77F 1 "true" 0 "false" ;
VAL_ 1919 DTCI_TstNPsdPwrUpSt_77F 1 "true" 0 "false" ;
VAL_ 1919 DTCI_TstFldPwrUpSt_77F 1 "true" 0 "false" ;
VAL_ 1919 DTCI_WrnIndRqdSt_77F 1 "true" 0 "false" ;
VAL_ 1919 DTCI_DTCTriggered_77F 1 "true" 0 "false" ;
VAL_ 1919 DTCIUnused7_77F 1 "true" 0 "false" ;
VAL_ 1919 DTCIUnused6_77F 1 "true" 0 "false" ;
VAL_ 1919 DTCIUnused5_77F 1 "true" 0 "false" ;
VAL_ 1919 DTCIUnused4_77F 1 "true" 0 "false" ;
VAL_ 1919 DTCIUnused3_77F 1 "true" 0 "false" ;
VAL_ 1919 DTCIUnused2_77F 1 "true" 0 "false" ;
VAL_ 1919 DTCIUnused1_77F 1 "true" 0 "false" ;
VAL_ 1273 BrkSyCtl1EmsRldMlfAct 1 "true" 0 "false" ;
VAL_ 1273 BSC1ERDTC_SysDes 15 "U3-Network Codes Reserved" 14 "U2-Network Codes Reserved" 13 "U1-Network Codes MFG Controlled" 12 "U0-Network Codes SAE Controlled" 11 "B3-Body Codes Reserved" 10 "B2-Body Codes Reserved" 9 "B1-Body Codes MFG Controlled" 8 "B0-Body Codes SAE Controlled" 7 "C3-Chassis Codes Reserved" 6 "C2-Chassis Codes Reserved" 5 "C1-Chassis Codes MFG Controlled" 4 "C0-Chassis Codes SAE Controlled" 3 "P3-Powertrain Codes Reserved" 2 "P2-Powertrain Codes Reserved" 1 "P1-Powertrain Codes MFG Controlled" 0 "P0-Powertrain Codes SAE Controlled" ;
VAL_ 753 EBCMDS5_DTCStatus 0 "Not Supported" 1 "Critically Disabled" 2 "No Status to Report" 3 "Diagnostic Passed" 4 "Diagnostic Failed" ;
VAL_ 753 EBCMDS4_DTCStatus 0 "Not Supported" 1 "Critically Disabled" 2 "No Status to Report" 3 "Diagnostic Passed" 4 "Diagnostic Failed" ;
VAL_ 753 EBCMDS3_DTCStatus 0 "Not Supported" 1 "Critically Disabled" 2 "No Status to Report" 3 "Diagnostic Passed" 4 "Diagnostic Failed" ;
VAL_ 753 EBCMDS2_DTCStatus 0 "Not Supported" 1 "Critically Disabled" 2 "No Status to Report" 3 "Diagnostic Passed" 4 "Diagnostic Failed" ;
VAL_ 753 EBCMDS1_DTCStatus 0 "Not Supported" 1 "Critically Disabled" 2 "No Status to Report" 3 "Diagnostic Passed" 4 "Diagnostic Failed" ;
VAL_ 407 TransRatioV 1 "Invalid" 0 "Valid" ;
VAL_ 407 TrnsOvrallActTorqRatioV 1 "Invalid" 0 "Valid" ;
VAL_ 189 TrnsInpMinSpdRq 0 "Unused and Reserved" 1 "Speed Point 1" 2 "Speed Point 2" 3 "Speed Point 3" 4 "Speed Point 4" 5 "Speed Point 5" 6 "Speed Point 6" 7 "Speed Point 7" 8 "Speed Point 8" 9 "Speed Point 9" 10 "Speed Point 10" 11 "Speed Point 11" 12 "Speed Point 12" 13 "Speed Point 13" 14 "Speed Point 14" 15 "Speed Point 15" ;
VAL_ 189 HybDisengCruzCmnd 1 "true" 0 "false" ;
VAL_ 189 TrnsRtoCntlSysFlt 1 "true" 0 "false" ;
VAL_ 1221 SpdLmtVsnFsdSpdUnt 0 "km/h" 1 "mph" ;
VAL_ 1221 SpdLmtVnFsSpdNwDet 1 "true" 0 "false" ;
VAL_ 1221 SpdLmtVsnFsdSpdM 0 "Don't Use Data" 1 "Use Data" ;
VAL_ 1243 CSERDTC_SysDes 0 "P0-Powertrain Codes SAE Controlled" 1 "P1-Powertrain Codes MFG Controlled" 2 "P2-Powertrain Codes Reserved" 3 "P3-Powertrain Codes Reserved" 4 "C0-Chassis Codes SAE Controlled" 5 "C1-Chassis Codes MFG Controlled" 6 "C2-Chassis Codes Reserved" 7 "C3-Chassis Codes Reserved" 8 "B0-Body Codes SAE Controlled" 9 "B1-Body Codes MFG Controlled" 10 "B2-Body Codes Reserved" 11 "B3-Body Codes Reserved" 12 "U0-Network Codes SAE Controlled" 13 "U1-Network Codes MFG Controlled" 14 "U2- Network Codes Reserved" 15 "U3-Network Codes Reserved" ;
VAL_ 1243 ChsSysEmmRelMalfAct 1 "true" 0 "false" ;
VAL_ 1239 BattSOXStat 1 "Use SOC,SOH, & SOF" 0 "Don't Use SOC,SOH, & SOF" ;
VAL_ 1239 BattTempV 1 "Invalid" 0 "Valid" ;
VAL_ 508 CSTBATS_TrqVlV 1 "Invalid" 0 "Valid" ;
VAL_ 422 TrnsAuxPrsDisOvrrdOn 1 "true" 0 "false" ;
VAL_ 422 TransEngShtdwnRqd 1 "true" 0 "false" ;
VAL_ 422 TransCrksftTqLoadV 1 "Invalid" 0 "Valid" ;
VAL_ 422 TrStPTGrdBrkDsMdOvr 3 "Unused and Reserved" 2 "To Grade Braking Disable" 1 "To Not Grade Braking Disable" 0 "No Override" ;
VAL_ 422 TrnsHybEngSrtStpOvrd 2 "Engine Off" 1 "Engine On" 0 "No Override" ;
VAL_ 971 BatVltHiResV 1 "Invalid" 0 "Valid" ;
VAL_ 971 BCHR_BattCrntRwVlMu 3 "Multiplier Factor 256" 2 "Multiplier Factor 64" 1 "Multiplier Factor 8" 0 "Multiplier Factor 1" ;
VAL_ 971 BCHR_BattCrntRwValV 1 "Invalid" 0 "Valid" ;
VAL_ 209 ChsBrkPdlPsERltdV 1 "Invalid" 0 "Valid" ;
VAL_ 454 CSPATR_TrqIntrvnTyp 3 "Minimum and Maximum Limit" 2 "Minimum Limit" 1 "Maximum Limit" 0 "No Intervention" ;
VAL_ 454 CSPATR_TrqRqTyp 0 "Absolute Torque Request" ;
VAL_ 454 ChsSysAxlTqRqRspTyp 4 "Braking Torque Request" 3 "Automatic Actuator Selection" 2 "Maximum Range Request" 1 "Pleasability Limited Request" 0 "Inactive" ;
VAL_ 1189 TAFR_AirFlwReqTyp 0 "No Request" 1 "Low Priority Minimum Request" 2 "High Priority Minimum Request" 3 "Reserved" ;
VAL_ 421 AccPwrMdlHiVltInpCrntV 1 "Invalid" 0 "Valid" ;
VAL_ 421 HybAuxTransPresCmndOn 1 "true" 0 "false" ;
VAL_ 421 HTGR_ReqVal 0 "No Action" 1 "First Gear" 2 "Second Gear" 3 "Third Gear" 4 "Fourth Gear" 5 "Fifth Gear" 6 "Sixth Gear" 7 "Seventh Gear" 8 "Eighth Gear" ;
VAL_ 421 HTGR_ReqTyp 0 "No Request" 1 "Max Gear Request" 2 "Min Gear Request" 3 "Hold Gear" ;
VAL_ 421 HTGR_ReqPrty 0 "Desired" 1 "Recommended" 2 "Strongly Recommended" 3 "Mandatory" ;
VAL_ 421 HTCCR_ReqVal 0 "No Request" 1 "Immediate Off" 2 "Ramp Off A" 3 "Ramp Off B" 4 "Apply" ;
VAL_ 421 HTCCR_ReqPrty 0 "Desired" 1 "Recommended" 2 "Strongly Recommended" 3 "Mandatory" ;
VAL_ 421 TrnsAuxPmpAct 1 "true" 0 "false" ;
VAL_ 421 HybEconBhvAlwd 1 "true" 0 "false" ;
VAL_ 421 HybTwHaulBhvAlwd 1 "true" 0 "false" ;
VAL_ 421 HybSnsBrkPdlPosV 1 "Invalid" 0 "Valid" ;
VAL_ 456 PTESR_EngSpdCntlRs 3 "Stability Optimized Cond 2" 2 "Stability Optimized Cond 1" 1 "Transient Optimized" 0 "No Suggestion" ;
VAL_ 456 PTESR_EngSpdIntTyp 1 "Engine Speed Max Limit" 0 "No Intervention" ;
VAL_ 456 PTTR_TrqRedRlzSugg 1 "Transient Optimized" 0 "No Suggestion" ;
VAL_ 456 PTTR_TrqInvTyp 1 "Maximum Limit" 0 "No Intervention" ;
VAL_ 393 TIDCTR_TrqIntvTyp 3 "Reserved" 2 "Minimum Limit" 1 "Maximum Limit" 0 "No Request" ;
VAL_ 393 TIDCTR_TrqRespTyp 3 "Automatic Actuator Selection" 2 "Maximum Range" 1 "Pleasability Limited" 0 "Inactive" ;
VAL_ 393 TPCTR_TrqIntrvnTyp 3 "Unused and Reserved" 2 "Minimum Limit" 1 "Maximum Limit" 0 "No Request" ;
VAL_ 199 TORSValidity 1 "Invalid" 0 "Valid" ;
VAL_ 199 TORSRstOcrd 1 "true" 0 "false" ;
VAL_ 199 TORSLstTransType 3 "Undefined" 2 "Falling Transition" 1 "Rising Transition" 0 "Single Edge Sensor" ;
VAL_ 199 TORSRotDir 3 "Undefined" 2 "Reverse" 1 "Forward" 0 "Unknown" ;
VAL_ 390 RdHVInvRatVltV 1 "Invalid" 0 "Valid" ;
VAL_ 390 RdPTHVCntrReq 0 "Undetermined" 1 "Close Allowed" 2 "Request Open" ;
VAL_ 390 TransFldPmpMtrDrtd 1 "true" 0 "false" ;
VAL_ 390 EstMtrPwrLossV 1 "Invalid" 0 "Valid" ;
VAL_ 390 HybGrdBrkgAct 1 "true" 0 "false" ;
VAL_ 390 HybCrpCstCrvRq 7 "Creep Coast Curve 7" 6 "Creep Coast Curve 6" 5 "Creep Coast Curve 5" 4 "Creep Coast Curve 4" 3 "Creep Coast Curve 3" 2 "Creep Coast Curve 2" 1 "Creep Coast Curve 1" 0 "Creep Coast Curve 0" ;
VAL_ 390 EngActDmpgDsblReq 1 "true" 0 "false" ;
VAL_ 390 HybRdcdTrqCapMd1Cmnd 1 "true" 0 "false" ;
VAL_ 390 HybExtndDcFuelCORq 1 "true" 0 "false" ;
VAL_ 390 HybCmmFailRdPwrCmd 1 "true" 0 "false" ;
VAL_ 390 HybACCompRq 3 "Reserved" 2 "Disengage" 1 "Engage" 0 "No Action" ;
VAL_ 390 HESSI_EngStrtTyp 9 "Compression Test" 8 "Auto Start Generic" 7 "Auto Start Aggressive" 6 "Auto Start Normal" 5 "Auto Start Smooth" 4 "Key Start Generic" 3 "Key Start Low Power B" 2 "Key Start Low Power" 1 "Key Start Normal" 0 "No Start" ;
VAL_ 390 HESSI_EngStrtStpMd 7 "Start Failed" 6 "Stop Pending" 5 "Disable Fuel" 4 "Producing Torque" 3 "Enable Fuel" 2 "Start Pending" 1 "Immediate Stop" 0 "Stop" ;
VAL_ 390 HybCrnkAbrtd 1 "true" 0 "false" ;
VAL_ 390 CnvntlEngStrtEnbld 1 "true" 0 "false" ;
VAL_ 390 HybDFCOReq 1 "DFCO Requested" 0 "DFCO Not Requested" ;
VAL_ 460 SecAxlThrmlCapV 1 "Invalid" 0 "Valid" ;
VAL_ 460 SecAxlThrmlCapPRqAt 1 "true" 0 "false" ;
VAL_ 460 SAMDVLAtv 1 "true" 0 "false" ;
VAL_ 460 SecAxlCtrlMod 1 "External" 0 "Internal" ;
VAL_ 460 PndgTrnsfrCsRngShft 3 "Shift Out of Neutral Range" 2 "Shift Out of Low Range" 1 "Shift Out of High Range" 0 "None" ;
VAL_ 460 SecAxlEstTrqV 1 "Invalid" 0 "Valid" ;
VAL_ 460 PTTrnsfrCseMd 3 "Neutral" 2 "4 Wheel Drive Low" 1 "4 Wheel Drive High" 0 "2 Wheel Drive High" ;
VAL_ 460 SecAxlStat 3 "Permanently Failed" 2 "Temporary Limited" 1 "Temporary Inhibit" 0 "Normal" ;
VAL_ 719 RVBATC_AxlTrqRqstAct 1 "true" 0 "false" ;
VAL_ 717 CPSATC_AxlTrqRqstAct 1 "true" 0 "false" ;
VAL_ 1105 HybImpSnsDsbld 1 "true" 0 "false" ;
VAL_ 1105 JmpStrtReq 1 "true" 0 "false" ;
VAL_ 1105 HybVehHiVltInvDisRqd 1 "true" 0 "false" ;
VAL_ 1105 NESSRoSevSt 1 "true" 0 "false" ;
VAL_ 1105 NESSRiSiSevSt 1 "true" 0 "false" ;
VAL_ 1105 NESSReImpSevSt 1 "true" 0 "false" ;
VAL_ 1105 NESSLeSiSevSt 1 "true" 0 "false" ;
VAL_ 1105 NESSFrImpSt2SevSt 1 "true" 0 "false" ;
VAL_ 1105 NESSFrImpSt1SevSt 1 "true" 0 "false" ;
VAL_ 1105 NESSFrImpPreSevSt 1 "true" 0 "false" ;
VAL_ 1005 EnhSvVehTopSpdLmR 2 "Inactive" 1 "Active" 0 "No Action" ;
VAL_ 688 StrtrGenSpdV 1 "Invalid" 0 "Valid" ;
VAL_ 431 TrnsInpCltchStatV 1 "Invalid" 0 "Valid" ;
VAL_ 431 TransCrnkPermsnStatV 1 "Invalid" 0 "Valid" ;
VAL_ 431 TDslPrtFltrIdlRgtnMdAtv 1 "true" 0 "false" ;
VAL_ 431 DrvlneTrqStabStat 3 "Level 3" 0 "Normal Stability" 1 "Level 1" 2 "Level 2" ;
VAL_ 431 TrnsTrqCnvCltCmdMdF 1 "true" 0 "false" ;
VAL_ 431 AutoTransGrSftDirectFl 1 "true" 0 "false" ;
VAL_ 431 AutoTransGrSftDirect 2 "Downshift in Progress" 1 "Upshift in Progress" 0 "No Shift in Progress" ;
VAL_ 431 TrnsTrqCnvCltCmndMd 7 "Not Supported" 3 "Locked" 2 "Controlled Slip" 1 "Transitioning" 0 "Unlocked" ;
VAL_ 431 TrnsStWntrMdOvrd 2 "Override To Winter" 1 "Override To Not Winter" 0 "No Override" ;
VAL_ 431 TrnsStTwHaulMdOvrd 2 "Override To Tow Haul" 1 "Override To Not Tow Haul" 0 "No Override" ;
VAL_ 431 TrnsStSprtMdOvrd 2 "Override To Sport" 1 "Override To Not Sport" 0 "No Override" ;
VAL_ 431 TrnsStEconMdOvrd 2 "Override To Economy" 1 "Override To Not Economy" 0 "No Override" ;
VAL_ 431 TrnsInpCltchStat 0 "Disengaged" 1 "Engaging" 2 "Engaged" 3 "Disengaging" 4 "Controlled Slip" 5 "Reserved" 6 "Reserved" 7 "Not Supported" ;
VAL_ 431 TrnsAntcptdCrpTrqRRnV 1 "Invalid" 0 "Valid" ;
VAL_ 431 TrnCltAdpAtv 1 "true" 0 "false" ;
VAL_ 431 TransCrnkPermsnStat 0 "Crank Not Permitted" 1 "Crank Permitted" ;
VAL_ 431 WrmUpShftPtrn 0 "Inactive" 1 "Active" ;
VAL_ 715 ACCATC_SplREngInpR 1 "true" 0 "false" ;
VAL_ 715 ACCATC_DrvAstdGoSt 2 "Apply Acc Pedal or Resume Sw To Go" 1 "Apply Accel Pedal to Go" 0 "Not Stopped" ;
VAL_ 715 ACCATC_ACCTyp 2 "Full Speed Range ACC with Booster" 1 "Full Speed Range ACC" 0 "Adaptive Cruise Control" ;
VAL_ 715 ACCATC_ACCAct 1 "true" 0 "false" ;
VAL_ 320 Ky_IdDevPrgmAuthReq 1 "true" 0 "false" ;
VAL_ 320 ClmnLckStatV 1 "Invalid" 0 "Valid" ;
VAL_ 320 ClmnLckStat 2 "Locked unsuccessful" 1 "Unlocked" 0 "Locked" 3 "Unlocked unsuccessful" ;
VAL_ 320 AutoBmSlctAllwd 1 "true" 0 "false" ;
VAL_ 320 BrkLtsAtv 1 "true" 0 "false" ;
VAL_ 320 RrFogLmpsAct 1 "true" 0 "false" ;
VAL_ 320 OtsdAmbtLtLvlStatV 1 "Invalid" 0 "Valid" ;
VAL_ 320 OtsdAmbtLtLvlStat 2 "Day" 1 "Night" 0 "Unknown" ;
VAL_ 320 MainLghtSw 3 "HEADLAMP" 2 "PARKLAMP" 1 "OFF" 0 "AUTO" ;
VAL_ 320 LowBmAct 1 "true" 0 "false" ;
VAL_ 320 HighBmAct 1 "true" 0 "false" ;
VAL_ 320 HdlmpBmSelectStat 2 "High Beams" 1 "Low Beams" 0 "Unknown" ;
VAL_ 320 FlToPsSwAtv 1 "true" 0 "false" ;
VAL_ 320 AdvFrntLghtSysEnbld 1 "true" 0 "false" ;
VAL_ 320 FrFogLmpsAct 1 "true" 0 "false" ;
VAL_ 320 AutLghtCtrl 1 "true" 0 "false" ;
VAL_ 320 TrnSwAct 2 "Right" 1 "Left" 0 "No Activation" ;
VAL_ 499 OvrdrvDsblReqd 1 "true" 0 "false" ;
VAL_ 499 PTShftPtrnOvrdAct 1 "true" 0 "false" ;
VAL_ 499 PFTrnsTUDSecSwSt 3 "Illegal Up/Down Switch State Active" 2 "Decrement Switch Active" 1 "Increment Switch Active" 0 "No Activation" ;
VAL_ 499 PFTrnsTUDSwSt 3 "Illegal Up/Down Switch State Active" 2 "Decrement Switch Active" 1 "Increment Switch Active" 0 "No Activation" ;
VAL_ 499 PFTrnsTUDEnSwSt 3 "Illegal Enable Switch State" 2 "Electronic Range Select Enable Sw" 1 "Driver Shift Control Enable Switch" 0 "No Activation" ;
VAL_ 499 TrnsPFShftPattSw4Act 1 "true" 0 "false" ;
VAL_ 499 TrnsPFShftPattSw3Act 1 "true" 0 "false" ;
VAL_ 499 TrnsPFShftPattSw2Act 1 "true" 0 "false" ;
VAL_ 499 TrnsPFShftPattSw1Act 1 "true" 0 "false" ;
VAL_ 880 FOAI_VehAhdIndRq 0 "No Alert" 1 "Alert Level 1" 2 "Alert Level 2" 3 "Alert Level 3" ;
VAL_ 880 FOAI_AlrtWrnIndRq 0 "No Alert" 1 "Alert Level 1" 2 "Alert Level 2" 3 "Alert Level 3" ;
VAL_ 880 FOAI_AlrtChmIhbRq 0 "Allow Chime" 1 "Inhibit Chime" ;
VAL_ 880 FwdClnAlrtPr 1 "true" 0 "false" ;
VAL_ 880 ACCUnavlbleDTWthrIO 1 "true" 0 "false" ;
VAL_ 880 DrvThrtlOvrdIO 1 "true" 0 "false" ;
VAL_ 880 ServAdpCrsCtrlIndOn 1 "true" 0 "false" ;
VAL_ 880 ACCHdwayStngIO 1 "true" 0 "false" ;
VAL_ 880 ACCHdwyStg 7 "Headway Setting 7" 6 "Headway Setting 6" 5 "Headway Setting 5" 4 "Headway Setting 4" 3 "Headway Setting 3" 2 "Headway Setting 2" 1 "Headway Setting 1" 0 "Minimum Headway Setting" ;
VAL_ 880 ACCSnsClnRqdIO 1 "true" 0 "false" ;
VAL_ 880 ACCTmpUnavlbleIO 1 "true" 0 "false" ;
VAL_ 880 ACCDrvrSeltdSpdIO 1 "true" 0 "false" ;
VAL_ 880 ACCAct370 1 "true" 0 "false" ;
VAL_ 298 ChmAct 1 "true" 0 "false" ;
VAL_ 298 Ky_IdDevPr 1 "true" 0 "false" ;
VAL_ 298 CrshAlrtDrvrSlctdType 0 "Chime" 1 "Seat" ;
VAL_ 298 PsSbltAtcV 1 "Invalid" 0 "Valid" ;
VAL_ 298 PsSbltAtc 1 "true" 0 "false" ;
VAL_ 298 TrlrBrkDsplyAct 1 "true" 0 "false" ;
VAL_ 298 RdSpdCatType 3 "all speed categories 0 - 50 km/h" 2 "all speed categories 51-80 km/h" 1 "all speed categories 81-130 km/h" 0 "all speed categories > 130 km/h" ;
VAL_ 298 LnCat 3 "Four Or More Lanes" 2 "Two Or Three Lanes" 1 "One lane" 0 "no info available" ;
VAL_ 298 FncRdClass 7 "COLLECTOR" 6 "ALLEY" 5 "ARTERIAL" 4 "HIGHWAY" 3 "PED-MALL" 2 "FREEWAY" 1 "SFREEWAY" 0 "LOCAL (Residential Road)" ;
VAL_ 298 SprtLnRd 1 "true" 0 "false" ;
VAL_ 298 CntrldAccRd 1 "true" 0 "false" ;
VAL_ 298 BldUpArDet 1 "true" 0 "false" ;
VAL_ 298 MpDataAvlbl 1 "true" 0 "false" ;
VAL_ 298 SusCustStngReq 7 "Auto" 6 "Performance Mode 6" 5 "Performance Mode 5" 4 "Performance Mode 4" 3 "Performance Mode 3" 2 "Performance Mode 2" 1 "Performance Mode 1" 0 "No Action" ;
VAL_ 298 StrCustStngReq 7 "Auto" 6 "Performance Mode 6" 5 "Performance Mode 5" 4 "Performance Mode 4" 3 "Performance Mode 3" 2 "Performance Mode 2" 1 "Performance Mode 1" 0 "No Action" ;
VAL_ 298 RstrCustFctrDef 1 "Restore Defaults" 0 "No Action" ;
VAL_ 298 DrvlnCustStngReq 7 "Auto" 6 "Performance Mode 6" 5 "Performance Mode 5" 4 "Performance Mode 4" 3 "Performance Mode 3" 2 "Performance Mode 2" 1 "Performance Mode 1" 0 "No Action" ;
VAL_ 298 ChmMstrVDA 1 "VirtualDeviceAvailable" 0 "VirtualDeviceUnavailable" ;
VAL_ 298 IPCVDA 1 "VirtualDeviceAvailable" 0 "VirtualDeviceUnavailable" ;
VAL_ 298 HeadUpDispVDA 1 "VirtualDeviceAvailable" 0 "VirtualDeviceUnavailable" ;
VAL_ 298 HapticSeatVDA 1 "VirtualDeviceAvailable" 0 "VirtualDeviceUnavailable" ;
VAL_ 298 RRDoorAjarSwAct 1 "true" 0 "false" ;
VAL_ 298 PDAjrSwAtv 1 "true" 0 "false" ;
VAL_ 298 TrlrHWIntrfcVDA 1 "VirtualDeviceAvailable" 0 "VirtualDeviceUnavailable" ;
VAL_ 298 DrId 7 "Unknown" 6 "Driver #7" 5 "Driver #6" 4 "Driver #5" 3 "Driver #4" 2 "Driver #3" 1 "Driver #2" 0 "Driver #1" ;
VAL_ 298 EnrgMgtLdShdRq 4 "Load Shed Level 4" 3 "Load Shed Level 3" 2 "Load Shed Level 2" 1 "Load Shed Level 1" 0 "No Load Shedding" ;
VAL_ 298 TreInfMonSysRstReq 1 "true" 0 "false" ;
VAL_ 298 HUDActv 1 "true" 0 "false" ;
VAL_ 298 RLDoorAjarSwAct 1 "true" 0 "false" ;
VAL_ 298 AutoMdSpdLmtCnfrmd 1 "true" 0 "false" ;
VAL_ 298 TCSysDisSwAtv_12A 1 "true" 0 "false" ;
VAL_ 298 DDAjrSwAtvM 0 "Don't Use Data" 1 "Use Data" ;
VAL_ 298 DDAjrSwAtv 1 "true" 0 "false" ;
VAL_ 298 DrSbltAtcV 1 "Invalid" 0 "Valid" ;
VAL_ 298 TrlrHtchSwAtv 1 "true" 0 "false" ;
VAL_ 298 BatVltV 1 "Invalid" 0 "Valid" ;
VAL_ 298 DrSbltAtc 1 "true" 0 "false" ;
VAL_ 485 StrWhAngGrdV 1 "Invalid" 0 "Valid" ;
VAL_ 485 StrWhlAngSenCalStat 2 "Calibrated" 1 "Estimated" 0 "Unknown" ;
VAL_ 485 StrWhAngV 1 "Invalid" 0 "Valid" ;
VAL_ 485 StrWhAngGrdMsk 0 "Don't Use Data" 1 "Use Data" ;
VAL_ 485 StrWhAngMsk 0 "Don't Use Data" 1 "Use Data" ;
VAL_ 485 StrWhlAngSenTyp 0 "Type 1" 1 "Type 2" 2 "Type 3" 3 "Type 4" ;
VAL_ 1241 FSERDTC_SysDes 15 "U3-Network Codes Reserved" 14 "U2-Network Codes Reserved" 13 "U1-Network Codes MFG Controlled" 12 "U0-Network Codes SAE Controlled" 11 "B3-Body Codes Reserved" 10 "B2-Body Codes Reserved" 9 "B1-Body Codes MFG Controlled" 8 "B0-Body Codes SAE Controlled" 7 "C3-Chassis Codes Reserved" 6 "C2-Chassis Codes Reserved" 5 "C1-Chassis Codes MFG Controlled" 4 "C0-Chassis Codes SAE Controlled" 3 "P3-Powertrain Codes Reserved" 2 "P2-Powertrain Codes Reserved" 1 "P1-Powertrain Codes MFG Controlled" 0 "P0-Powertrain Codes SAE Controlled" ;
VAL_ 1241 FuelSysEmsRldMlfAtv 1 "true" 0 "false" ;
VAL_ 491 ExhPrsRgVlv2Pos 0 "Open" 1 "Closed" ;
VAL_ 491 ExhPrsRgVlv2PosV 1 "Invalid" 0 "Valid" ;
VAL_ 491 ExhPrsRgVlvPosV 1 "Invalid" 0 "Valid" ;
VAL_ 491 ExhPrsRgVlvPos 1 "Closed" 0 "Open" ;
VAL_ 491 FuelSysEstPressDlvrdV 1 "Invalid" 0 "Valid" ;
VAL_ 409 TDslPrtFltrIdlRgtnMdAtv 1 "true" 0 "false" ;
VAL_ 409 TTRLT_TqRdnRlznSgg 3 "Stability Optimized 2" 2 "Stability Optimized 1" 1 "Transient Optimized" 0 "No Suggestion" ;
VAL_ 409 TTRLT_TorqInvntnTyp 2 "Minimum Limit" 1 "Maximum Limit" 0 "No Intervention" ;
VAL_ 409 TTRST_TorqInvntnTyp 1 "Maximum Limit" 0 "No Intervention" ;
VAL_ 413 TrnsCyDactTransStat 2 "Ready for Half of TotalCylinders" 1 "Ready for All Cylinders" 0 "Not Ready" ;
VAL_ 413 EngBrkDsblReqd 1 "true" 0 "false" ;
VAL_ 413 TransNtrlCntrlMdStat 3 "Exiting Neutral Control" 2 "Neutral Control Active" 1 "Entering Neutral Control" 0 "Neutral Control Not Active" ;
VAL_ 413 TrnsRtoCntlSysFlt 1 "true" 0 "false" ;
VAL_ 413 TrnTrbAngVlV 1 "Invalid" 0 "Valid" ;
VAL_ 413 TrnGrRatV 1 "Invalid" 0 "Valid" ;
VAL_ 413 TrnPrfAlgShfAtv 1 "true" 0 "false" ;
VAL_ 413 TESR_EngSpdCntlRsp 3 "Stability Optimized Condition 2" 2 "Stability Optimized Condition 1" 1 "Transient Optimized" 0 "No Suggestion" ;
VAL_ 413 TESR_EngSpdIntTyp 3 "Engine Speed Max and Min Limit" 2 "Engine Speed Min Limit" 1 "Engine Speed Max Limit" 0 "No Intervention" ;
VAL_ 413 TrnsGrgShftAct 1 "true" 0 "false" ;
SIG_GROUP_ 423 TransCltchFltStat 1 : TCFS_Cltch5FltStat TCFS_Cltch4FltStat TCFS_Cltch3FltStat TCFS_Cltch2FltStat TCFS_Cltch1FltStat;
SIG_GROUP_ 423 TransCltchAvlbltyStat 1 : TCAS_Cltch5AvlbltyStat TCAS_Cltch4AvlbltyStat TCAS_Cltch3AvlbltyStat TCAS_Cltch2AvlbltyStat TCAS_Cltch1AvlbltyStat;
SIG_GROUP_ 1919 DTCInfo_77F 1 : DTCI_DTCFaultType_77F DTCI_CodeSupported_77F DTCI_CurrentStatus_77F DTCI_TstNPsdCdClrdSt_77F DTCI_TstFldCdClrdStat_77F DTCI_HistStat_77F DTCI_TstNPsdPwrUpSt_77F DTCI_TstFldPwrUpSt_77F DTCI_WrnIndRqdSt_77F DTCI_DTCFailType_77F DTCI_DTCNumber_77F DTCI_DTCSource_77F DTCI_DTCTriggered_77F DTCIUnused7_77F DTCIUnused6_77F DTCIUnused5_77F DTCIUnused4_77F DTCIUnused3_77F DTCIUnused2_77F DTCIUnused1_77F;
SIG_GROUP_ 1273 BrkSysCtl1EmnsRelDTC 1 : BSC1ERDTC_CdNum BSC1ERDTC_SysDes;
SIG_GROUP_ 753 ElecBrkCntlMdlDiagSt2 1 : EBCMDS2_DTCStatus EBCMDS2_DTCIndex;
SIG_GROUP_ 753 ElecBrkCntlMdlDiagSt1 1 : EBCMDS1_DTCStatus EBCMDS1_DTCIndex;
SIG_GROUP_ 753 ElecBrkCntlMdlDiagSt5 1 : EBCMDS5_DTCStatus EBCMDS5_DTCIndex;
SIG_GROUP_ 753 ElecBrkCntlMdlDiagSt4 1 : EBCMDS4_DTCStatus EBCMDS4_DTCIndex;
SIG_GROUP_ 753 ElecBrkCntlMdlDiagSt3 1 : EBCMDS3_DTCStatus EBCMDS3_DTCIndex;
SIG_GROUP_ 1243 ChsSysEmmRelDTC 1 : CSERDTC_CdNum CSERDTC_SysDes;
SIG_GROUP_ 508 ChsSysTtlBrkAxleTrqSt 1 : CSTBATS_TrqVl CSTBATS_TrqVlV;
SIG_GROUP_ 971 BattCrntHiRes 1 : BCHR_BattCrntRwVal BCHR_BattCrntRwVlMu BCHR_BattCrntRwValV;
SIG_GROUP_ 454 ChsSysPrdAxlTqRq 1 : CSPATR_TrqIntrvnTyp CSPATR_PrdTrqRqVal CSPATR_TrqRqTyp;
SIG_GROUP_ 1189 TransAirFlwReq 1 : TAFR_AirFlwReqTyp TAFR_AirFlwReqPrcnt;
SIG_GROUP_ 421 HybTransGrReq 1 : HTGR_ReqVal HTGR_ReqTyp HTGR_ReqPrty;
SIG_GROUP_ 421 HybTrqCnvCltReq 1 : HTCCR_ReqVal HTCCR_ReqPrty;
SIG_GROUP_ 456 PerfTrcEngSpdReq 1 : PTESR_EngSpdRqVal PTESR_EngSpdCntlRs PTESR_EngSpdIntTyp;
SIG_GROUP_ 456 PerfTrcTrqRq 1 : PTTR_TrqReqVal PTTR_TrqRedRlzSugg PTTR_TrqInvTyp;
SIG_GROUP_ 393 TrnsImDrlCrnksftTrqRq 1 : TIDCTR_TrqIntvTyp TIDCTR_TrqReqVal TIDCTR_TrqRespTyp;
SIG_GROUP_ 393 TrnsPrdCrkshftTrqRq 1 : TPCTR_TorqReqVal TPCTR_TrqIntrvnTyp;
SIG_GROUP_ 199 TransOutputRotStat 1 : TORSTimestamp TORSPulsCntr TORSValidity TORSRstOcrd TORSLstTransType TORSRotDir;
SIG_GROUP_ 390 HybEngStStpInfo 1 : HESSI_EngStrtTyp HESSI_EngStrtStpMd;
SIG_GROUP_ 460 SecAxlMaxDifVelLm 1 : SAMDVLReqVal SAMDVLAtv;
SIG_GROUP_ 719 RrVrtlBmpAxlTrqCmd 1 : RVBATC_AxlTrqRqstAct RVBATC_AxlTrqRqst;
SIG_GROUP_ 717 ColPrSysAxlTrqCmd 1 : CPSATC_AxlTrqRqstAct CPSATC_AxlTrqRqst;
SIG_GROUP_ 1105 NoEvSevSt 1 : NESSRoSevSt NESSRiSiSevSt NESSReImpSevSt NESSLeSiSevSt NESSFrImpSt2SevSt NESSFrImpSt1SevSt NESSFrImpPreSevSt;
SIG_GROUP_ 715 ACCAxlTrqCmd 1 : ACCATC_SplREngInpR ACCATC_DrvAstdGoSt ACCATC_AxlTrqRq ACCATC_ACCTyp ACCATC_ACCAct;
SIG_GROUP_ 880 FwdObjAlrtInd 1 : FOAI_VehAhdIndRq FOAI_AlrtWrnIndRq FOAI_AlrtChmIhbRq;
SIG_GROUP_ 1241 FuelSysEmnsRelDTC 1 : FSERDTC_CdNum FSERDTC_SysDes;
SIG_GROUP_ 409 TransTorqReqLngTrm 1 : TTRLT_TorqReqVal TTRLT_TqRdnRlznSgg TTRLT_TorqInvntnTyp;
SIG_GROUP_ 409 TransTorqReqShrtTrm 1 : TTRST_TorqReqVal TTRST_TorqInvntnTyp;
SIG_GROUP_ 413 TrnsEngSpdRq 1 : TESR_EngSpdCntlRsp TESR_EngSpdRqVal TESR_EngSpdIntTyp;
